VERSION "HNNBNNNYNNNNNNNNNNNNNNNNNNNNNNNNNNNNNNNNNN/4/%%%/4/'%**4NNN///"

NS_ :

BS_:

BU_: Allrad_Haldex AreaView_MQB BAP_Tester Bremse_ABS_MK100 Bremse_ESP_EPB_EBC460Vi Bremse_ESP_EPB_MK100 Bremse_ESP_MK100 Daempfer Gateway_MQB Lenkhilfe_EPS PDC PDC_PLA

BO_ 779 Kombi_01: 8 Gateway_MQB
 SG_ KBI_ABS_Lampe : 0|1@1+ (1.0,0.0) [0.0|1] ""  Bremse_ABS_MK100,Bremse_ESP_EPB_EBC460Vi,Bremse_ESP_EPB_MK100,Bremse_ESP_MK100
 SG_ KBI_ESP_Lampe : 1|1@1+ (1.0,0.0) [0.0|1] ""  Bremse_ABS_MK100,Bremse_ESP_EPB_EBC460Vi,Bremse_ESP_EPB_MK100,Bremse_ESP_MK100
 SG_ KBI_BKL_Lampe : 2|1@1+ (1.0,0.0) [0.0|1] ""  Bremse_ABS_MK100,Bremse_ESP_EPB_EBC460Vi,Bremse_ESP_EPB_MK100,Bremse_ESP_MK100
 SG_ KBI_Airbag_Lampe : 3|1@1+ (1.0,0.0) [0.0|1] ""  Vector__XXX
 SG_ KBI_SILA_gueltig : 4|1@1+ (1.0,0.0) [0.0|1] ""  Bremse_ABS_MK100,Bremse_ESP_EPB_EBC460Vi,Bremse_ESP_EPB_MK100,Bremse_ESP_MK100,Lenkhilfe_EPS
 SG_ KBI_Lenkung_Lampe : 5|1@1+ (1,0) [0|1] ""  Lenkhilfe_EPS
 SG_ KBI_Vorglueh_System_Lampe : 6|1@1+ (1.0,0.0) [0.0|1] ""  Vector__XXX
 SG_ KBI_NV_in_Anzeige : 7|1@1+ (1.0,0.0) [0.0|1] ""  Vector__XXX
 SG_ Kombi_01_BZ : 8|4@1+ (1,0) [0|15] ""  Vector__XXX
 SG_ KBI_Anzeigestatus_ACC : 12|1@1+ (1.0,0.0) [0.0|1] ""  Vector__XXX
 SG_ KBI_Anzeigestatus_GRA : 13|2@1+ (1.0,0.0) [0.0|3] ""  Vector__XXX
 SG_ KBI_Oeldruck_Schalter : 15|1@1+ (1.0,0.0) [0.0|1] ""  Vector__XXX
 SG_ KBI_Tankwarnung : 16|1@1+ (1.0,0.0) [0.0|1] ""  Vector__XXX
 SG_ KBI_MFA_v_Einheit_01 : 17|1@1+ (1.0,0.0) [0.0|1] ""  Vector__XXX
 SG_ KBI_im_Stellgliedtest : 18|1@1+ (1.0,0.0) [0.0|1] ""  Lenkhilfe_EPS
 SG_ KBI_Anzeigefehler_LDW : 19|2@1+ (1.0,0.0) [0.0|3] ""  Vector__XXX
 SG_ KBI_Oeldruckwarnung : 22|1@1+ (1.0,0.0) [0.0|1] ""  Vector__XXX
 SG_ KBI_Handbremse : 23|1@1+ (1.0,0.0) [0.0|1] ""  Allrad_Haldex,Bremse_ABS_MK100,Bremse_ESP_EPB_EBC460Vi,Bremse_ESP_EPB_MK100,Bremse_ESP_MK100,Lenkhilfe_EPS
 SG_ KBI_V_Digital : 24|9@1+ (1,0) [0|511] ""  Vector__XXX
 SG_ KBI_PLA_in_Anzeige : 33|1@1+ (1.0,0.0) [0.0|1] ""  PDC_PLA
 SG_ KBI_Anzeigefehler_NV : 34|1@1+ (1.0,0.0) [0.0|1] ""  Vector__XXX
 SG_ KBI_Anzeigestatus_LIM : 35|2@1+ (1.0,0.0) [0.0|3] ""  Vector__XXX
 SG_ KBI_ARA_in_Anzeige : 37|1@1+ (1.0,0.0) [0.0|1] ""  Vector__XXX
 SG_ KBI_angez_Geschw : 48|10@1+ (0.32,0) [0.00|325.12] "Unit_KiloMeterPerHour"  Lenkhilfe_EPS
 SG_ KBI_Einheit_Tacho : 58|1@1+ (1.0,0.0) [0.0|1] ""  Vector__XXX
 SG_ KBI_Konsistenz_ACC : 59|1@1+ (1.0,0.0) [0.0|1] ""  Vector__XXX
 SG_ KBI_Fehler_Anzeige_ACC : 60|1@1+ (1.0,0.0) [0.0|1] ""  Vector__XXX
 SG_ KBI_Anzeigefehler_SWA : 61|2@1+ (1.0,0.0) [0.0|3] ""  Vector__XXX

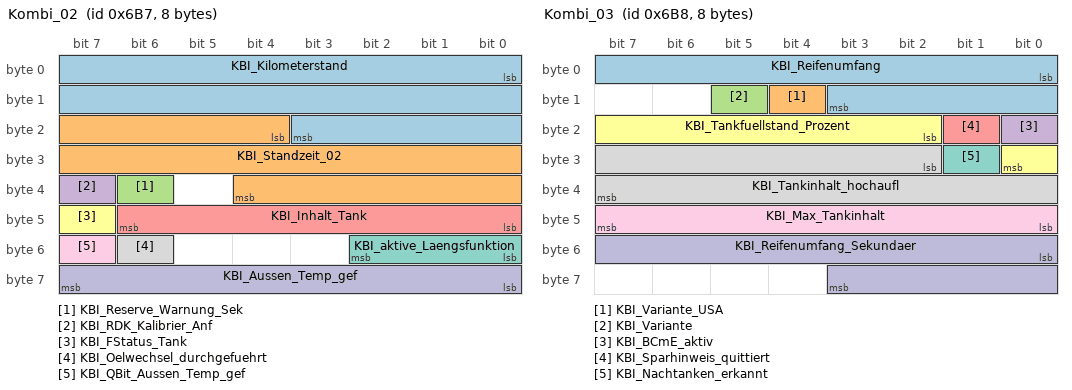
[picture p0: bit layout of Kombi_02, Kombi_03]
BO_ 1719 Kombi_02: 8 Gateway_MQB
 SG_ KBI_Kilometerstand : 0|20@1+ (1,0) [0|1048573] "Unit_KiloMeter"  Vector__XXX
 SG_ KBI_Standzeit_02 : 20|17@1+ (1,0) [0|131068] "Unit_Secon"  Allrad_Haldex,Bremse_ESP_EPB_EBC460Vi,Bremse_ESP_EPB_MK100,Bremse_ESP_MK100
 SG_ KBI_Reserve_Warnung_Sek : 38|1@1+ (1.0,0.0) [0.0|1] ""  Vector__XXX
 SG_ KBI_RDK_Kalibrier_Anf : 39|1@1+ (1.0,0.0) [0.0|1] ""  Vector__XXX
 SG_ KBI_Inhalt_Tank : 40|7@1+ (1,0) [0|125] "Unit_Liter"  Vector__XXX
 SG_ KBI_FStatus_Tank : 47|1@1+ (1.0,0.0) [0.0|1] ""  Vector__XXX
 SG_ KBI_aktive_Laengsfunktion : 48|3@1+ (1.0,0.0) [0.0|7] ""  Vector__XXX
 SG_ KBI_Oelwechsel_durchgefuehrt : 54|1@1+ (1.0,0.0) [0.0|1] ""  Vector__XXX
 SG_ KBI_QBit_Aussen_Temp_gef : 55|1@1+ (1.0,0.0) [0.0|1] ""  Bremse_ABS_MK100,Bremse_ESP_EPB_EBC460Vi,Bremse_ESP_EPB_MK100,Bremse_ESP_MK100,PDC,PDC_PLA
 SG_ KBI_Aussen_Temp_gef : 56|8@1+ (0.5,-50) [-50.0|75.0] "Unit_DegreCelsi"  Bremse_ABS_MK100,Bremse_ESP_EPB_EBC460Vi,Bremse_ESP_EPB_MK100,Bremse_ESP_MK100,PDC,PDC_PLA

BO_ 1720 Kombi_03: 8 Gateway_MQB
 SG_ KBI_Reifenumfang : 0|12@1+ (1,0) [0|4095] "Unit_MilliMeter"  Bremse_ABS_MK100,Bremse_ESP_EPB_EBC460Vi,Bremse_ESP_EPB_MK100,Bremse_ESP_MK100,PDC,PDC_PLA
 SG_ KBI_Variante_USA : 12|1@1+ (1.0,0.0) [0.0|1] ""  Vector__XXX
 SG_ KBI_Variante : 13|1@1+ (1.0,0.0) [0.0|1] ""  Vector__XXX
 SG_ KBI_BCmE_aktiv : 16|1@1+ (1.0,0.0) [0.0|1] ""  Vector__XXX
 SG_ KBI_Sparhinweis_quittiert : 17|1@1+ (1.0,0.0) [0.0|1] ""  Vector__XXX
 SG_ KBI_Tankfuellstand_Prozent : 18|7@1+ (1,0) [0|100] "Unit_PerCent"  Vector__XXX
 SG_ KBI_Nachtanken_erkannt : 25|1@1+ (1.0,0.0) [0.0|1] ""  Vector__XXX
 SG_ KBI_Tankinhalt_hochaufl : 26|14@1+ (0.01,0) [0.00|163.81] "Unit_Liter"  Vector__XXX
 SG_ KBI_Max_Tankinhalt : 40|8@1+ (0.5,0) [0.0|126.5] ""  Vector__XXX
 SG_ KBI_Reifenumfang_Sekundaer : 48|12@1+ (1,0) [0|4095] "Unit_MilliMeter"  Vector__XXX

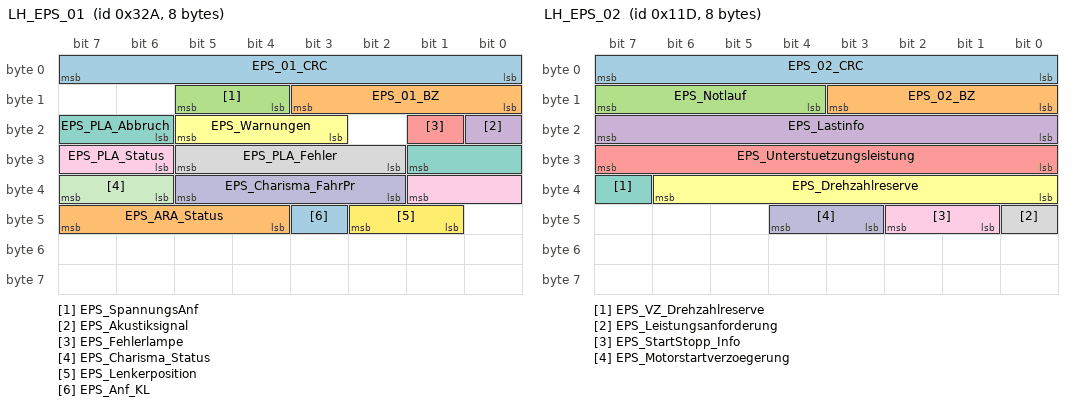
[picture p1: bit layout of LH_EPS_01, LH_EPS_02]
BO_ 810 LH_EPS_01: 8 Lenkhilfe_EPS
 SG_ EPS_01_CRC : 0|8@1+ (1,0) [0|255] ""  Bremse_ESP_EPB_EBC460Vi,Bremse_ESP_EPB_MK100,Bremse_ESP_MK100,Gateway_MQB,PDC,PDC_PLA
 SG_ EPS_01_BZ : 8|4@1+ (1,0) [0|15] ""  Bremse_ESP_EPB_EBC460Vi,Bremse_ESP_EPB_MK100,Bremse_ESP_MK100,Gateway_MQB,PDC,PDC_PLA
 SG_ EPS_SpannungsAnf : 12|2@1+ (1.0,0.0) [0.0|3] ""  Gateway_MQB
 SG_ EPS_Akustiksignal : 16|1@1+ (1.0,0.0) [0.0|1] ""  Gateway_MQB
 SG_ EPS_Fehlerlampe : 17|1@1+ (1.0,0.0) [0.0|1] ""  Gateway_MQB
 SG_ EPS_Warnungen : 19|3@1+ (1.0,0.0) [0.0|7] ""  Gateway_MQB
 SG_ EPS_PLA_Abbruch : 22|4@1+ (1,0) [0|15] ""  Gateway_MQB,PDC_PLA
 SG_ EPS_PLA_Fehler : 26|4@1+ (1,0) [0|15] ""  Gateway_MQB,PDC_PLA
 SG_ EPS_PLA_Status : 30|4@1+ (1.0,0.0) [0.0|15] ""  Bremse_ESP_EPB_EBC460Vi,Bremse_ESP_EPB_MK100,Bremse_ESP_MK100,Gateway_MQB,PDC_PLA
 SG_ EPS_Charisma_FahrPr : 34|4@1+ (1.0,0.0) [0.0|15] ""  Gateway_MQB
 SG_ EPS_Charisma_Status : 38|2@1+ (1.0,0.0) [0.0|3] ""  Gateway_MQB
 SG_ EPS_Lenkerposition : 41|2@1+ (1.0,0.0) [0.0|3] ""  Bremse_ESP_EPB_EBC460Vi,Bremse_ESP_EPB_MK100,Bremse_ESP_MK100,Gateway_MQB
 SG_ EPS_Anf_KL : 43|1@1+ (1.0,0.0) [0.0|1] ""  Gateway_MQB
 SG_ EPS_ARA_Status : 44|4@1+ (1.0,0.0) [0.0|15] ""  Gateway_MQB

BO_ 285 LH_EPS_02: 8 Lenkhilfe_EPS
 SG_ EPS_02_CRC : 0|8@1+ (1,0) [0|255] ""  Vector__XXX
 SG_ EPS_02_BZ : 8|4@1+ (1,0) [0|15] ""  Vector__XXX
 SG_ EPS_Notlauf : 12|4@1+ (1.0,0.0) [0.0|15] ""  Gateway_MQB
 SG_ EPS_Lastinfo : 16|8@1+ (1,0) [0|253] "Unit_Amper"  Gateway_MQB,PDC_PLA
 SG_ EPS_Unterstuetzungsleistung : 24|8@1+ (0.5,0) [0.0|100.0] "Unit_PerCent"  Gateway_MQB,PDC_PLA
 SG_ EPS_Drehzahlreserve : 32|7@1+ (10,0) [0|1000] "Unit_DegreOfArcPerSecon"  Vector__XXX
 SG_ EPS_VZ_Drehzahlreserve : 39|1@1+ (1.0,0.0) [0.0|1] ""  Vector__XXX
 SG_ EPS_Leistungsanforderung : 40|1@1+ (1.0,0.0) [0.0|1] ""  Vector__XXX
 SG_ EPS_StartStopp_Info : 41|2@1+ (1.0,0.0) [0.0|3] ""  Gateway_MQB
 SG_ EPS_Motorstartverzoegerung : 43|2@1+ (1.0,0.0) [0.0|3] ""  Vector__XXX

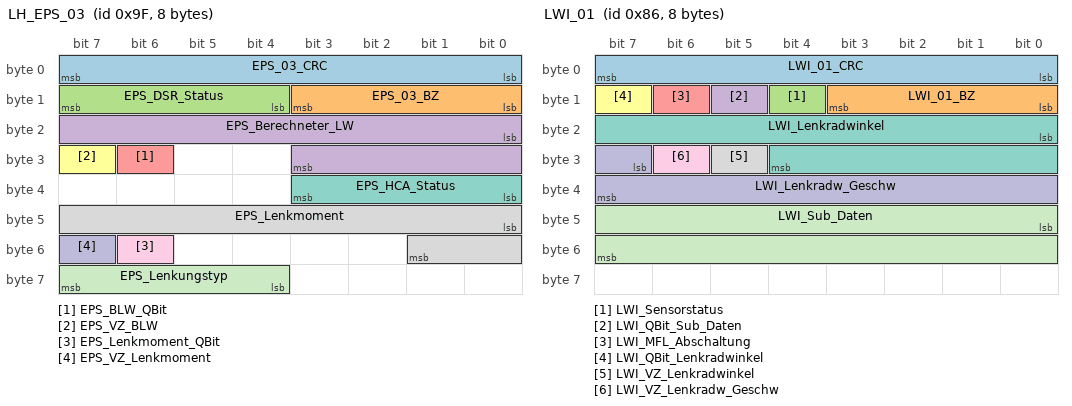
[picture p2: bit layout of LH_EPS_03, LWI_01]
BO_ 159 LH_EPS_03: 8 Lenkhilfe_EPS
 SG_ EPS_03_CRC : 0|8@1+ (1,0) [0|255] ""  Bremse_ABS_MK100,Bremse_ESP_EPB_EBC460Vi,Bremse_ESP_EPB_MK100,Bremse_ESP_MK100,Gateway_MQB,PDC_PLA
 SG_ EPS_03_BZ : 8|4@1+ (1,0) [0|15] ""  Bremse_ABS_MK100,Bremse_ESP_EPB_EBC460Vi,Bremse_ESP_EPB_MK100,Bremse_ESP_MK100,Gateway_MQB,PDC,PDC_PLA
 SG_ EPS_DSR_Status : 12|4@1+ (1.0,0.0) [0.0|15] ""  Bremse_ABS_MK100,Bremse_ESP_EPB_EBC460Vi,Bremse_ESP_EPB_MK100,Bremse_ESP_MK100,Gateway_MQB
 SG_ EPS_Berechneter_LW : 16|12@1+ (0.15,0) [0.00|613.95] "Unit_DegreOfArc"  Bremse_ESP_EPB_EBC460Vi,Bremse_ESP_EPB_MK100,Bremse_ESP_MK100,Gateway_MQB,PDC,PDC_PLA
 SG_ EPS_BLW_QBit : 30|1@1+ (1.0,0.0) [0.0|1] ""  Bremse_ESP_EPB_EBC460Vi,Bremse_ESP_EPB_MK100,Bremse_ESP_MK100,Gateway_MQB,PDC,PDC_PLA
 SG_ EPS_VZ_BLW : 31|1@1+ (1.0,0.0) [0.0|1] ""  Bremse_ESP_EPB_EBC460Vi,Bremse_ESP_EPB_MK100,Bremse_ESP_MK100,Gateway_MQB,PDC,PDC_PLA
 SG_ EPS_HCA_Status : 32|4@1+ (1.0,0.0) [0.0|15] ""  Gateway_MQB
 SG_ EPS_Lenkmoment : 40|10@1+ (0.01,0) [0.00|8.00] "Unit_NewtoMeter"  AreaView_MQB,Bremse_ABS_MK100,Bremse_ESP_EPB_EBC460Vi,Bremse_ESP_EPB_MK100,Bremse_ESP_MK100,Gateway_MQB,PDC,PDC_PLA
 SG_ EPS_Lenkmoment_QBit : 54|1@1+ (1.0,0.0) [0.0|1] ""  AreaView_MQB,Bremse_ABS_MK100,Bremse_ESP_EPB_EBC460Vi,Bremse_ESP_EPB_MK100,Bremse_ESP_MK100,Gateway_MQB,PDC,PDC_PLA
 SG_ EPS_VZ_Lenkmoment : 55|1@1+ (1.0,0.0) [0.0|1] ""  AreaView_MQB,Bremse_ABS_MK100,Bremse_ESP_EPB_EBC460Vi,Bremse_ESP_EPB_MK100,Bremse_ESP_MK100,Gateway_MQB,PDC,PDC_PLA
 SG_ EPS_Lenkungstyp : 60|4@1+ (1.0,0.0) [0.0|15] ""  Bremse_ABS_MK100,Bremse_ESP_EPB_EBC460Vi,Bremse_ESP_EPB_MK100,Bremse_ESP_MK100,Gateway_MQB,PDC,PDC_PLA

BO_ 134 LWI_01: 8 Lenkhilfe_EPS
 SG_ LWI_01_CRC : 0|8@1+ (1,0) [0|255] ""  Bremse_ABS_MK100,Bremse_ESP_EPB_EBC460Vi,Bremse_ESP_EPB_MK100,Bremse_ESP_MK100,Gateway_MQB,PDC,PDC_PLA
 SG_ LWI_01_BZ : 8|4@1+ (1,0) [0|15] ""  Allrad_Haldex,Bremse_ABS_MK100,Bremse_ESP_EPB_EBC460Vi,Bremse_ESP_EPB_MK100,Bremse_ESP_MK100,Gateway_MQB,PDC,PDC_PLA
 SG_ LWI_Sensorstatus : 12|1@1+ (1.0,0.0) [0.0|1] ""  Allrad_Haldex,Bremse_ABS_MK100,Bremse_ESP_EPB_EBC460Vi,Bremse_ESP_EPB_MK100,Bremse_ESP_MK100,Daempfer,Gateway_MQB
 SG_ LWI_QBit_Sub_Daten : 13|1@1+ (1.0,0.0) [0.0|1] ""  Gateway_MQB
 SG_ LWI_MFL_Abschaltung : 14|1@1+ (1.0,0.0) [0.0|1] ""  Gateway_MQB
 SG_ LWI_QBit_Lenkradwinkel : 15|1@1+ (1.0,0.0) [0.0|1] ""  Allrad_Haldex,AreaView_MQB,Bremse_ABS_MK100,Bremse_ESP_EPB_EBC460Vi,Bremse_ESP_EPB_MK100,Bremse_ESP_MK100,Daempfer,Gateway_MQB,PDC,PDC_PLA
 SG_ LWI_Lenkradwinkel : 16|13@1+ (0.1,0) [0.0|800.0] "Unit_DegreOfArc"  Allrad_Haldex,AreaView_MQB,Bremse_ABS_MK100,Bremse_ESP_EPB_EBC460Vi,Bremse_ESP_EPB_MK100,Bremse_ESP_MK100,Daempfer,Gateway_MQB,PDC,PDC_PLA
 SG_ LWI_VZ_Lenkradwinkel : 29|1@1+ (1.0,0.0) [0.0|1] ""  Allrad_Haldex,AreaView_MQB,Bremse_ABS_MK100,Bremse_ESP_EPB_EBC460Vi,Bremse_ESP_EPB_MK100,Bremse_ESP_MK100,Daempfer,Gateway_MQB,PDC,PDC_PLA
 SG_ LWI_VZ_Lenkradw_Geschw : 30|1@1+ (1.0,0.0) [0.0|1] ""  Bremse_ABS_MK100,Bremse_ESP_EPB_EBC460Vi,Bremse_ESP_EPB_MK100,Bremse_ESP_MK100,Gateway_MQB
 SG_ LWI_Lenkradw_Geschw : 31|9@1+ (5,0) [0|2500] "Unit_DegreOfArcPerSecon"  Bremse_ABS_MK100,Bremse_ESP_EPB_EBC460Vi,Bremse_ESP_EPB_MK100,Bremse_ESP_MK100,Gateway_MQB
 SG_ LWI_Sub_Daten : 40|16@1+ (1,0) [0|65535] ""  Gateway_MQB

BO_ 917 LWR_AFS_01: 8 Gateway_MQB
 SG_ AFS_Abbiegelicht_li_Anf : 0|1@1+ (1.0,0.0) [0.0|1] ""  Vector__XXX
 SG_ AFS_Abbiegelicht_re_Anf : 1|1@1+ (1.0,0.0) [0.0|1] ""  Vector__XXX
 SG_ AFS_Abbiegelicht_Dimm_Anf : 2|1@1+ (1.0,0.0) [0.0|1] ""  Vector__XXX
 SG_ AFS_Verfuegbarkeit_GLW : 3|1@1+ (1.0,0.0) [0.0|1] ""  Vector__XXX
 SG_ AFS_Status_adaptive_LV : 4|1@1+ (1.0,0.0) [0.0|1] ""  Vector__XXX
 SG_ AFS_Fernlicht_li_defekt : 5|1@1+ (1.0,0.0) [0.0|1] ""  Vector__XXX
 SG_ AFS_Fernlicht_re_defekt : 6|1@1+ (1.0,0.0) [0.0|1] ""  Vector__XXX
 SG_ AFS_Fernlicht_Status : 7|1@1+ (1.0,0.0) [0.0|1] ""  Vector__XXX
 SG_ LWR_AFS_01_BZ : 8|4@1+ (1,0) [0|15] ""  Vector__XXX
 SG_ AFS_Lampe : 12|1@1+ (1.0,0.0) [0.0|1] ""  Vector__XXX
 SG_ LWR_Lampe : 13|1@1+ (1.0,0.0) [0.0|1] ""  Vector__XXX
 SG_ AFS_Fehlertext : 14|1@1+ (1.0,0.0) [0.0|1] ""  Vector__XXX
 SG_ AFS_LED_Blinkmode : 15|1@1+ (1.0,0.0) [0.0|1] ""  Vector__XXX
 SG_ LWR_Touristenmodus_aktiv : 16|1@1+ (1.0,0.0) [0.0|1] ""  Vector__XXX
 SG_ AFS_Charisma_FahrPr : 17|4@1+ (1.0,0.0) [0.0|15] ""  Vector__XXX
 SG_ AFS_Charisma_Status : 21|2@1+ (1.0,0.0) [0.0|3] ""  Vector__XXX
 SG_ AFS_Allwetterlicht : 24|1@1+ (1.0,0.0) [0.0|1] ""  Vector__XXX
 SG_ LWR_Touristenmodus_verbaut : 25|1@1+ (1.0,0.0) [0.0|1] ""  Vector__XXX
 SG_ AFS_adaptive_LV_verbaut : 26|1@1+ (1.0,0.0) [0.0|1] ""  Vector__XXX
 SG_ LWR_Reisemodus_Texte : 27|2@1+ (1.0,0.0) [0.0|3] ""  Vector__XXX
 SG_ GLW_Sensor_blockiert : 29|1@1+ (1.0,0.0) [0.0|1] ""  Vector__XXX
 SG_ LWR_Pos_Schrittmotor : 32|8@1+ (0.4,0) [0.0|100.0] "Unit_PerCent"  Vector__XXX
 SG_ LWR_Hoehenwert_VL : 40|8@1+ (1,-127) [-127|126] ""  Bremse_ESP_EPB_EBC460Vi,Bremse_ESP_EPB_MK100,Bremse_ESP_MK100
 SG_ LWR_Hoehenwert_HL : 48|8@1+ (1,-127) [-127|126] ""  Bremse_ESP_EPB_EBC460Vi,Bremse_ESP_EPB_MK100,Bremse_ESP_MK100
 SG_ AFS_Ersatzlicht_Links : 56|1@1+ (1.0,0.0) [0.0|1] ""  Vector__XXX
 SG_ AFS_Ersatzlicht_Rechts : 57|1@1+ (1.0,0.0) [0.0|1] ""  Vector__XXX
 SG_ LWR_AFS_Grundeinstellung : 58|1@1+ (1.0,0.0) [0.0|1] ""  Vector__XXX
 SG_ LWR_AFS_Parametrisierung : 59|1@1+ (1.0,0.0) [0.0|1] ""  Vector__XXX
 SG_ LWR_Initialisierungslauf : 60|1@1+ (1.0,0.0) [0.0|1] ""  Vector__XXX
 SG_ LWR_Sicherheitsposition : 61|1@1+ (1.0,0.0) [0.0|1] ""  Vector__XXX
 SG_ LWR_Modus : 62|1@1+ (1.0,0.0) [0.0|1] ""  Vector__XXX

BO_ 1600 Motor_07: 8 Gateway_MQB
 SG_ MO_QBit_Ansaugluft_Temp : 0|1@1+ (1.0,0.0) [0.0|1] ""  Bremse_ESP_EPB_EBC460Vi,Bremse_ESP_EPB_MK100,Bremse_ESP_MK100
 SG_ MO_QBit_Oel_Temp : 1|1@1+ (1.0,0.0) [0.0|1] ""  Bremse_ESP_EPB_EBC460Vi,Bremse_ESP_EPB_MK100
 SG_ MO_QBit_Kuehlmittel_Temp : 2|1@1+ (1.0,0.0) [0.0|1] ""  Vector__XXX
 SG_ MO_KL15_Abschaltempfehlung : 3|1@1+ (1.0,0.0) [0.0|1] ""  Vector__XXX
 SG_ MO_HYB_Fehler_HV_Netz : 4|1@1+ (1.0,0.0) [0.0|1] ""  Vector__XXX
 SG_ MO_aktives_Getriebeheizen : 5|1@1+ (1.0,0.0) [0.0|1] ""  Vector__XXX
 SG_ MO_Absperrventil_oeffnen : 6|2@1+ (1.0,0.0) [0.0|3] ""  Vector__XXX
 SG_ MO_Ansaugluft_Temp : 8|8@1+ (0.75,-48) [-48.00|141.75] "Unit_DegreCelsi"  Bremse_ESP_EPB_EBC460Vi,Bremse_ESP_EPB_MK100,Bremse_ESP_MK100
 SG_ MO_Oel_Temp : 16|8@1+ (1,-60) [-60|192] "Unit_DegreCelsi"  Bremse_ESP_EPB_EBC460Vi,Bremse_ESP_EPB_MK100
 SG_ MO_Kuehlmittel_Temp : 24|8@1+ (0.75,-48) [-48.00|141.75] "Unit_DegreCelsi"  Vector__XXX
 SG_ MO_Hoeheninfo : 32|8@1+ (0.00781,0) [0.00000|1.98374] ""  Bremse_ABS_MK100,Bremse_ESP_EPB_EBC460Vi,Bremse_ESP_EPB_MK100,Bremse_ESP_MK100
 SG_ MO_Kennfeldk : 40|1@1+ (1.0,0.0) [0.0|1] ""  Vector__XXX
 SG_ MO_Versionsinfo_02 : 41|5@1+ (1.0,0.0) [0.0|31] ""  Vector__XXX
 SG_ MO_QBit_Hoeheninfo : 46|1@1+ (1.0,0.0) [0.0|1] ""  Vector__XXX
 SG_ MO_Getriebe_kuehlen : 47|1@1+ (1.0,0.0) [0.0|1] ""  Vector__XXX
 SG_ MO_Mom_Traegheit_02 : 48|5@1+ (0.01,0) [0.00|0.31] "Unit_KiloGramMeterSquar"  Bremse_ESP_EPB_EBC460Vi,Bremse_ESP_EPB_MK100,Bremse_ESP_MK100
 SG_ MO_Heizungspumpenansteuerung : 53|4@1+ (10,0) [0|100] "Unit_PerCent"  Vector__XXX
 SG_ MO_SpannungsAnf : 57|1@1+ (1.0,0.0) [0.0|1] ""  Vector__XXX
 SG_ MO_Nachlaufzeit_Heizungspumpe : 58|6@1+ (15,0) [0|945] "Unit_Secon"  Vector__XXX

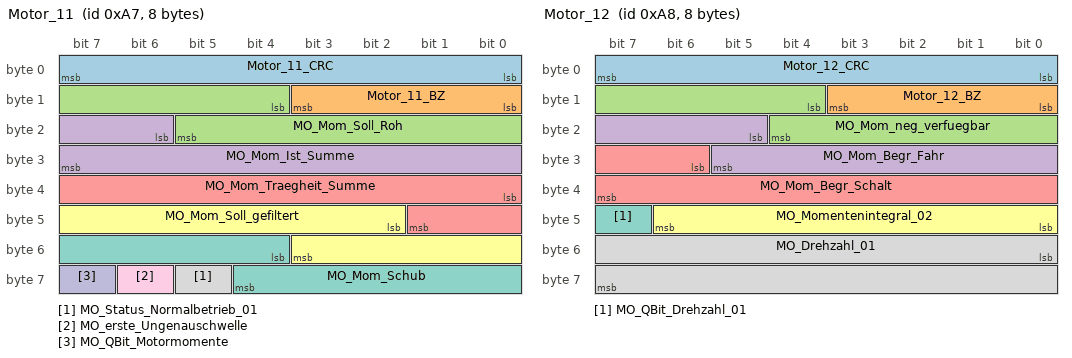
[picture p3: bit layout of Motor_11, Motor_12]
BO_ 167 Motor_11: 8 Gateway_MQB
 SG_ Motor_11_CRC : 0|8@1+ (1,0) [0|255] ""  Bremse_ABS_MK100,Bremse_ESP_EPB_EBC460Vi,Bremse_ESP_EPB_MK100,Bremse_ESP_MK100,Lenkhilfe_EPS
 SG_ Motor_11_BZ : 8|4@1+ (1,0) [0|15] ""  Bremse_ABS_MK100,Bremse_ESP_EPB_EBC460Vi,Bremse_ESP_EPB_MK100,Bremse_ESP_MK100,Lenkhilfe_EPS
 SG_ MO_Mom_Soll_Roh : 12|10@1+ (1,-509) [-509|509] ""  Allrad_Haldex,Bremse_ABS_MK100,Bremse_ESP_EPB_EBC460Vi,Bremse_ESP_EPB_MK100,Bremse_ESP_MK100,Lenkhilfe_EPS
 SG_ MO_Mom_Ist_Summe : 22|10@1+ (1,-509) [-509|509] ""  Allrad_Haldex,Bremse_ABS_MK100,Bremse_ESP_EPB_EBC460Vi,Bremse_ESP_EPB_MK100,Bremse_ESP_MK100,Lenkhilfe_EPS
 SG_ MO_Mom_Traegheit_Summe : 32|10@1+ (1,-509) [-509|509] ""  Bremse_ABS_MK100,Bremse_ESP_EPB_EBC460Vi,Bremse_ESP_EPB_MK100,Bremse_ESP_MK100,Lenkhilfe_EPS
 SG_ MO_Mom_Soll_gefiltert : 42|10@1+ (1,-509) [-509|509] ""  Vector__XXX
 SG_ MO_Mom_Schub : 52|9@1+ (1,-509) [-509|0] ""  Allrad_Haldex,Bremse_ABS_MK100,Bremse_ESP_EPB_EBC460Vi,Bremse_ESP_EPB_MK100,Bremse_ESP_MK100,Lenkhilfe_EPS
 SG_ MO_Status_Normalbetrieb_01 : 61|1@1+ (1.0,0.0) [0.0|1] ""  Allrad_Haldex
 SG_ MO_erste_Ungenauschwelle : 62|1@1+ (1.0,0.0) [0.0|1] ""  Vector__XXX
 SG_ MO_QBit_Motormomente : 63|1@1+ (1.0,0.0) [0.0|1] ""  Bremse_ABS_MK100,Bremse_ESP_EPB_EBC460Vi,Bremse_ESP_EPB_MK100,Bremse_ESP_MK100,Lenkhilfe_EPS

BO_ 168 Motor_12: 8 Gateway_MQB
 SG_ Motor_12_CRC : 0|8@1+ (1,0) [0|255] ""  Bremse_ABS_MK100,Bremse_ESP_EPB_EBC460Vi,Bremse_ESP_EPB_MK100,Bremse_ESP_MK100,Lenkhilfe_EPS
 SG_ Motor_12_BZ : 8|4@1+ (1,0) [0|15] ""  Bremse_ABS_MK100,Bremse_ESP_EPB_EBC460Vi,Bremse_ESP_EPB_MK100,Bremse_ESP_MK100,Lenkhilfe_EPS
 SG_ MO_Mom_neg_verfuegbar : 12|9@1+ (1,-509) [-509|0] ""  Vector__XXX
 SG_ MO_Mom_Begr_Fahr : 21|9@1+ (1,0) [0|509] ""  Bremse_ESP_EPB_MK100,Bremse_ESP_MK100
 SG_ MO_Mom_Begr_Schalt : 30|10@1+ (1,-509) [-509|509] ""  Vector__XXX
 SG_ MO_Momentenintegral_02 : 40|7@1+ (1,0) [0|100] "Unit_PerCent"  Vector__XXX
 SG_ MO_QBit_Drehzahl_01 : 47|1@1+ (1.0,0.0) [0.0|1] ""  Bremse_ABS_MK100,Bremse_ESP_EPB_EBC460Vi,Bremse_ESP_EPB_MK100,Bremse_ESP_MK100,Lenkhilfe_EPS,PDC,PDC_PLA
 SG_ MO_Drehzahl_01 : 48|16@1+ (0.25,0) [0.00|16383.00] "Unit_MinutInver"  Allrad_Haldex,Bremse_ABS_MK100,Bremse_ESP_EPB_EBC460Vi,Bremse_ESP_EPB_MK100,Bremse_ESP_MK100,Lenkhilfe_EPS,PDC_PLA

BO_ 958 Motor_14: 8 Gateway_MQB
 SG_ Motor_14_CRC : 0|8@1+ (1,0) [0|255] ""  Vector__XXX
 SG_ Motor_14_BZ : 8|4@1+ (1,0) [0|15] ""  Vector__XXX
 SG_ MO_StartStopp_Status : 12|2@1+ (1.0,0.0) [0.0|3] ""  Bremse_ESP_EPB_EBC460Vi,Bremse_ESP_EPB_MK100,Bremse_ESP_MK100,Lenkhilfe_EPS,PDC,PDC_PLA
 SG_ MO_StartStopp_Wiederstart : 14|1@1+ (1.0,0.0) [0.0|1] ""  Bremse_ESP_EPB_EBC460Vi,Bremse_ESP_EPB_MK100,Bremse_ESP_MK100,Lenkhilfe_EPS,PDC,PDC_PLA
 SG_ MO_StartStopp_Motorstopp : 15|1@1+ (1.0,0.0) [0.0|1] ""  Bremse_ESP_EPB_EBC460Vi,Bremse_ESP_EPB_MK100,Bremse_ESP_MK100,Lenkhilfe_EPS,PDC_PLA
 SG_ MO_Freig_Reku : 16|2@1+ (1.0,0.0) [0.0|3] ""  Vector__XXX
 SG_ MO_Kl_75 : 18|1@1+ (1.0,0.0) [0.0|1] ""  Bremse_ESP_EPB_EBC460Vi,Bremse_ESP_EPB_MK100,Lenkhilfe_EPS,PDC,PDC_PLA
 SG_ MO_Kl_50 : 19|1@1+ (1.0,0.0) [0.0|1] ""  Bremse_ESP_EPB_EBC460Vi,Bremse_ESP_EPB_MK100,Lenkhilfe_EPS
 SG_ MO_Gangposition : 20|4@1+ (1.0,0.0) [0.0|15] ""  Allrad_Haldex,Bremse_ESP_EPB_EBC460Vi,Bremse_ESP_EPB_MK100
 SG_ MO_StartStopp_Fahrerwunsch : 24|2@1+ (1.0,0.0) [0.0|3] ""  Bremse_ESP_EPB_EBC460Vi,Bremse_ESP_EPB_MK100,Bremse_ESP_MK100,Lenkhilfe_EPS,PDC_PLA
 SG_ MO_HYB_Fahrbereitschaft : 26|1@1+ (1.0,0.0) [0.0|1] ""  Bremse_ESP_EPB_MK100,Lenkhilfe_EPS,PDC_PLA
 SG_ MO_Ext_E_Fahrt_aktiv : 27|1@1+ (1.0,0.0) [0.0|1] ""  Vector__XXX
 SG_ MO_Fahrer_bremst : 28|1@1+ (1.0,0.0) [0.0|1] ""  Allrad_Haldex,Bremse_ESP_EPB_EBC460Vi,Bremse_ESP_EPB_MK100,Bremse_ESP_MK100,PDC_PLA
 SG_ MO_QBit_Fahrer_bremst : 29|1@1+ (1.0,0.0) [0.0|1] ""  Allrad_Haldex,Bremse_ESP_EPB_EBC460Vi,Bremse_ESP_EPB_MK100,Bremse_ESP_MK100,PDC_PLA
 SG_ MO_BLS : 30|1@1+ (1.0,0.0) [0.0|1] ""  Bremse_ABS_MK100,Bremse_ESP_EPB_EBC460Vi,Bremse_ESP_EPB_MK100,Bremse_ESP_MK100,Daempfer,Lenkhilfe_EPS,PDC_PLA
 SG_ MO_Konsistenz_Bremsped : 31|1@1+ (1.0,0.0) [0.0|1] ""  Vector__XXX
 SG_ MO_Timeout_ESP : 32|1@1+ (1.0,0.0) [0.0|1] ""  Bremse_ABS_MK100,Bremse_ESP_EPB_EBC460Vi,Bremse_ESP_EPB_MK100,Bremse_ESP_MK100
 SG_ MO_Klima_Eingr : 33|2@1+ (1.0,0.0) [0.0|3] ""  Vector__XXX
 SG_ MO_Aussp_Anlass : 35|1@1+ (1.0,0.0) [0.0|1] ""  Vector__XXX
 SG_ MO_Freig_Anlass : 36|1@1+ (1.0,0.0) [0.0|1] ""  Lenkhilfe_EPS
 SG_ MO_Kuppl_schalter : 37|1@1+ (1.0,0.0) [0.0|1] ""  Allrad_Haldex,Bremse_ABS_MK100,Bremse_ESP_EPB_EBC460Vi,Bremse_ESP_EPB_MK100,Bremse_ESP_MK100,PDC_PLA
 SG_ MO_Interlock : 38|1@1+ (1.0,0.0) [0.0|1] ""  Bremse_ESP_EPB_EBC460Vi,Bremse_ESP_EPB_MK100
 SG_ MO_Motor_laeuft : 39|1@1+ (1.0,0.0) [0.0|1] ""  Bremse_ABS_MK100,Bremse_ESP_EPB_EBC460Vi,Bremse_ESP_EPB_MK100,Bremse_ESP_MK100
 SG_ MO_Kickdown : 40|1@1+ (1.0,0.0) [0.0|1] ""  Lenkhilfe_EPS,PDC,PDC_PLA
 SG_ MO_QBit_KL_75 : 41|1@1+ (1.0,0.0) [0.0|1] ""  Lenkhilfe_EPS
 SG_ MO_EKlKomLeiRed : 42|2@1+ (1.0,0.0) [0.0|3] ""  Vector__XXX
 SG_ MO_Handshake_STH : 44|1@1+ (1.0,0.0) [0.0|1] ""  Vector__XXX
 SG_ MO_BKV_Unterdruckwarnung : 45|1@1+ (1.0,0.0) [0.0|1] ""  Vector__XXX
 SG_ MO_Freigabe_Segeln : 46|1@1+ (1.0,0.0) [0.0|1] ""  Vector__XXX
 SG_ MO_PTC_Status : 47|3@1+ (1.0,0.0) [0.0|7] ""  Vector__XXX
 SG_ MO_QBit_Gangposition : 50|1@1+ (1.0,0.0) [0.0|1] ""  Bremse_ESP_EPB_EBC460Vi,Bremse_ESP_EPB_MK100
 SG_ MO_Signalquelle_Gangposition : 51|1@1+ (1.0,0.0) [0.0|1] ""  Bremse_ESP_EPB_EBC460Vi,Bremse_ESP_EPB_MK100
 SG_ MO_Remotestart_Betrieb : 52|1@1+ (1.0,0.0) [0.0|1] ""  Vector__XXX
 SG_ MO_Remotestart_moeglich : 53|1@1+ (1.0,0.0) [0.0|1] ""  Vector__XXX
 SG_ MO_FMAus_aktiv : 55|1@1+ (1.0,0.0) [0.0|1] ""  Bremse_ESP_EPB_MK100
 SG_ MO_FMAus_Startvariante : 56|2@1+ (1.0,0.0) [0.0|3] ""  Vector__XXX
 SG_ MO_BMS_NV_Anf_stuetzen : 58|1@1+ (1.0,0.0) [0.0|1] ""  Vector__XXX
 SG_ MO_Zylinderabschaltung : 59|2@1+ (1.0,0.0) [0.0|3] ""  Bremse_ESP_EPB_EBC460Vi,Bremse_ESP_EPB_MK100,Bremse_ESP_MK100
 SG_ MO_HYB_VM_aktiv : 61|1@1+ (1.0,0.0) [0.0|1] ""  Vector__XXX
 SG_ MO_StartVorauss_erfuellt : 62|2@1+ (1.0,0.0) [0.0|3] ""  Vector__XXX

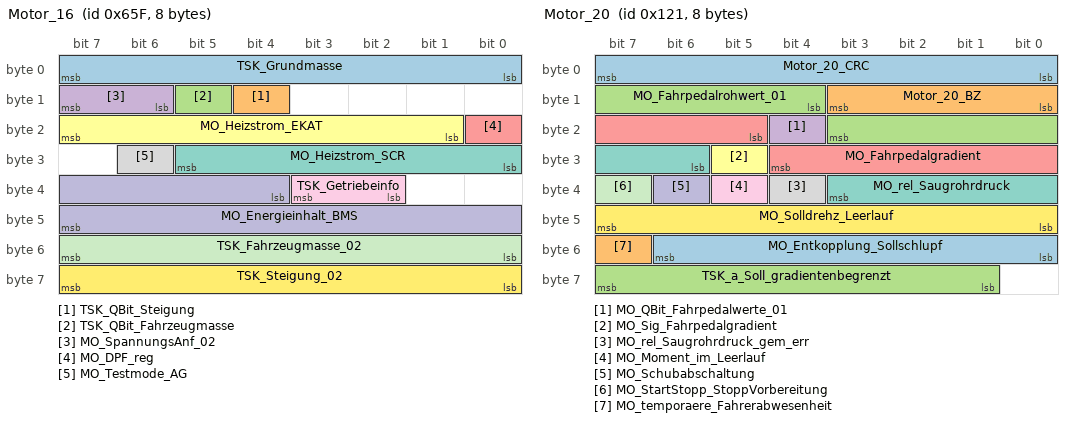
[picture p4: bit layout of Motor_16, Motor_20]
BO_ 1631 Motor_16: 8 Gateway_MQB
 SG_ TSK_Grundmasse : 0|8@1+ (32,0) [0|8128] "Unit_KiloGram"  Vector__XXX
 SG_ TSK_QBit_Steigung : 12|1@1+ (1.0,0.0) [0.0|1] ""  Vector__XXX
 SG_ TSK_QBit_Fahrzeugmasse : 13|1@1+ (1.0,0.0) [0.0|1] ""  Bremse_ESP_EPB_EBC460Vi,Bremse_ESP_EPB_MK100,Bremse_ESP_MK100
 SG_ MO_SpannungsAnf_02 : 14|2@1+ (1.0,0.0) [0.0|3] ""  Vector__XXX
 SG_ MO_DPF_reg : 16|1@1+ (1.0,0.0) [0.0|1] ""  Vector__XXX
 SG_ MO_Heizstrom_EKAT : 17|7@1+ (1,0) [0|126] "Unit_Amper"  Vector__XXX
 SG_ MO_Heizstrom_SCR : 24|6@1+ (1,0) [0|62] "Unit_Amper"  Vector__XXX
 SG_ MO_Testmode_AG : 30|1@1+ (1.0,0.0) [0.0|1] ""  Vector__XXX
 SG_ TSK_Getriebeinfo : 34|2@1+ (1.0,0.0) [0.0|3] ""  Vector__XXX
 SG_ MO_Energieinhalt_BMS : 36|12@1+ (25,0) [0|102325] "Unit_WattHour"  Vector__XXX
 SG_ TSK_Fahrzeugmasse_02 : 48|8@1+ (32,0) [0|8128] "Unit_KiloGram"  Bremse_ESP_EPB_EBC460Vi,Bremse_ESP_EPB_MK100,Bremse_ESP_MK100
 SG_ TSK_Steigung_02 : 56|8@1+ (0.8,-101.6) [-100.8|101.6] "Unit_PerCent"  PDC,PDC_PLA

BO_ 1648 Motor_18: 8 Gateway_MQB
 SG_ MO_max_Ladedruck : 0|6@1+ (0.1,0) [0.0|6.3] "Unit_Bar"  Vector__XXX
 SG_ MO_ANC_Kennfeld_Anf : 6|2@1+ (1.0,0.0) [0.0|3] ""  Vector__XXX
 SG_ MO_Bremslicht_Reku : 8|1@1+ (1.0,0.0) [0.0|1] ""  Vector__XXX
 SG_ MO_StartStopp_PopUp : 9|2@1+ (1.0,0.0) [0.0|3] ""  Vector__XXX
 SG_ MO1_Sperr_Info_WFS : 11|1@1+ (1.0,0.0) [0.0|1] ""  Vector__XXX
 SG_ MO1_Freigabe_Info_WFS : 12|1@1+ (1.0,0.0) [0.0|1] ""  Vector__XXX
 SG_ MO_EPCL : 13|3@1+ (1.0,0.0) [0.0|7] ""  Vector__XXX
 SG_ MO_Zylabsch_Texte_02 : 16|4@1+ (1.0,0.0) [0.0|15] ""  Vector__XXX
 SG_ MO_Fahrzeugtyp : 20|3@1+ (1.0,0.0) [0.0|7] ""  Bremse_ESP_EPB_MK100
 SG_ MO_NMAX_Schaltanzeige : 23|9@1+ (25,0) [0|12775] "Unit_MinutInver"  Vector__XXX
 SG_ MO_Abstellzeit : 32|8@1+ (8,0) [0|2024] "Unit_Minut"  Vector__XXX
 SG_ MO_Abstellzeit_Status : 40|2@1+ (1.0,0.0) [0.0|3] ""  Vector__XXX
 SG_ MO1_Freigabe_Verfallsinfo_WFS : 42|1@1+ (1.0,0.0) [0.0|1] ""  Vector__XXX
 SG_ MO_Hybrid_StartStopp_LED : 43|2@1+ (1.0,0.0) [0.0|3] ""  Vector__XXX
 SG_ MO_Fehler_Zylabsch : 45|2@1+ (1.0,0.0) [0.0|3] ""  Vector__XXX
 SG_ MO_Anzahl_Abgesch_Zyl : 47|3@1+ (1.0,0.0) [0.0|7] ""  Vector__XXX
 SG_ MO_Zylabsch_Texte : 50|2@1+ (1.0,0.0) [0.0|3] ""  Vector__XXX
 SG_ MO_Ethanol_BS_Texte : 52|3@1+ (1.0,0.0) [0.0|7] ""  Vector__XXX
 SG_ MO_Drehzahl_Warnung : 55|1@1+ (1.0,0.0) [0.0|1] ""  Vector__XXX
 SG_ MO_obere_Drehzahlgrenze : 56|8@1+ (50,0) [50|12750] "Unit_MinutInver"  Vector__XXX

BO_ 289 Motor_20: 8 Gateway_MQB
 SG_ Motor_20_CRC : 0|8@1+ (1,0) [0|255] ""  Bremse_ABS_MK100,Bremse_ESP_EPB_EBC460Vi,Bremse_ESP_EPB_MK100,Bremse_ESP_MK100
 SG_ Motor_20_BZ : 8|4@1+ (1,0) [0|15] ""  Bremse_ABS_MK100,Bremse_ESP_EPB_EBC460Vi,Bremse_ESP_EPB_MK100,Bremse_ESP_MK100
 SG_ MO_Fahrpedalrohwert_01 : 12|8@1+ (0.4,0) [0.0|101.6] "Unit_PerCent"  Allrad_Haldex,Bremse_ABS_MK100,Bremse_ESP_EPB_EBC460Vi,Bremse_ESP_EPB_MK100,Bremse_ESP_MK100,Daempfer,Lenkhilfe_EPS,PDC,PDC_PLA
 SG_ MO_QBit_Fahrpedalwerte_01 : 20|1@1+ (1.0,0.0) [0.0|1] ""  Allrad_Haldex,Bremse_ABS_MK100,Bremse_ESP_EPB_EBC460Vi,Bremse_ESP_EPB_MK100,Bremse_ESP_MK100,Daempfer,Lenkhilfe_EPS
 SG_ MO_Fahrpedalgradient : 21|8@1+ (25,0) [0|6350] "Unit_PerCentPerSecon"  Bremse_ESP_EPB_EBC460Vi,Bremse_ESP_EPB_MK100,Bremse_ESP_MK100,PDC,PDC_PLA
 SG_ MO_Sig_Fahrpedalgradient : 29|1@1+ (1.0,0.0) [0.0|1] ""  Bremse_ESP_EPB_EBC460Vi,Bremse_ESP_EPB_MK100,Bremse_ESP_MK100,PDC,PDC_PLA
 SG_ MO_rel_Saugrohrdruck : 30|6@1+ (18,0) [0|1116] "Unit_MilliBar"  Bremse_ESP_EPB_EBC460Vi,Bremse_ESP_EPB_MK100,Bremse_ESP_MK100
 SG_ MO_rel_Saugrohrdruck_gem_err : 36|1@1+ (1.0,0.0) [0.0|1] ""  Bremse_ESP_EPB_EBC460Vi,Bremse_ESP_EPB_MK100,Bremse_ESP_MK100
 SG_ MO_Moment_im_Leerlauf : 37|1@1+ (1.0,0.0) [0.0|1] ""  Bremse_ABS_MK100,Bremse_ESP_EPB_EBC460Vi,Bremse_ESP_EPB_MK100,Bremse_ESP_MK100
 SG_ MO_Schubabschaltung : 38|1@1+ (1.0,0.0) [0.0|1] ""  Bremse_ESP_EPB_EBC460Vi,Bremse_ESP_EPB_MK100,Bremse_ESP_MK100
 SG_ MO_StartStopp_StoppVorbereitung : 39|1@1+ (1.0,0.0) [0.0|1] ""  Vector__XXX
 SG_ MO_Solldrehz_Leerlauf : 40|8@1+ (10,0) [0|2540] "Unit_MinutInver"  Bremse_ESP_EPB_EBC460Vi,Bremse_ESP_EPB_MK100,Bremse_ESP_MK100
 SG_ MO_Entkopplung_Sollschlupf : 48|7@1+ (20,0) [0|2480] "Unit_MinutInver"  Vector__XXX
 SG_ MO_temporaere_Fahrerabwesenheit : 55|1@1+ (1.0,0.0) [0.0|1] ""  Vector__XXX
 SG_ TSK_a_Soll_gradientenbegrenzt : 57|7@1+ (0.1,-7.2) [-7.2|5.4] "Unit_MeterPerSeconSquar"  Vector__XXX

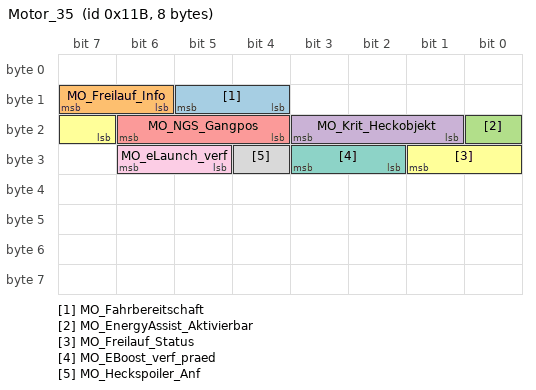
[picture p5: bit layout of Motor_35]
BO_ 283 Motor_35: 8 Gateway_MQB
 SG_ MO_Fahrbereitschaft : 12|2@1+ (1.0,0.0) [0.0|3] ""  Vector__XXX
 SG_ MO_Freilauf_Info : 14|2@1+ (1.0,0.0) [0.0|3] ""  Vector__XXX
 SG_ MO_EnergyAssist_Aktivierbar : 16|1@1+ (1.0,0.0) [0.0|1] ""  Vector__XXX
 SG_ MO_Krit_Heckobjekt : 17|3@1+ (1.0,0.0) [0.0|7] ""  Vector__XXX
 SG_ MO_NGS_Gangpos : 20|3@1+ (1.0,0.0) [0.0|7] ""  Bremse_ESP_EPB_EBC460Vi,Bremse_ESP_EPB_MK100
 SG_ MO_Freilauf_Status : 23|3@1+ (1.0,0.0) [0.0|7] ""  Vector__XXX
 SG_ MO_EBoost_verf_praed : 26|2@1+ (1.0,0.0) [0.0|3] ""  Vector__XXX
 SG_ MO_Heckspoiler_Anf : 28|1@1+ (1.0,0.0) [0.0|1] ""  Vector__XXX
 SG_ MO_eLaunch_verf : 29|2@1+ (1.0,0.0) [0.0|3] ""  Vector__XXX

CM_ BO_ 779 "MQB";
CM_ BO_ 810 "MQB: 50ms (für CAN-SG), geändertes Charisma, Entfall KD-Fehler";
CM_ BO_ 159 "C7 und B8

Zykluszeit 10ms zyklisch";
CM_ BO_ 134 "ab MQB mit CRC in Byte 1";
CM_ BO_ 917 "MLB";
CM_ BO_ 1600 "ab MQB mit QBit Höheneinfo und MO_Versionsinfo_02";
CM_ BO_ 168 "Teil 2 neue Momentenschnittstelle MLB";
CM_ BO_ 1648 "Kombischnittstelle";

CM_ SG_ 779 KBI_ABS_Lampe "ABS-Sicherheits-Lampe wurde eingeschaltet.";
CM_ SG_ 779 KBI_Airbag_Lampe "Airbag Sicherheits-Lampe wurde eingeschaltet ";
CM_ SG_ 779 KBI_angez_Geschw "Im Tacho angezeigte Geschwindigkeit inklusive der Voreilung

";
CM_ SG_ 779 KBI_Anzeigefehler_NV "Über dieses Signal teilt das Kombiinstrument dem Nightvision-Steuergerät mit, dass ein Fehler vom Kombiinstrument diagnostiziert wurde, der zur Abschaltung der Nightvision-Funktion führen muss.";
CM_ SG_ 779 KBI_Anzeigefehler_SWA "Signal bezieht sich nur auf die SWA-Lampe, Vorhalt für Kombis mit SWA-Lampe. ";
CM_ SG_ 779 KBI_Anzeigestatus_ACC "Status der ACC-Anzeige im nicht permanenten Displaybereich";
CM_ SG_ 779 KBI_Anzeigestatus_GRA "Anzeigestatus der GRA High Wunschgeschwindigkeitsanzeige im Kombiinstrument.
Bei VW bedeutet 'nicht vorhanden' GRA-low fähig (LED immer verbaut).
0 = nicht vorhanden
1 = Wunschgeschwindigkeits-Anzeigemöglichkeit vorhanden
2 = reserviert
3 = Fehler (B";
CM_ SG_ 779 KBI_Anzeigestatus_LIM "Anzeigestatus der Speedlimiter Wunschgeschwindigkeitsanzeige im Kombiinstrument (permanenter Anzeigebereich)
0 = nicht vorhanden
1 = Wunschgeschwindigkeits-Anzeigemöglichkeit vorhanden
2 = reserviert
3 = Fehler (Botschaftsüberwachung, Timeout, Akustik";
CM_ SG_ 779 KBI_ARA_in_Anzeige "Anzeige von ARA im Kombi aktiv";
CM_ SG_ 779 KBI_BKL_Lampe "Sicherheits-Lampe Bremskontrolle wurde eingeschaltet;
";
CM_ SG_ 779 KBI_Einheit_Tacho "Information, ob es sich um Meilen- oder Kmh-Kombi handelt, Einheit des Tachos entspricht dem Zifferblatt, Grösse ist nicht veränderlich";
CM_ SG_ 779 KBI_ESP_Lampe "ESP-Sicherheits-Lampe wurde eingeschaltet ";
CM_ SG_ 779 KBI_Fehler_Anzeige_ACC "Rückmeldung an ACC, dass mindestens eine der ACC-relevanten Anzeigen -rote Fahrerübernahme, Mitteldisplay, Gong - fehlerhaft sind.";
CM_ SG_ 779 KBI_Handbremse "Handbremsen-Information vom Kombi.
Das Signal bezieht sich ausschließlich auf den Zustand der konventionellen Handbremse.";
CM_ SG_ 779 KBI_im_Stellgliedtest "Kombi im Stellgliedtest, Signal muss eingelesen werden, um Fehlfunktion aufgrund der Bewegung der Stellglieder (Drehzahlmesser, Tacho) des Kombis zu verhindern";
CM_ SG_ 779 KBI_Konsistenz_ACC "Rückmeldung an ACC, dass die Botschaften zur Ansteuerung von Anzeigen nicht bzw. nicht konsistent empfangen wurden (Timeout-, BZ-, CHK- und DLC-Fehler)                                                                                                        ";
CM_ SG_ 779 KBI_Lenkung_Lampe "Sicherheits-Lampe der Lenkung (Lenkhilfe EPS, Audi-Dynamic-Steering ...) wurde eingeschaltet.

0x0 = Lenkungs-Lampe aus
0x1 = Lenkungs-Lampe ein";
CM_ SG_ 779 KBI_MFA_v_Einheit_01 "Einheit der Geschwindigkeit, die vom Fahrer im Car-Menü gewählt wurde. Veränderliche Grösse, im Gegensatz zur Einheit des Tachokranzes.";
CM_ SG_ 779 KBI_NV_in_Anzeige "Das Bit gibt dem NV die Information, ob NV-Bild im Kombi in der Anzeige ist. (Information ist notwendig um Kontrasverstellungen nur dann zuzulassen, wenn der Fahrer das Feedback über das  Kombidisplay bekommt.)";
CM_ SG_ 779 KBI_Oeldruck_Schalter "Das Signal bildet den Status des Öldrucks über den am Kombi angeschlossenen Öldruckschalter ab.";
CM_ SG_ 779 KBI_Oeldruckwarnung "Öldruckwarnung im Kombi aktiv";
CM_ SG_ 779 KBI_PLA_in_Anzeige "Das Signal wird als aktive Rückmeldung genutzt, ob die Info des PLA im Kombi angezeigt wird. Wenn nach Anforderung des Displays das Signal zweimal auf 0 ist, wird der Parkvorgang abgebrochen.
Ein Kombi, dass PLA Anzeige nicht unterstützt, schickt dauerha";
CM_ SG_ 779 KBI_SILA_gueltig "Rückmeldeinformation (Bit 1-6) ist gültig";
CM_ SG_ 779 KBI_Tankwarnung "Fahrer wird gewarnt, dass er den Reservebereich erreicht hat. Fzg.spezifische Warnschwelle";
CM_ SG_ 779 KBI_V_Digital "Ausgabe der im Kombi angezeigten digitalen Geschwindigkeit.

Einheit ist im KBI_MFA_v_Einheit_01 definiert";
CM_ SG_ 779 KBI_Vorglueh_System_Lampe "Rückmeldung der Vorglühlampe bzw. Motor Systemlampe (MO_Systemlampe) an den Motor (bei Diesel und Otto!). Hardwaremässig gleiche LED im Kombi (EPC- oder Glühwendel), Unterscheidung nur über Ziffernblatt.";

CM_ SG_ 1719 KBI_aktive_Laengsfunktion "Auswahl, der vom Fahrer gewünschten Laengsregelfunktion";
CM_ SG_ 1719 KBI_FStatus_Tank "Signal wird gesetzt:

a) Während der Fehlerentprellzeit (20 s Entprellung)

b) Bei erkanntem Fehler wird der Tankinhalt während der laufenden KL15-Phase über den 
    Verbrauch zurückgerechnet. In dieser Zeit ist das Bit ebenfalls gesetzt. Nach einem";
CM_ SG_ 1719 KBI_Inhalt_Tank "Restmenge 2 bzw. 2,5l nicht auflösbar

";
CM_ SG_ 1719 KBI_Kilometerstand "Fehler wird ausgegeben, falls Kilometerstand nicht restaurierbar
";
CM_ SG_ 1719 KBI_Oelwechsel_durchgefuehrt "Nach einen Ölwechsel (Service) ist die Ethanol Warmfahrwarnung zu unterdrücken.";
CM_ SG_ 1719 KBI_QBit_Aussen_Temp_gef "0x0 = gültiger Wert
0x1 = Ersatz-, Init- oder Fehlerwert";
CM_ SG_ 1719 KBI_RDK_Kalibrier_Anf "Bei gesetztem Bit soll die RDK die aktuellen Istdrücke zu Solldrücken übernehmen (nur bei Nichtverbau einer Headunit erforderlich).";
CM_ SG_ 1719 KBI_Reserve_Warnung_Sek "Signalisiert die Reservewarnung für die Energiespeicher CNG, LPG, HV-Batterie.
Fahrer wird gewarnt, dass er den Reservebereich erreicht hat. Fzg.spezifische Warnschwelle.";
CM_ SG_ 1719 KBI_Standzeit_02 "Zähler welcher die Standzeit des Motors wiedergibt.
Das Signal beschreibt den Anteil der Motor-Standzeit zwischen Zündung aus und nächstem Motorstart.";

CM_ SG_ 1720 KBI_BCmE_aktiv "Anzeige BCmE aktiv (BCmE-Screen oder Einsparhinweis in der Anzeige)";
CM_ SG_ 1720 KBI_Max_Tankinhalt "Mitteilung des maximalen Tankinhalts an das Reichweitenmodul";
CM_ SG_ 1720 KBI_Nachtanken_erkannt "Statusinformation Nachtankmodus";
CM_ SG_ 1720 KBI_Reifenumfang "Mittlerer Radumfang aus der K-Zahl gerechnet in Millimeter.  Byte 2 Bit 5,4 reserviert, Byte 2 Bit 3..0 und Byte 1 Bit 7..0; Wertebereich 0..4096 mm
";
CM_ SG_ 1720 KBI_Reifenumfang_Sekundaer "Fahrzeuge mit unterschiedlichen Reifenumfängen Vorderachse / Hinterachse:

Primärachse: KBI_Reifenumfang
Sekundärachse: KBI_Reifenumfang_Sekundaer
";
CM_ SG_ 1720 KBI_Sparhinweis_quittiert "angezeigter Sparhinweis ist quittiert. Signal wird nach zwei Sendebotschaften wieder auf '0' gesetzt.";
CM_ SG_ 1720 KBI_Tankfuellstand_Prozent "Tankfüllstand in %";
CM_ SG_ 1720 KBI_Tankinhalt_hochaufl "angezeigter Tankinhalt hochauflösend zur Restreichweitenberechnung";
CM_ SG_ 1720 KBI_Variante "Zeigt an ob es sich um ein konventionelles Zeiger-Kombiinstrument handelt oder um eine Volldisplay-Kombiinstrument";
CM_ SG_ 1720 KBI_Variante_USA "In diesem Signal wird die HW-Variante des Kombis ausgegeben, ACC plausibilisiert auf dieses Signal hin seine US-Codierung";

CM_ SG_ 810 EPS_01_CRC "Für MLB:
'Berechnung siehe Lastenheft 'Kommunikationsabsicherung für FlexRay und CAN''

Ab MQB und MLBevo:
'Berechnung siehe Lastenheft 'End-to-End Kommunikationsabsicherung''

Endwerte siehe Begleitdokument 'S-PDU Kennungsfolgen'
";
CM_ SG_ 810 EPS_Akustiksignal "Ansteuerung eines Akustiksignals im Kombi";
CM_ SG_ 810 EPS_Anf_KL "Nach Überschreiten einer oberen Grenztemperatur innerhalb des Steuergerätes der Lenkhilfe fordert die EPS die Zuschaltung einer externen Kühlung durch den Kühlerlüfter an.
Es besteht kein technischer Zusammenhang mit einer Batterie_ab - Erkennung in der ";
CM_ SG_ 810 EPS_ARA_Status "Anforderung vom Anhängerrangierassistent. 
16 Statuswerte";
CM_ SG_ 810 EPS_Charisma_FahrPr "MLBevo: Aktuelles Fahrprogramm des Charisma-Teilnehmers (siehe Systemlastenheft Drive Select)
MQB: Istwert der Kennlinie (siehe Systemlastenheft MQB FPA)";
CM_ SG_ 810 EPS_Charisma_Status "Rückmeldung an den Charisma-Master

Wert 0x3 ist nur für Fahrzeuge ab MQB relevant";
CM_ SG_ 810 EPS_Fehlerlampe "Steuert direkt die Fehlerlampe Lenkhilfe (gelb); kein Aufprüfen bei Neustart, keine Rückleseinformation in Kombi-Botschaft (nur für VW526 Hybrid)";
CM_ SG_ 810 EPS_Lenkerposition "Position des Lenkers im Fahrzeug";
CM_ SG_ 810 EPS_PLA_Abbruch "Art des Fehlers ohne Eintrag, 16 Werte möglich (siehe LH EPS/PLA)";
CM_ SG_ 810 EPS_PLA_Fehler "Art des Fehlers ohne Eintrag, 16 Werte möglich (siehe LH EPS/PLA)";
CM_ SG_ 810 EPS_PLA_Status "Zustand der Statusmaschine der EPS für die korrespondierenden Statusmaschine im PLA.";
CM_ SG_ 810 EPS_SpannungsAnf "Forderung des EPS-SG's zur Spannungsanhebung.";
CM_ SG_ 810 EPS_Warnungen "Diese Bits werden verwendet, um im Kombi Texte, Lampen oder Bilder für die Lenkhilfe darzustellen
Audi MLB/RSe:
Text_1: Lenkung defekt (Prio 1)
Text_2: Lenkung Systemstörung (Prio 2)
VW526:
Text_1 (ID_TXT_1026.1): Ausfall Lenkunterstützung
Text_2 (I";

CM_ SG_ 285 EPS_02_CRC "Für MLB:
'Berechnung siehe Lastenheft 'Kommunikationsabsicherung für FlexRay und CAN''

Ab MQB und MLBevo:
'Berechnung siehe Lastenheft 'End-to-End Kommunikationsabsicherung''

Endwerte siehe Begleitdokument 'S-PDU Kennungsfolgen'
";
CM_ SG_ 285 EPS_Drehzahlreserve "Signal beschreibt wieviel Drehzahlreserve in EPS besteht (abhängig von Bordnetzspannung)";
CM_ SG_ 285 EPS_Lastinfo "entspricht Stromaufnahme des Lenkhilfe-SG, Auflösung = 1A";
CM_ SG_ 285 EPS_Leistungsanforderung "Signal informiert BEM, daß EPS einen erhöhten Leistungs-/Spannungsbedarf hat";
CM_ SG_ 285 EPS_Motorstartverzoegerung "Das Signal gibt eine Empfehlung, ob der Motorstart verzögert werden sollte. Es beschreibt aber kein Motorstartverbot. Der Motor darf trotz gesetztem Bit einen Motorstart vollziehen.";
CM_ SG_ 285 EPS_Notlauf "Bit-Feld zeigt an, dass sich die Lenkhilfe in einem Notlaufprogramm 
befindet und durch welche Ursache dieses aktiviert wurde; 
das Betriebsverhalten der Lenkhilfe wird an das bestehende Defizit angepasst.

Erläuterung Notlauf-Ursachen:

- Unterspan";
CM_ SG_ 285 EPS_StartStopp_Info "Das Signal gibt eine Motorstoppempfehlung für StartStop. 
Bei einem zu großem Handlenkmoment von X Nm wird eine Empfehlung ausgesprochen keinen Motorstopp durchzuführen.";
CM_ SG_ 285 EPS_Unterstuetzungsleistung "Die Unterstützungsleistung gibt prozentual an, in welchem Verhältnis die tatsächlich abgegebene Leistung zur Nominalleistung steht, d.h.:

0% = keine Servounterstützung

100% = maximale Servounterstützung (Nominalleistung);

0% < Unterstützungsleist";
CM_ SG_ 285 EPS_VZ_Drehzahlreserve "Vorzeichen zur Drehzahlsreserve";

CM_ SG_ 159 EPS_03_CRC "Für MLB:
'Berechnung siehe Lastenheft 'Kommunikationsabsicherung für FlexRay und CAN''

Ab MQB und MLBevo:
'Berechnung siehe Lastenheft 'End-to-End Kommunikationsabsicherung''

Endwerte siehe Begleitdokument 'S-PDU Kennungsfolgen'";
CM_ SG_ 159 EPS_Berechneter_LW "Berechneter Lenkradwinkel (BLW)
MLB: Ausgabe des berechneten Lenkwinkels mit Geradeauslaufkorrektur aus der Position des Lenkmotors (Absolutwert)
MQB: Ausgabe des berechneten Lenkwinkels aus der Position des Lenkmotors (Absolutwert) und ggf. unter Berüc";
CM_ SG_ 159 EPS_BLW_QBit "beschreibt die Qualität/Vertrauenswürdigkeit des berechneten LW";
CM_ SG_ 159 EPS_DSR_Status "Interner DSR-Status des EPS-Steuergerätes";
CM_ SG_ 159 EPS_HCA_Status "Beschreibt den Status der HCA-Funktion im EPS-Steuergerät.";
CM_ SG_ 159 EPS_Lenkmoment "Gibt das durch den Momentensensor detektiertes Lenkhandmoment (Absolutmoment) aus

Wertebereich von 0x321 - 0x3FD reserviert (z.Zt. nicht bedient)";
CM_ SG_ 159 EPS_Lenkungstyp "Signal beschreibt den eingebauten Lenkungstyp. Enthält z. B. implizit auch die Information, welche Ritzelübersetzung verbaut ist. Wichtig für die Regelsysteme HCA und DSR.
Im MQB gilt das 'EPS LH CAN-Schnittstelle'.";
CM_ SG_ 159 EPS_VZ_BLW "Vorzeichen Berechneter Lenkwinkel

(für EPS_Berechneter_LW)";
CM_ SG_ 159 EPS_VZ_Lenkmoment "Vorzeichen Lenkhandmoment";

CM_ SG_ 134 LWI_01_CRC "Für MLB:
'Berechnung siehe Lastenheft 'Kommunikationsabsicherung für FlexRay und CAN''

Ab MQB und MLBevo:
'Berechnung siehe Lastenheft 'End-to-End Kommunikationsabsicherung'

Endwerte siehe Begleitdokument 'S-PDU Kennungsfolgen'";
CM_ SG_ 134 LWI_Lenkradw_Geschw "Wertebereich = +/- 2500 Grad/s
Auflösung = 5 Grad/s

Hinweis: Zusätzlich gestellte Winkel bei Dynamiklenkung beachten !";
CM_ SG_ 134 LWI_Lenkradwinkel "Wertebereich = +/- 800 Grad
Auflösung = 0,1 Grad
ACHTUNG: spezifizierte Interne Auflösung des Sensors beträgt aber nur Schrittweite 0,5 Grad!

Hinweis:
MLB: Zusätzlich gestellte Winkel bei Dynamiklenkung beachten !
MQB: Nicht konstante Lenkübersetzu";
CM_ SG_ 134 LWI_MFL_Abschaltung "Signal zur Anforderung der MFL Abschaltung bei Erkennung einer dynamischen Lenkbewegung.";
CM_ SG_ 134 LWI_QBit_Lenkradwinkel "Das QBit wird auch bei nicht abgeglichenem Lenkradwinkelsensor gesetzt";
CM_ SG_ 134 LWI_QBit_Sub_Daten "Es gilt die Signalspezifikation laut LAH";
CM_ SG_ 134 LWI_Sub_Daten "Verschlüsseltes Datenpaket vom Sub-Rechner des LWS, Verwendung nur durch SCU und ESP_ADS
Verwendung gemäß 'Sicherheitsanforderungen an Empfängersteuergeräte'

Im MLB gilt die Signalspezifikation: LAH 8K0953B
Im MLBevo gilt die Signalspezifikation LAH.";
CM_ SG_ 134 LWI_VZ_Lenkradw_Geschw "Vorzeichen Lenkradwinkelgeschwindigkeit gemäss DIN70000; 
Nullstellung = +0";
CM_ SG_ 134 LWI_VZ_Lenkradwinkel "Vorzeichen Lenkradwinkel gemäss DIN70000; 
Nullstellung = +0";

CM_ SG_ 917 AFS_Abbiegelicht_Dimm_Anf "Beschreibt ob das Abbiegelicht gedimmt oder hart einschalten werden soll. Dimmkurve ist Empfänger hinterlegt.";
CM_ SG_ 917 AFS_Abbiegelicht_li_Anf "Anforderung das Abbiegelicht links einzuschalten";
CM_ SG_ 917 AFS_Abbiegelicht_re_Anf "Anforderung das Abbiegelicht rechts einzuschalten";
CM_ SG_ 917 AFS_adaptive_LV_verbaut "Verfügbarkeit der adaptiven Lichtverteilung im AFS-SG.
(Das BCM steuert mit diesem Signal die Einblendung des entsprechenden Menüs)";
CM_ SG_ 917 AFS_Allwetterlicht "Status ¿Allwetterlicht¿ - Licht für schlechte Sichtverhältnisse
(bei Defekt -> nicht aktiv)";
CM_ SG_ 917 AFS_Charisma_FahrPr "MLBevo: Aktuelles Fahrprogramm des Charisma-Teilnehmers (siehe Systemlastenheft Drive Select)
MQB: Istwert der Kennlinie (siehe Systemlastenheft MQB FPA)";
CM_ SG_ 917 AFS_Charisma_Status "Charisma Systemstatus des Charisma-Teilnehmers

Wert 0x3 ist nur für Fahrzeuge ab MQB relevant";
CM_ SG_ 917 AFS_Ersatzlicht_Links "Bei aktivierter Ersatzlichtfunktion wird das Abblendlicht ausgeschaltet und eine Ersatzlichtquelle eingeschaltet (z.Zt. B7)";
CM_ SG_ 917 AFS_Ersatzlicht_Rechts "Bei aktivierter Ersatzlichtfunktion wird das Abblendlicht ausgeschaltet und eine Ersatzlichtquelle eingeschaltet (z.Zt. B7)";
CM_ SG_ 917 AFS_Fehlertext "Fehlertext wird im Kombi angezeigt (z.Zt nur bei VW)";
CM_ SG_ 917 AFS_Fernlicht_li_defekt "Beschreibt ob das Fernlicht des linken Scheinwerfers defekt ist";
CM_ SG_ 917 AFS_Fernlicht_re_defekt "Beschreibt ob das Fernlicht des rechten Scheinwerfers defekt ist";
CM_ SG_ 917 AFS_Fernlicht_Status "Beschreibt ob das Fernlicht aktiv oder inaktiv ist";
CM_ SG_ 917 AFS_Lampe "Status der Fehlerlampe: aktuell anliegender Fehlerzustand des dynamischen oder statischen Kurvenlichtes";
CM_ SG_ 917 AFS_LED_Blinkmode "Lampe soll im Warnfall mit 1Hz blinken, wenn das Bit gesetzt ist (z.Zt nur bei VW)";
CM_ SG_ 917 AFS_Status_adaptive_LV "Gibt den Status der adaptiven Lichtverteilung an";
CM_ SG_ 917 AFS_Verfuegbarkeit_GLW "Beschreibt die Verfügbarkeit der Gleitenden Leuchtweite / Fernlichtassistenz - Verfügbarkeit bedeutet, dass die Funktion Gleitende Leuchtweite möglich ist";
CM_ SG_ 917 GLW_Sensor_blockiert "Das Signal zeigt an, dass die Kamera zur Zeit keine Sicht hat. 
Verhalten wie Fernlichassisten. 
Weiterleitung des Signals vom BCM an das KOMBI";
CM_ SG_ 917 LWR_AFS_Grundeinstellung "Grundeinstellung des Abblendlichtes am Lichteinstellkasten im Service oder Bandende mit Tester erfolgt! (auch für das dynamische Kurvernlicht)";
CM_ SG_ 917 LWR_AFS_Parametrisierung "Parametrisierung wählt die Fahrzeugvariante und die AFS-Variante aus";
CM_ SG_ 917 LWR_Hoehenwert_HL "Aktueller Höhensensorwert Hinten Links
MSS LB überträgt den Aktueller Höhensensorwert Vorne Rechts.

0x7F = 0 mm";
CM_ SG_ 917 LWR_Hoehenwert_VL "Aktueller Höhensensorwert Vorne Links

0x7F = 0 mm";
CM_ SG_ 917 LWR_Initialisierungslauf "Initialisierungslauf der Schrittmotoren, erfolgt defaultmäßig beim Motorstart";
CM_ SG_ 917 LWR_Lampe "Status der Fehlerlampe: aktuell anliegender Fehlerzustand";
CM_ SG_ 917 LWR_Modus "Schnelle oder langsame Regelart der LWR";
CM_ SG_ 917 LWR_Pos_Schrittmotor "Position des Aktuators in Prozent des maximalen Stellweges; vor dem Initialisierungslauf (Motorstart) wird der Initwert ausgegeben: 
0% : tiefste Stellung (auf Block) des Schrittmotors;
100% : maximaler Verstellweg des Schrittmotors (nicht die Grenze de";
CM_ SG_ 917 LWR_Reisemodus_Texte "Anzeige der eingestellten Verkehrsart bei aktivem Touristenlicht";
CM_ SG_ 917 LWR_Sicherheitsposition "LWR Sicherheitsposition beider Scheinwerfers";
CM_ SG_ 917 LWR_Touristenmodus_aktiv "Über MMI sendet BCM1 eine Anforderung Touristenmodus an die LWR. Diese sendet als Rückmeldung an BCM1, dass der Touristenmodus aktiv geschaltet wurde";
CM_ SG_ 917 LWR_Touristenmodus_verbaut "Verfügbarkeit der Touristenfunktion im AFS/LWR-SG.
(Das BCM steuert mit diesem Signal die Einblendung des entsprechenden Menüs)";

CM_ SG_ 1600 MO_Absperrventil_oeffnen "Signal an Klima-SG das Absperrrventil anzusteuern. Ab D4 auch 0x3 Ventil_schließen.

Im MQB wird hier der Soll-Status des Absperrventils ausgegeben.
Achtung: bei z. B. klemmendem Ventil entspricht das Signal nicht dem tatsächlichen Status!";
CM_ SG_ 1600 MO_aktives_Getriebeheizen "Information für Getriebe, ob ein Ventil für Getriebheizen angesteuert werden muss";
CM_ SG_ 1600 MO_Ansaugluft_Temp "In Fahrzeugen ohne Außentemperatur vom Kombi kann aus der Ansauglufttemperatur auf die Außentemperatur geschlossen werden. Beim SDI ist das mit einer gewissen Genauigkeit gegeben. Genutzt wird es vom ASG.";
CM_ SG_ 1600 MO_Getriebe_kuehlen "Anforderung Getriebekühlventilansteuerung";
CM_ SG_ 1600 MO_Heizungspumpenansteuerung "Anforderung Heizungspumpenansteuerung
MQB und Hybrid: Status der Heizungsunterstützungspumpe am MSG
";
CM_ SG_ 1600 MO_Hoeheninfo "Korrekturfaktor Höhe (1 entspricht 1013 mbar)";
CM_ SG_ 1600 MO_HYB_Fehler_HV_Netz "Im HV-Bordnetz ist fehlerbedingt kein generatorischer Betrieb möglich. Das 12V-Bordnetz wird über den DC/DC-Wandler allein aus der Traktionsbatterie gespeist. Um diesen Zustand möglichst lange aufrechterhalten zu können, sollten Komfort-Verbraucher abgesc";
CM_ SG_ 1600 MO_Kennfeldk "Die Kennfeldkühlung ist in diesem Fahrzeug verbaut und hat keinen Systemfehler";
CM_ SG_ 1600 MO_KL15_Abschaltempfehlung "Kessy Abschaltempfehlung nach Verlassen des Fahrzeugs";
CM_ SG_ 1600 MO_Kuehlmittel_Temp "Kuehlmitteltemperatur";
CM_ SG_ 1600 MO_Mom_Traegheit_02 "Massenträgheit (J) der Motors bzw. der Antriebsmaschinen in kgm².

Zur Berücksichtigung des E-Motor in Hybrid-Projekten:
in MLB-Projekten wird nur der J-Wert des Verbrennungsmotors und nicht der J-Wert des E-Motors berücksichtigt.
In MQB/MLBevo-Projek";
CM_ SG_ 1600 MO_Nachlaufzeit_Heizungspumpe "Nachlaufzeit für Heizungspumpe für Turboladerschutz";
CM_ SG_ 1600 MO_Oel_Temp "Realer Meßbereich ca. -40..150 Grad";
CM_ SG_ 1600 MO_QBit_Ansaugluft_Temp "
";
CM_ SG_ 1600 MO_QBit_Hoeheninfo "Qualifizierungsbit der Höheninfo. Gesetzt bei Ersatzwert, Init oder Fehler.";
CM_ SG_ 1600 MO_QBit_Kuehlmittel_Temp "
";
CM_ SG_ 1600 MO_SpannungsAnf "Forderung des Motor-SGs zur Spannungsanhebung";
CM_ SG_ 1600 MO_Versionsinfo_02 "Versioninformation vom Motor zur Steuerung bei inkompatiblen KMatrix-Änderung bzw. Einführung von neuen Funktionen, die in den Empfängern verriegelt werden müssen. Zu jedem Ereignis wird ein fixer Zählerstand zugeordnet, um dem Empfänger die funktionale Ä";

CM_ SG_ 167 MO_erste_Ungenauschwelle "Zusätzliche Ungenauigkeit (zur Grundungenauigkeit). Motormomente ungenau >8% (kleinste Ungenauschwelle)
";
CM_ SG_ 167 MO_Mom_Ist_Summe "Einheitenloser Wert! Faktor in MO_Faktor_Momente_02 in Motor_Code_01 beachten!

Ist-Moment als Summe aus Verbrennungsmotor und E-Motor (bei Hybrid-Konzepten) incl. allen Eingriffen und Korrekturen; definiert als Kupplungsmoment an Kurbelwelle nach Abgri";
CM_ SG_ 167 MO_Mom_Schub "Einheitenloser Wert! Faktor in MO_Faktor_Momente_02 in Motor_Code_01 beachten!

Moment das sich einstellt, wenn der Fahrer 0% Fahrpedal gibt; bei konventionellen Projekten = alle Verluste (mechanische Reibung und sonstige Verluste) des Verbrennungsmotor";
CM_ SG_ 167 MO_Mom_Soll_gefiltert "Einheitenloser Wert! Faktor in MO_Faktor_Momente_02 in Motor_Code_01 beachten!

MO_Mom_Soll_Roh nach Fahrverhaltensfilter, begrenzt nach oben mit MO_Mom_Begr_dyn, Einrechnung der plausibilisierten Bremsen-Eingriffe; ohne Getriebe-Schalt-Eingriffe, ohne ";
CM_ SG_ 167 MO_Mom_Soll_Roh "Einheitenloser Wert! Faktor in MO_Faktor_Momente_02 in Motor_Code_01 beachten!

Momentenanforderung aus Fahrpedal bzw. von ACC/GRA bzw. aus dem Leerlaufregler (quasistatischer Anteil) bzw. aus Rekuperationsanforderung; keine Begrenzungen, keine Filterun";
CM_ SG_ 167 MO_Mom_Traegheit_Summe "Einheitenloser Wert! Faktor in MO_Faktor_Momente (CAN V6.x) bzw. MO_Faktor_Momente_02 (CAN V7.x) in Motor_Code_01 beachten!

Moment, das zur Beschleunigung der trägen Massen aufgewendet wird bzw. frei wird; Summen aus Anteilen für Verbrennungsmotor und ";
CM_ SG_ 167 MO_QBit_Motormomente "AUDI D4: Zykluszeit: 10ms (siehe Zykluszeit schnell/Cycletime Fast)

Ungenaue Momentenangaben, weil die Momente aus Ersatzwerten berechnet wurden (z.B. HFM ausgefallen). Qualifizierungsbit für die Motormomente.

Achtung:
Reduktion der Zykluszeit Moto";
CM_ SG_ 167 MO_Status_Normalbetrieb_01 "Das Motorsteuergerät sendet das Informationsbit, wenn die Initialisierungsphase des Steuergerätes abgeschlossen ist. Zusätzlich muss die Klemme 15 eingeschalten sein und eine applizierbare Mindestdrehzahlschwelle (Kennlinie in Abh. von der Kühlwassertempe";
CM_ SG_ 167 Motor_11_CRC "Für MLB:
'Berechnung siehe Lastenheft 'Kommunikationsabsicherung für FlexRay und CAN''

Ab MQB und MLBevo:
'Berechnung siehe Lastenheft 'End-to-End Kommunikationsabsicherung''

Endwerte siehe Begleitdokument 'S-PDU Kennungsfolgen'";

CM_ SG_ 168 MO_Drehzahl_01 "Im Fehlerfall wird die Motordrehzahl über die Nockenwellendrehzahl als Ersatzgrösse ausgegeben

Bei Parallelhybrid: Getriebeeingangsdrehzahl (=E-Maschinen Drehzahl)

Hinweis: 
Ehemaliger Fehlerwert 0xFFFF wird senderseitig nicht unterstützt. 
Diesen";
CM_ SG_ 168 MO_Mom_Begr_Fahr "Einheitenloser Wert! Faktor in MO_Faktor_Momente (CAN V6.x) bzw. MO_Faktor_Momente_02 (CAN V7.x) in Motor_Code_01 beachten!

Bei aktueller Drehzahl quasistationär (nach ca. 3¿5 s) max. mögliches Getriebeeingangsmoment (Summe aus Verbrennungsmotor und E-";
CM_ SG_ 168 MO_Mom_Begr_Schalt "Einheitenloser Wert! Faktor in MO_Faktor_Momente (CAN V6.x) bzw. MO_Faktor_Momente_02 (CAN V7.x/8.x) in Motor_Code_01 beachten!

Bei aktueller Drehzahl kurzfristig (ca. 100..200 ms) für momentenerhöhende Getriebeeingriffe max. zur Verfügung stehendes Ge";
CM_ SG_ 168 MO_Mom_neg_verfuegbar "Einheitenloser Wert! Faktor in MO_Faktor_Momente (CAN V6.x) bzw. MO_Faktor_Momente_02 (CAN V7.x) in Motor_Code_01 beachten!

Bei aktueller Drehzahl im nächsten Task (bei CAN-Übertragung z.B. 10ms) tatsächlich verfügbares negatives Moment (Summe aus Verl";
CM_ SG_ 168 MO_Momentenintegral_02 "100  %  entspricht volle Verfügbarkeit aktuell vorhanden. 0 % entspricht Integral bis Limit gefüllt, erhöhender Eingriff kann aktuell nicht berücksichtigt werden oder aufgrund eines Fehlers nicht verfügbar
";
CM_ SG_ 168 MO_QBit_Drehzahl_01 "AUDI D4: Zykluszeit: 10ms (siehe Zykluszeit schnell/Cycletime Fast)

Achtung:
Reduktion der Zykluszeit Motor_03 auf 10ms geplant.
Projektabhängig soll künftig mit 10ms gesendet werden.
Empfänger die in weiteren Konzern-Projekten eingesetzt werden müs";
CM_ SG_ 168 Motor_12_CRC "Für MLB:
'Berechnung siehe Lastenheft 'Kommunikationsabsicherung für FlexRay und CAN''

Ab MQB und MLBevo:
'Berechnung siehe Lastenheft 'End-to-End Kommunikationsabsicherung'

Endwerte siehe Begleitdokument 'S-PDU Kennungsfolgen'";

CM_ SG_ 958 MO_Aussp_Anlass "Das Signal zeigt an, ob die Wiederholstartsperre aktiv ist. D. h. eine Ansteuerung des Anlassers wird auch bei erfüllten Startvoraussetzungen (HS: Interlock betätigt bzw. AT: P/N eingelegt und Bremse betätigt) nicht erfolgen.";
CM_ SG_ 958 MO_BKV_Unterdruckwarnung "Über die Unterdruckwarnung signalisiert das MSG dem ESP, dass kein ausreichender Unterdruck für den BKV zur Verfügung gestellt werden kann.";
CM_ SG_ 958 MO_BLS "Ungefiltertes Rohsignal des Bremslichtschalters, nur wenn HW-Eingang bestückt und ausgewertet wird. Bei Motoren ohne genutzten HW-Eingang wird kein Ersatzwert (bspw. SW-Signal über CAN) ausgegeben!
Bei AUDI muss das Signal wg. Bremslichtfunktion immer be";
CM_ SG_ 958 MO_BMS_NV_Anf_stuetzen "Garantierte Unterstützung des Zusatzspeichers ist erforderlich. Zusatzspeicher muss an das Versorgungsnezt angebunden werden. ";
CM_ SG_ 958 MO_EKlKomLeiRed "Anforderung an die Klimasteuerung, die Leistungsaufnahme des E-Kompressors bei schlechtem SOC und in bestimmten Fahrsituationen zu begrenzen. (Das bereits bestehende Signal 'Klimakompressor aus' als stets umzusetzende Anforderung bleibt unverändert besteh";
CM_ SG_ 958 MO_Ext_E_Fahrt_aktiv "Funktionsrückmeldung zum erw. E-Fahr-Betrieb über Lampe/LED im E-Mode-Taster";
CM_ SG_ 958 MO_Fahrer_bremst "Redundante Bremsinformation vom Motor.

MLB:
AUDI D4: Zykluszeit: 10ms (siehe Zykluszeit schnell/Cycletime Fast)
Im AUDI B8 wird in diesem Bit der Wert der ESP-CAN-Information 'ESP_Fahrer_bremst' ausgegeben.

Achtung:
Reduktion der Zykluszeit Motor";
CM_ SG_ 958 MO_FMAus_aktiv "Das Signal gibt Rückmeldung ob Freilauf Motor aus aktiv ist. Beleibt auch 0km/h (unterhalb der StartStopp Schwelle) weiterhin aktiv.";
CM_ SG_ 958 MO_FMAus_Startvariante "Startvariante beim Motorstart aus der Freilauf-Motor-AUS Phase";
CM_ SG_ 958 MO_Freig_Anlass "Bit wird gesetzt, wenn der Motor beim Automatikstart gestartet werden darf (Motorstillstand, Emissionsmaßnahmen sind erfüllt).";
CM_ SG_ 958 MO_Freig_Reku "Empfehlung des Motor-SG's zur Spannungsabsenkung/-anhebung für den Rekuperationsbetrieb";
CM_ SG_ 958 MO_Freigabe_Segeln "Freigabebit des Segelbetriebs im Getriebe. Bedingt durch bestimmte Diagnosen und Adaptionen des MSGs, die nur im Schub möglich sind, darf nicht jede Schubphase für einen Segelbetrieb genutzt werden. Eine Freigabe bleibt auch außerhalb einer Schubphase bes";
CM_ SG_ 958 MO_Gangposition "MLB:
Stellung des Wählhebels in der Schaltgasse des Handschaltgetriebes.
MLBevo: 
Ausweitung der Bedienung auch auf Automatikgetriebe;
Routing des Signals GE_Fahrstufe: 
1. Position_R (dez. 6) auf MO_Gangposition: Gang_R (dez. 13) wegen Entfall Signa";
CM_ SG_ 958 MO_Handshake_STH "Es gilt: Signalspec MO_Handshake v1.0

Handshake zwischen MSG und STH. Wenn das MSG die EKP aufgrund einer STH-Anforderung ansteuert und kein Fehlereintrag bzgl. EKP/KPE/NDR vorliegt, wird das Bit gesetzt.";
CM_ SG_ 958 MO_HYB_Fahrbereitschaft "Signal steuert u.a. in der Lenkhilfe zusammen mit weiteren Informationen den Modewechsel in den 'Drivemode'
Grüne Anzeige im Kombiinstrument zur Signalisierung der Bereitschaft des Hybridsystems.";
CM_ SG_ 958 MO_HYB_VM_aktiv "0 = VMotor wird nicht aktiv gehalten (nVM < n_min und keine LL-Regelung aktiv)
1 = VMotor aktiv (ab der ersten Einspritzung; gilt auch für Schubbetrieb, wenn VMotor spätestens durch LLRegelung befeuert würde)
Verwendet zur Bestimmung des Ist-Zustandes";
CM_ SG_ 958 MO_Interlock "Das Motorsteuergerät gibt die Information aus, ab wann der Kupplungsschalter durch das Motorsteuergerät als getreten gesehen wird.
Bei Systemen für Start Stopp muss das Interlocksignal für einen Start durch das MSG generiert werden, sobald der Schalthebe";
CM_ SG_ 958 MO_Kickdown "Es gilt: Signalspec MO_Kickdown v1.0";
CM_ SG_ 958 MO_Kl_50 "Klemme 50: Startausführung

MLB: nicht von allen Motoren gesendet
MQB/MLBevo: gesendet von allen Motoren ";
CM_ SG_ 958 MO_Kl_75 "Klemme X
";
CM_ SG_ 958 MO_Klima_Eingr "Eingriffe des Motor bei der Klima";
CM_ SG_ 958 MO_Konsistenz_Bremsped "MLB:

AUDI D4: Zykluszeit: 10ms (siehe Zykluszeit schnell/Cycletime Fast)
Siehe 'Funktionsspezifikation Bremslichtinfo B8'

Achtung:
Reduktion der Zykluszeit Motor_03 auf 10ms geplant.
Projektabhängig soll künftig mit 10ms gesendet werden.
Empfäng";
CM_ SG_ 958 MO_Kuppl_schalter "MLB:
Das Motorsteuergerät gibt die Information aus, ab wann der Kupplungsschalter durch das Motorsteuergerät als getreten gesehen wird
0x0: Schalter sagt betätigt (Ausgekuppelt)
0x1: Schalter sagt nicht betätigt (Eingekuppelt)

MQB:
Nur Handschalter";
CM_ SG_ 958 MO_Motor_laeuft "Das Motorsteuergerät gibt die Information aus, ab wann der Motor verbrennungsbedingt autark läuft und durch zuschaltbare Nebenaggregate mechanisch belastbar ist (z.B. durch Generator, Klimakompressor, etc.).

Die 'Motor läuft' Information wird ausgegebe";
CM_ SG_ 958 MO_PTC_Status "Status-Rückmeldung vom MSG zum aktuellen PTC-Status (stufiges PTC, Relais am MSG). Bei Ansteuerung eines stufigen PTC durch ein anderes SG beschreibt das Signal die vom MSG freigegebene PTC-Stufe.";
CM_ SG_ 958 MO_QBit_Fahrer_bremst "MLB:
AUDI D4: Zykluszeit: 10ms (siehe Zykluszeit schnell/Cycletime Fast)

Achtung:
Reduktion der Zykluszeit Motor_03 auf 10ms geplant.
Projektabhängig soll künftig mit 10ms gesendet werden.
Empfänger die in weiteren Konzern-Projekten eingesetzt werd";
CM_ SG_ 958 MO_QBit_Gangposition "Qualitätsbit zum Signal MO_Gangposition";
CM_ SG_ 958 MO_QBit_KL_75 "Q - Bit für das KL 75 Signal zur Vermeidung der fehlerhaften Erkennung von Motorstarts. 
Wird auf 1 gesetzt, solange das Motorsteuergerät KL15 = AUS erkannt hat.";
CM_ SG_ 958 MO_Remotestart_Betrieb "Das MSG ist für den Remotestart-Betrieb bereit. Nach Empfang der Motorstartanforderung für RSt-Betrieb durch BCM wird der Fahrzeugmotor gestartet und solange der Motor läuft, bleibt dieses Bit aktiv. Dieses Signal ist nur zur Verwendung durch das BCM zur ";
CM_ SG_ 958 MO_Remotestart_moeglich "Wenn Bit gesetzt, würde das MSG bei entsprechender Anforderung durch das BCM den Remotestartbetrieb einleiten, d.h. das MSG ist remotestartfähig und es liegen aktuell keine relevanten Fehler oder andere Abbruchgründe vor.";
CM_ SG_ 958 MO_Signalquelle_Gangposition "Signalquelle des Signals MO_Gangposition
0: Signalquelle Gangpositionssensor
1: Signalquelle Modellwert (v/n)";
CM_ SG_ 958 MO_StartStopp_Fahrerwunsch "Fahreraktivität Start/Stop";
CM_ SG_ 958 MO_StartStopp_Motorstopp "Motor-Stopp durch Start/Stopp-Koordinator
HYBRID:
Wenn MO_Hybridfahrzeug = 1 gilt:
Verbrennungsmotor durch Hybrid-Koordinator im MSG ausgeschaltet. 
Die definierten Start/Stopp-Signale beziehen sich nur auf den Verbrennungsmotor!";
CM_ SG_ 958 MO_StartStopp_Status "Aktivitätsstatus Start/Stopp-Koordinator
HYBRID:
Wenn MO_Hybridfahrzeug = 1 gilt:
Signal bezieht sich nur auf den Verbrennungsmotor, nicht auf den Hybridantrieb
";
CM_ SG_ 958 MO_StartStopp_Wiederstart "Motorwiederstart durch Start/Stopp-Koordinator
HYBRID:
Wenn MO_Hybridfahrzeug =1 gilt:
Warnung vor Spannungseinbruch beim Zustart des Verbrennungsmotors. 
-nicht relevant, da derzeit kein Start über 12V-Starter geplant-
Dieses Signal wird nur vom Hyb";
CM_ SG_ 958 MO_StartVorauss_erfuellt "Dient der Fallunterscheidung bei ZAT-Betätigung im Zustand 'KL15 ein' (bei nicht gesetztem Signal folgt KL15 aus, bei gesetztem Signal folgt setzen KL50-Anf.)

0: Signal nicht bedient 
1: Voraussetzungen zur Antriebsstrangaktivierung / Startvoraussetzu";
CM_ SG_ 958 MO_Timeout_ESP "500 ms Timeout auf Bremsen-Botschaft ist >= 1 mal aufgelaufen, Löschen des Bits nach Neustart (KL15).

MLB:
AUDI D4: Zykluszeit: 10ms (siehe Zykluszeit schnell/Cycletime Fast)

Achtung:
Reduktion der Zykluszeit Motor_03 auf 10ms geplant.
Projektabh";
CM_ SG_ 958 MO_Zylinderabschaltung "Status Zylinderabschaltung Motor";
CM_ SG_ 958 Motor_14_CRC "Ab MQB und MLBevo:
'Berechnung siehe Lastenheft 'End-to-End Kommunikationsabsicherung'

Endwerte siehe Begleitdokument 'S-PDU Kennungsfolgen'";

CM_ SG_ 1631 MO_DPF_reg "Regeneration Diesel-Partikel-Filter";
CM_ SG_ 1631 MO_Energieinhalt_BMS "Restenergieinhalt der Traktionsbatterie, beeinflusst durch Fahrstrategie und weiteren Faktoren der Antriebssteuerung.";
CM_ SG_ 1631 MO_Heizstrom_EKAT "Aktuelle Gesamtstromaufnahme des E-Katalysators";
CM_ SG_ 1631 MO_Heizstrom_SCR "Aktuelle Gesamtstromaufnahme der Tank-, Fördermodul- und Leitungsheizung des SCR-Systems";
CM_ SG_ 1631 MO_SpannungsAnf_02 "Forderung des Motor-SG's zur Spannungsanhebung";
CM_ SG_ 1631 MO_Testmode_AG "Status Prüfstandbetrieb des MSGs";
CM_ SG_ 1631 TSK_Fahrzeugmasse_02 "Neue Definition ab D4
Fahrzeugmasse in kg. Das Signal dient der Anpassung der Sollbeschleunigung vom ACC


";
CM_ SG_ 1631 TSK_Grundmasse "Fahrzeuggrundmasse in kg. Das Signal dient der Anpassung der Sollbeschleunigung vom ACC

Hinweis: Ehemaliger Fehlerwert 0x7F wird senderseitig nicht unterstützt. Diesen Wert aus Kompatibilitätsgründen nicht neu belegen!";
CM_ SG_ 1631 TSK_Steigung_02 "Steigung in % Berg. Das Signal dient der Anpassung der Sollbeschleunigung vom ACC

Positive Werte > bergauf; 
Negative Werte < bergab

Fehler: Die Steigung aufgrund eines Fehlers (mit KD-Fehlereintrag) nicht mehr berechnet werden";

CM_ SG_ 1648 MO1_Freigabe_Info_WFS "WFS-Freigabeinformation";
CM_ SG_ 1648 MO1_Freigabe_Verfallsinfo_WFS "WFS-Freigabeverfallsinformation";
CM_ SG_ 1648 MO1_Sperr_Info_WFS "WFS-Sperrinformation";
CM_ SG_ 1648 MO_Abstellzeit "Abstelldauer nach letztem KL15 aus

Hinweis: 
Ehemaliger Fehlerwert 0xFF wird senderseitig nicht unterstützt. 
Diesen Wert aus Kompatibilitätsgründen nicht neu belegen!";
CM_ SG_ 1648 MO_Abstellzeit_Status "Statusinformation zur Abstellzeit
0: Die dem Status zugeordnete Variable konnte noch nicht berechnet werden. 
1: Die dem Status zugehörige Variable wurde korrekt berechnet. 
2: Der Wert der zugehörigen Variablen ist nur ein Minimalwert. 
3: Der Wert d";
CM_ SG_ 1648 MO_ANC_Kennfeld_Anf "Anforderung ANC Kennfeldumschaltung";
CM_ SG_ 1648 MO_Anzahl_Abgesch_Zyl "Gibt die Anzahl der abgeschalteten Zylinder an. In Übergangszuständen wird der Zielbetriebszustand angezeigt.";
CM_ SG_ 1648 MO_Bremslicht_Reku "Bremslicht (ggf. bei Rekuperation durch E-Motor) wird angesteuert";
CM_ SG_ 1648 MO_Drehzahl_Warnung "Warnhinweis zum Kombi im Fall einer fehlerbehafteten Drehzahlbegrenzung";
CM_ SG_ 1648 MO_EPCL "Die Anforderung der EPC-Lampe vom MSG ans Kombi soll durch das Bus-Signal MO_EPCL gemäß folgender Logik erfolgen:
MO_EPCL = 0 dez -> EPC Lampe aus, kein Text
MO_EPCL = 1 dez -> gelbe EPC-Symbolik, Text „Antrieb: Störung! Bitte Service aufsuchen“
MO_EPC";
CM_ SG_ 1648 MO_Ethanol_BS_Texte "Ethanol Brennstoff-Texte im Kombi

0 = kein Text
1 = E85 Warm_Up
2 = FlexFuel Warnung 3.Stufe (Too cold for ethanol)
3 = Warmfahrempfehlung MQB / FlexFuel Warnung 1.Stufe (Refuel with gasoline)
4 = FlexFuel Warnung 2. Stufe (Refuel with gasoline)
5";
CM_ SG_ 1648 MO_Fahrzeugtyp "Unterscheidet die Fahrzeugtypen bzgl. der Antriebsart";
CM_ SG_ 1648 MO_Fehler_Zylabsch "Fehlerstatus der Funktion Zylinderabschaltung ";
CM_ SG_ 1648 MO_Hybrid_StartStopp_LED "Ansteuerung der Funktions-LED der Hybrid Taste bzw. Start/Stop Deaktivierungstaste.
Der Start/Stopp-Master (derzeit im MSG) (oder ein künftiger Hybrid-Master) soll die Ansteuerung senden.";
CM_ SG_ 1648 MO_max_Ladedruck "maximal möglicher Ladedruck (zur Anpassung des Anzeigebereichs bei absoluter Ladedruckanzeige)";
CM_ SG_ 1648 MO_NMAX_Schaltanzeige "Maximaldrehzahl für Schaltanzeige";
CM_ SG_ 1648 MO_obere_Drehzahlgrenze "obere Drehzahlgrenze des Motors";
CM_ SG_ 1648 MO_StartStopp_PopUp "Das Signal zeigt an, ob der StSt-Status mittels Deaktivierungstaster geändert wurde. Ein Wechsel auf die Werte 01 oder 10 löst im Kombi ein entsprechendes PopUp aus. Bei einem Statuswechsel durch andere Signalquellen (z.B. Charisma, fehlerbedingte Abschal";
CM_ SG_ 1648 MO_Zylabsch_Texte "Zylinderabschaltung mode in Kombi, fuer Zylinderabschaltung";
CM_ SG_ 1648 MO_Zylabsch_Texte_02 "ZAS-Anzeige für den Fahrer im Kombi
0: kein ZAS (generell keinerlei ZAS-Anzeigen)  (Init für nicht ZAS-Motor)
1: ZAS im Vollmotorbetrieb  (Init für ZAS-Motor)
2: ZAS im Abschaltbetrieb: 1 Zyl aktiv
3: ZAS im Abschaltbetrieb: 2 Zyl aktiv
4: ZAS im Abs";

CM_ SG_ 289 MO_Entkopplung_Sollschlupf "MSG fordert von GSG an, das Anfahrelement (Fahr-/Wandlerkupplung) zu entkoppeln; das GSG soll die gesendete Drehzahl als Schlupf einstellen und ggf. die Regler-Parameter umschalten, damit Rucke aus dem Antrieb nicht im Fahrzeug spürbar werden; nutzbar z.B";
CM_ SG_ 289 MO_Fahrpedalgradient "Das Motorsteuergerät besitzt 2 analoge Fahrpedalsignale. Das Signal des ersten Kanals wird alle 4ms abgetastet. Um Bitschwankungen des A/D-Wandler herauszufiltern wird das Signal entjittert. Anschließend wird der Gradient berechnet. Entsprechend der Zyklu";
CM_ SG_ 289 MO_Fahrpedalrohwert_01 "AUDI D4: Zykluszeit: 10ms (siehe Zykluszeit schnell/Cycletime Fast)

Stellung des Fahrpedales (Rohwert, ohne Überlagerung durch GRA-Eingriffe etc.)

Die Funktionen zur Berechung des Fahrpedalrohwerts laufen im 10ms Raster. Der Fahrpedalwert berechnet ";
CM_ SG_ 289 MO_Moment_im_Leerlauf "Fahrerwunschmoment ist minimal: keine Momentenanforderung durch Fahrpedal, ACC oder GRA+; (Das Signal ist unabhängig von Momentenerhöhungen durch Leerlaufregler oder MSR).

AUDI D4: Zykluszeit: 10ms (siehe Zykluszeit schnell/Cycletime Fast)

Achtung:";
CM_ SG_ 289 MO_QBit_Fahrpedalwerte_01 "AUDI D4: Zykluszeit: 10ms (siehe Zykluszeit schnell/Cycletime Fast)

QBit für beide Fahrpedalwerte des Motors (Fahrpedalrohsignal für ESP, EPB, ACC; Fahrpedalwert für Getriebe)

Achtung:
Reduktion der Zykluszeit Motor_03 auf 10ms geplant.
Projektabh";
CM_ SG_ 289 MO_rel_Saugrohrdruck "Der Wert gibt an, um wieviel mbar der Saugrohrdruck unterhalb des Umgebungsdrucks liegt. Überdruck im Saugrohr wird nicht ausgegeben.
0: Saugrohrdruck=Umgebungsdruck";
CM_ SG_ 289 MO_rel_Saugrohrdruck_gem_err "0: mind. eine Modellrechnung wird zur Berechnung des relativen Saugdrucks herangezogen
1: Relativer Saugrohrdruck wird ausschließlich über Messgrößen bestimmt";
CM_ SG_ 289 MO_Schubabschaltung "ESP plausibilisiert Unterdrucksensor nur bei aktiver Schubabschaltung";
CM_ SG_ 289 MO_Sig_Fahrpedalgradient "Kennzeichnet das Vorzeichen des Signal 'Fahrpedalgradient'. Die Ausgabe erfolgt nur parallel statisch mit gesendetem Signal: 'Steuerungsbit Fahrpedalgradient' ";
CM_ SG_ 289 MO_Solldrehz_Leerlauf "Leerlaufsolldrehzahl, die im Motor eingestellt ist (Bei Parallelhybrid im E-Fahr-Betrieb Leerlaufsolldrehzahl der E-Maschine). Der Motor paßt aufgrund der Anforderung von anderen Steuergeräten seine Leerlaufsolldrehzahl an, bspw. Kat-Heizen, Anforderung v";
CM_ SG_ 289 MO_StartStopp_StoppVorbereitung "Zeigt allen aktiven Start-/Stoppteilnehmern einen möglichen Motorstopp im Anhaltevorgang an (Empfänger notwendige Vorbereitungen treffen)
Es liegen keine Vetos vor.";
CM_ SG_ 289 MO_temporaere_Fahrerabwesenheit "Das Signal dient zur Signalisierung einer temporären Abwesenheit des Fahrers. In dieser Zeit ist es ihm möglich, sich durch gewisse ¿ im Verlassenskonzept definierte ¿ Fahreraktionen im aktuellen Fahrzyklus zurückzumelden.
Das Signal wird gesetzt, sobald";
CM_ SG_ 289 Motor_20_CRC "Für MLB:
'Berechnung siehe Lastenheft 'Kommunikationsabsicherung für FlexRay und CAN''

Ab MQB und MLBevo:
'Berechnung siehe Lastenheft 'End-to-End Kommunikationsabsicherung'

Endwerte siehe Begleitdokument 'S-PDU Kennungsfolgen'";
CM_ SG_ 289 TSK_a_Soll_gradientenbegrenzt "TSK Sollbeschleunigung für Fahrerassistenzsysteme mit aktiver Längsführung (GRA, ACC, IPA...). Der Wert stellt den ruckbegrenzten Sollwert der TSK-Regelung dar und ist Basis der TSK-Antriebs- und Bremsmomentenvorsteuerung.";

CM_ SG_ 283 MO_EBoost_verf_praed "Zeigt an, ob für eine im Projekt definierte Zeit (max. 10s) E-Boost in Höhe von EM1_maxPred_Moment verfügbar sein wird.

0 - Init_oder_nicht_verfügbar
1 - EBoost_kurzzeit_verfügbar (~3Sek.)
2 - EBoost_langzeit_verfügbar (~10Sek)";
CM_ SG_ 283 MO_eLaunch_verf "Zeigt an, ob aus Antriebssicht E-Launch verfügbar ist.";
CM_ SG_ 283 MO_EnergyAssist_Aktivierbar "Das Signal MO_AEA_Aktivierbarkeit zeigt an, ob die Routenführung in der Navigation aktiv ist, die Longrange-PSD übertragen werden und der Audi energy assist aktivierbar ist.";
CM_ SG_ 283 MO_Fahrbereitschaft "Das Signal MO_Fahrbereitschaft zeigt in mehreren Stufen an, ob der Motor in einem anfahrbereiten Zustand ist.";
CM_ SG_ 283 MO_Freilauf_Info "Freilauf Informationssignal vom Motorsteuergerät zum Getriebesteuergerät. Das Motorsteuergerät kann über dieses Signal den Freilauf freigeben, verhindern bzw. explizit anfordern.";
CM_ SG_ 283 MO_Freilauf_Status "Freilauf-Status-Signal vom Frailauf-Master an aktive Freilauf-Teilnehmer. In diesem Signal zeigt der Freilauf-Master an, welchen aktuellen Status die Freilauf-Betriebsstrategie hat.";
CM_ SG_ 283 MO_Heckspoiler_Anf "Anforderung den Heckspoiler zur Ladeluft- bzw. Motorraumkühlung auszufahren.";
CM_ SG_ 283 MO_Krit_Heckobjekt "Beschreibt die Kritikalität des hinter einem in der Spur fahrenden Fahrzeuges";
CM_ SG_ 283 MO_NGS_Gangpos "Gang- bzw. Neutralinformation des erweiterten Neutralgangsensors. Bedingt durch den eingeschränkten Erfassungssbereich des Sensors sind die Ganginformationen als eingelegt bzw. fast eingelegt/vorausgewählt zu interpretieren (nur Handschalter)";
BA_DEF_REL_ BU_SG_REL_  "GenSigTimeoutTime" INT 0 65535;
BA_DEF_ BO_  "DiagRequest" ENUM "No", "Yes";
BA_DEF_ BO_  "DiagResponse" ENUM "No", "Yes";
BA_DEF_ BO_  "DiagState" ENUM "No", "Yes";
BA_DEF_ BO_  "GenMsgChkConstant" HEX 0 4095;
BA_DEF_ BO_  "GenMsgCycleTime" INT 0 65535;
BA_DEF_ BO_  "GenMsgCycleTimeFast" INT 0 65535;
BA_DEF_ BO_  "GenMsgDelayTime" INT 0 100000;
BA_DEF_ BO_  "GenMsgILSupport" ENUM "No", "Yes";
BA_DEF_ BO_  "GenMsgNrOfRepetition" INT 0 100;
BA_DEF_ BO_  "GenMsgPDUConstants" STRING;
BA_DEF_ BO_  "GenMsgSendType" ENUM "Cyclic", "not_used", "not_used", "not_used", "not_used", "not_used", "not_used", "IfActive", "NoMsgSendType";
BA_DEF_ BO_  "GenMsgStartDelayTime" INT 0 100000;
BA_DEF_ BO_  "NmMessage" ENUM "No", "Yes";
BA_DEF_ BO_  "NmhMessage" ENUM "No", "Yes";
BA_DEF_ BO_  "MsgType" ENUM "Application", "NM ", "NMH", "TP2.0", "ISO-TP ", "BAP", "EID", "KS";
BA_DEF_ BO_  "VAGTP20_API" HEX 0 255;
BA_DEF_ BO_  "VAGTP20_DynConnection" ENUM "No", "Yes";
BA_DEF_ BO_  "VAGTP20_DynSetup" ENUM "No", "Yes";
BA_DEF_ BO_  "VAGTP20_StatConnection" ENUM "No", "Yes";
BA_DEF_ SG_  "GenSigActiveRepetitions" INT -2147483648 2147483647;
BA_DEF_ SG_  "GenSigInactiveValue" INT -2147483648 2147483647;
BA_DEF_ SG_  "GenSigSendType" ENUM "Cyclic", "OnWrite", "OnWriteWithRepetition", "OnChange", "OnChangeWithRepetition", "IfActive", "IfActiveWithRepetition", "NoSigSendType", "OnChangeAndIfActive", "OnChangeAndIfActiveWithRepetition";
BA_DEF_ SG_  "GenSigStartValue" INT -2147483648 2147483647;
BA_DEF_ SG_  "NWM-WakeupAllowed" ENUM "No", "Yes";
BA_DEF_ SG_  "GenSigFuncType" ENUM "NoFunction", "MsgCounter", "CRC-8", "XOR", "XOR-2", "DatedBit", "SW-Kl15", "CHK", "Constant", "Protocol", "CRC-8-SAE_J1850";
BA_DEF_ SG_  "GenSigSwitchedByIgnition" ENUM "No", "Yes";
BA_DEF_ SG_  "Fehlerwert" HEX 0 2147483647;
BA_DEF_ SG_  "GenSigMissingSourceValue" HEX 0 2147483647;
BA_DEF_DEF_REL_  "GenSigTimeoutTime" 0;
BA_DEF_DEF_  "DiagRequest" "No";
BA_DEF_DEF_  "DiagResponse" "No";
BA_DEF_DEF_  "DiagState" "No";
BA_DEF_DEF_  "GenMsgChkConstant" 0;
BA_DEF_DEF_  "GenMsgCycleTime" 0;
BA_DEF_DEF_  "GenMsgCycleTimeFast" 0;
BA_DEF_DEF_  "GenMsgDelayTime" 0;
BA_DEF_DEF_  "GenMsgILSupport" "No";
BA_DEF_DEF_  "GenMsgNrOfRepetition" 0;
BA_DEF_DEF_  "GenMsgPDUConstants" "";
BA_DEF_DEF_  "GenMsgSendType" "NoMsgSendType";
BA_DEF_DEF_  "GenMsgStartDelayTime" 0;
BA_DEF_DEF_  "NmMessage" "No";
BA_DEF_DEF_  "NmhMessage" "No";
BA_DEF_DEF_  "MsgType" "Application";
BA_DEF_DEF_  "VAGTP20_API" 0;
BA_DEF_DEF_  "VAGTP20_DynConnection" "No";
BA_DEF_DEF_  "VAGTP20_DynSetup" "No";
BA_DEF_DEF_  "VAGTP20_StatConnection" "No";
BA_DEF_DEF_  "GenSigActiveRepetitions" 0;
BA_DEF_DEF_  "GenSigInactiveValue" 0;
BA_DEF_DEF_  "GenSigSendType" "NoSigSendType";
BA_DEF_DEF_  "GenSigStartValue" 0;
BA_DEF_DEF_  "NWM-WakeupAllowed" "No";
BA_DEF_DEF_  "GenSigFuncType" "NoFunction";
BA_DEF_DEF_  "GenSigSwitchedByIgnition" "Yes";
BA_DEF_DEF_  "Fehlerwert" 0;
BA_DEF_DEF_  "GenSigMissingSourceValue" 0;
BA_ "GenMsgCycleTime" BO_ 779 50;
BA_ "GenMsgILSupport" BO_ 779 1;
BA_ "GenMsgSendType" BO_ 779 0;
BA_ "GenMsgCycleTime" BO_ 1719 1000;
BA_ "GenMsgDelayTime" BO_ 1719 100;
BA_ "GenMsgILSupport" BO_ 1719 1;
BA_ "GenMsgSendType" BO_ 1719 0;
BA_ "GenMsgCycleTime" BO_ 1720 1000;
BA_ "GenMsgILSupport" BO_ 1720 1;
BA_ "GenMsgSendType" BO_ 1720 0;
BA_ "GenMsgChkConstant" BO_ 810 41;
BA_ "GenMsgCycleTime" BO_ 810 50;
BA_ "GenMsgILSupport" BO_ 810 1;
BA_ "GenMsgPDUConstants" BO_ 810 "0x29,0x29,0x29,0x29,0x29,0x29,0x29,0x29,0x29,0x29,0x29,0x29,0x29,0x29,0x29,0x29";
BA_ "GenMsgSendType" BO_ 810 0;
BA_ "GenMsgChkConstant" BO_ 285 28;
BA_ "GenMsgCycleTime" BO_ 285 20;
BA_ "GenMsgILSupport" BO_ 285 1;
BA_ "GenMsgPDUConstants" BO_ 285 "0x1c,0x1c,0x1c,0x1c,0x1c,0x1c,0x1c,0x1c,0x1c,0x1c,0x1c,0x1c,0x1c,0x1c,0x1c,0x1c";
BA_ "GenMsgSendType" BO_ 285 0;
BA_ "GenMsgChkConstant" BO_ 159 245;
BA_ "GenMsgCycleTime" BO_ 159 10;
BA_ "GenMsgILSupport" BO_ 159 1;
BA_ "GenMsgPDUConstants" BO_ 159 "0xf5,0xf5,0xf5,0xf5,0xf5,0xf5,0xf5,0xf5,0xf5,0xf5,0xf5,0xf5,0xf5,0xf5,0xf5,0xf5";
BA_ "GenMsgSendType" BO_ 159 0;
BA_ "GenMsgChkConstant" BO_ 134 134;
BA_ "GenMsgCycleTime" BO_ 134 10;
BA_ "GenMsgILSupport" BO_ 134 1;
BA_ "GenMsgPDUConstants" BO_ 134 "0x86,0x86,0x86,0x86,0x86,0x86,0x86,0x86,0x86,0x86,0x86,0x86,0x86,0x86,0x86,0x86";
BA_ "GenMsgSendType" BO_ 134 0;
BA_ "GenMsgCycleTime" BO_ 917 100;
BA_ "GenMsgDelayTime" BO_ 917 10;
BA_ "GenMsgILSupport" BO_ 917 1;
BA_ "GenMsgSendType" BO_ 917 0;
BA_ "GenMsgCycleTime" BO_ 1600 500;
BA_ "GenMsgILSupport" BO_ 1600 1;
BA_ "GenMsgSendType" BO_ 1600 0;
BA_ "GenMsgCycleTime" BO_ 167 10;
BA_ "GenMsgILSupport" BO_ 167 1;
BA_ "GenMsgPDUConstants" BO_ 167 "0xd2,0x3d,0xcd,0x28,0x4c,0x14,0x22,0x4b,0x24,0xac,0xfa,0x55,0x66,0x80,0x0d,0x6c";
BA_ "GenMsgSendType" BO_ 167 0;
BA_ "GenMsgCycleTime" BO_ 168 10;
BA_ "GenMsgILSupport" BO_ 168 1;
BA_ "GenMsgPDUConstants" BO_ 168 "0x52,0x8c,0x50,0xee,0x4f,0xa6,0xcc,0xcf,0x7d,0x2f,0x98,0x6b,0x27,0x41,0x9f,0x93";
BA_ "GenMsgSendType" BO_ 168 0;
BA_ "GenMsgCycleTime" BO_ 958 100;
BA_ "GenMsgDelayTime" BO_ 958 10;
BA_ "GenMsgILSupport" BO_ 958 1;
BA_ "GenMsgPDUConstants" BO_ 958 "0x1f,0x28,0xc6,0x85,0xe6,0xf8,0xb0,0x19,0x5b,0x64,0x35,0x21,0xe4,0xf7,0x9c,0x24";
BA_ "GenMsgSendType" BO_ 958 0;
BA_ "GenMsgCycleTime" BO_ 1631 500;
BA_ "GenMsgILSupport" BO_ 1631 1;
BA_ "GenMsgSendType" BO_ 1631 0;
BA_ "GenMsgCycleTime" BO_ 1648 500;
BA_ "GenMsgDelayTime" BO_ 1648 20;
BA_ "GenMsgILSupport" BO_ 1648 1;
BA_ "GenMsgSendType" BO_ 1648 0;
BA_ "GenMsgCycleTime" BO_ 289 20;
BA_ "GenMsgILSupport" BO_ 289 1;
BA_ "GenMsgPDUConstants" BO_ 289 "0xe9,0x65,0xae,0x6b,0x7b,0x35,0xe5,0x5f,0x4e,0xc7,0x86,0xa2,0xbb,0xdd,0xeb,0xb4";
BA_ "GenMsgSendType" BO_ 289 0;
BA_ "GenMsgCycleTime" BO_ 283 100;
BA_ "GenMsgDelayTime" BO_ 283 10;
BA_ "GenMsgILSupport" BO_ 283 1;
BA_ "GenMsgSendType" BO_ 283 0;
BA_ "GenSigSendType" SG_ 779 KBI_ABS_Lampe 0;
BA_ "GenSigSwitchedByIgnition" SG_ 779 KBI_ABS_Lampe 0;
BA_ "GenSigSendType" SG_ 779 KBI_Airbag_Lampe 0;
BA_ "GenSigSwitchedByIgnition" SG_ 779 KBI_Airbag_Lampe 0;
BA_ "GenSigSendType" SG_ 779 KBI_angez_Geschw 0;
BA_ "GenSigSwitchedByIgnition" SG_ 779 KBI_angez_Geschw 0;
BA_ "GenSigSendType" SG_ 779 KBI_Anzeigefehler_LDW 0;
BA_ "GenSigSwitchedByIgnition" SG_ 779 KBI_Anzeigefehler_LDW 0;
BA_ "GenSigSendType" SG_ 779 KBI_Anzeigefehler_NV 0;
BA_ "GenSigSwitchedByIgnition" SG_ 779 KBI_Anzeigefehler_NV 0;
BA_ "GenSigSendType" SG_ 779 KBI_Anzeigefehler_SWA 0;
BA_ "GenSigSwitchedByIgnition" SG_ 779 KBI_Anzeigefehler_SWA 0;
BA_ "GenSigSendType" SG_ 779 KBI_Anzeigestatus_ACC 0;
BA_ "GenSigSwitchedByIgnition" SG_ 779 KBI_Anzeigestatus_ACC 0;
BA_ "GenSigSendType" SG_ 779 KBI_Anzeigestatus_GRA 0;
BA_ "GenSigSwitchedByIgnition" SG_ 779 KBI_Anzeigestatus_GRA 0;
BA_ "Fehlerwert" SG_ 779 KBI_Anzeigestatus_GRA 3;
BA_ "GenSigSendType" SG_ 779 KBI_Anzeigestatus_LIM 0;
BA_ "GenSigSwitchedByIgnition" SG_ 779 KBI_Anzeigestatus_LIM 0;
BA_ "Fehlerwert" SG_ 779 KBI_Anzeigestatus_LIM 3;
BA_ "GenSigSendType" SG_ 779 KBI_ARA_in_Anzeige 0;
BA_ "GenSigSwitchedByIgnition" SG_ 779 KBI_ARA_in_Anzeige 0;
BA_ "GenSigSendType" SG_ 779 KBI_BKL_Lampe 0;
BA_ "GenSigSwitchedByIgnition" SG_ 779 KBI_BKL_Lampe 0;
BA_ "GenSigSendType" SG_ 779 KBI_Einheit_Tacho 0;
BA_ "GenSigSwitchedByIgnition" SG_ 779 KBI_Einheit_Tacho 0;
BA_ "GenSigSendType" SG_ 779 KBI_ESP_Lampe 0;
BA_ "GenSigSwitchedByIgnition" SG_ 779 KBI_ESP_Lampe 0;
BA_ "GenSigSendType" SG_ 779 KBI_Fehler_Anzeige_ACC 0;
BA_ "GenSigSwitchedByIgnition" SG_ 779 KBI_Fehler_Anzeige_ACC 0;
BA_ "GenSigSendType" SG_ 779 KBI_Handbremse 0;
BA_ "GenSigSwitchedByIgnition" SG_ 779 KBI_Handbremse 0;
BA_ "GenSigSendType" SG_ 779 KBI_im_Stellgliedtest 0;
BA_ "GenSigSwitchedByIgnition" SG_ 779 KBI_im_Stellgliedtest 0;
BA_ "GenSigSendType" SG_ 779 KBI_Konsistenz_ACC 0;
BA_ "GenSigSwitchedByIgnition" SG_ 779 KBI_Konsistenz_ACC 0;
BA_ "GenSigSendType" SG_ 779 KBI_Lenkung_Lampe 0;
BA_ "GenSigSwitchedByIgnition" SG_ 779 KBI_Lenkung_Lampe 0;
BA_ "GenSigSendType" SG_ 779 KBI_MFA_v_Einheit_01 0;
BA_ "GenSigSwitchedByIgnition" SG_ 779 KBI_MFA_v_Einheit_01 0;
BA_ "GenSigSendType" SG_ 779 KBI_NV_in_Anzeige 0;
BA_ "GenSigSwitchedByIgnition" SG_ 779 KBI_NV_in_Anzeige 0;
BA_ "GenSigSendType" SG_ 779 KBI_Oeldruck_Schalter 0;
BA_ "GenSigSwitchedByIgnition" SG_ 779 KBI_Oeldruck_Schalter 0;
BA_ "GenSigSendType" SG_ 779 KBI_Oeldruckwarnung 0;
BA_ "GenSigSwitchedByIgnition" SG_ 779 KBI_Oeldruckwarnung 0;
BA_ "GenSigSendType" SG_ 779 KBI_PLA_in_Anzeige 0;
BA_ "GenSigSwitchedByIgnition" SG_ 779 KBI_PLA_in_Anzeige 0;
BA_ "GenSigSendType" SG_ 779 KBI_SILA_gueltig 0;
BA_ "GenSigSwitchedByIgnition" SG_ 779 KBI_SILA_gueltig 0;
BA_ "GenSigSendType" SG_ 779 KBI_Tankwarnung 0;
BA_ "GenSigSwitchedByIgnition" SG_ 779 KBI_Tankwarnung 0;
BA_ "GenSigSendType" SG_ 779 KBI_V_Digital 0;
BA_ "GenSigSwitchedByIgnition" SG_ 779 KBI_V_Digital 0;
BA_ "GenSigSendType" SG_ 779 KBI_Vorglueh_System_Lampe 0;
BA_ "GenSigSwitchedByIgnition" SG_ 779 KBI_Vorglueh_System_Lampe 0;
BA_ "GenSigSendType" SG_ 779 Kombi_01_BZ 0;
BA_ "GenSigFuncType" SG_ 779 Kombi_01_BZ 1;
BA_ "GenSigSwitchedByIgnition" SG_ 779 Kombi_01_BZ 0;
BA_ "GenSigSendType" SG_ 1719 KBI_aktive_Laengsfunktion 3;
BA_ "GenSigSendType" SG_ 1719 KBI_Aussen_Temp_gef 0;
BA_ "GenSigStartValue" SG_ 1719 KBI_Aussen_Temp_gef 254;
BA_ "GenSigSwitchedByIgnition" SG_ 1719 KBI_Aussen_Temp_gef 0;
BA_ "Fehlerwert" SG_ 1719 KBI_Aussen_Temp_gef 255;
BA_ "GenSigSendType" SG_ 1719 KBI_FStatus_Tank 0;
BA_ "GenSigSwitchedByIgnition" SG_ 1719 KBI_FStatus_Tank 0;
BA_ "GenSigSendType" SG_ 1719 KBI_Inhalt_Tank 0;
BA_ "GenSigStartValue" SG_ 1719 KBI_Inhalt_Tank 126;
BA_ "GenSigSwitchedByIgnition" SG_ 1719 KBI_Inhalt_Tank 0;
BA_ "Fehlerwert" SG_ 1719 KBI_Inhalt_Tank 127;
BA_ "GenSigSendType" SG_ 1719 KBI_Kilometerstand 0;
BA_ "GenSigStartValue" SG_ 1719 KBI_Kilometerstand 1048574;
BA_ "GenSigSwitchedByIgnition" SG_ 1719 KBI_Kilometerstand 0;
BA_ "Fehlerwert" SG_ 1719 KBI_Kilometerstand 1048575;
BA_ "GenSigSendType" SG_ 1719 KBI_Oelwechsel_durchgefuehrt 0;
BA_ "GenSigSwitchedByIgnition" SG_ 1719 KBI_Oelwechsel_durchgefuehrt 0;
BA_ "GenSigSendType" SG_ 1719 KBI_QBit_Aussen_Temp_gef 0;
BA_ "GenSigStartValue" SG_ 1719 KBI_QBit_Aussen_Temp_gef 1;
BA_ "GenSigSwitchedByIgnition" SG_ 1719 KBI_QBit_Aussen_Temp_gef 0;
BA_ "GenSigSendType" SG_ 1719 KBI_RDK_Kalibrier_Anf 3;
BA_ "GenSigSwitchedByIgnition" SG_ 1719 KBI_RDK_Kalibrier_Anf 0;
BA_ "GenSigSendType" SG_ 1719 KBI_Reserve_Warnung_Sek 3;
BA_ "GenSigSwitchedByIgnition" SG_ 1719 KBI_Reserve_Warnung_Sek 0;
BA_ "GenSigSendType" SG_ 1719 KBI_Standzeit_02 0;
BA_ "GenSigStartValue" SG_ 1719 KBI_Standzeit_02 131070;
BA_ "GenSigSwitchedByIgnition" SG_ 1719 KBI_Standzeit_02 0;
BA_ "Fehlerwert" SG_ 1719 KBI_Standzeit_02 131071;
BA_ "GenSigSendType" SG_ 1720 KBI_BCmE_aktiv 0;
BA_ "GenSigSwitchedByIgnition" SG_ 1720 KBI_BCmE_aktiv 0;
BA_ "GenSigSendType" SG_ 1720 KBI_Max_Tankinhalt 0;
BA_ "GenSigStartValue" SG_ 1720 KBI_Max_Tankinhalt 254;
BA_ "GenSigSwitchedByIgnition" SG_ 1720 KBI_Max_Tankinhalt 0;
BA_ "Fehlerwert" SG_ 1720 KBI_Max_Tankinhalt 255;
BA_ "GenSigSendType" SG_ 1720 KBI_Nachtanken_erkannt 0;
BA_ "GenSigSwitchedByIgnition" SG_ 1720 KBI_Nachtanken_erkannt 0;
BA_ "GenSigSendType" SG_ 1720 KBI_Reifenumfang 0;
BA_ "GenSigFuncType" SG_ 1720 KBI_Reifenumfang 8;
BA_ "GenSigSwitchedByIgnition" SG_ 1720 KBI_Reifenumfang 0;
BA_ "GenSigSendType" SG_ 1720 KBI_Reifenumfang_Sekundaer 0;
BA_ "GenSigSwitchedByIgnition" SG_ 1720 KBI_Reifenumfang_Sekundaer 0;
BA_ "GenSigSendType" SG_ 1720 KBI_Sparhinweis_quittiert 0;
BA_ "GenSigSwitchedByIgnition" SG_ 1720 KBI_Sparhinweis_quittiert 0;
BA_ "GenSigSendType" SG_ 1720 KBI_Tankfuellstand_Prozent 0;
BA_ "GenSigStartValue" SG_ 1720 KBI_Tankfuellstand_Prozent 126;
BA_ "GenSigSwitchedByIgnition" SG_ 1720 KBI_Tankfuellstand_Prozent 0;
BA_ "Fehlerwert" SG_ 1720 KBI_Tankfuellstand_Prozent 127;
BA_ "GenSigSendType" SG_ 1720 KBI_Tankinhalt_hochaufl 0;
BA_ "GenSigStartValue" SG_ 1720 KBI_Tankinhalt_hochaufl 16382;
BA_ "GenSigSwitchedByIgnition" SG_ 1720 KBI_Tankinhalt_hochaufl 0;
BA_ "Fehlerwert" SG_ 1720 KBI_Tankinhalt_hochaufl 16383;
BA_ "GenSigSendType" SG_ 1720 KBI_Variante 0;
BA_ "GenSigSwitchedByIgnition" SG_ 1720 KBI_Variante 0;
BA_ "GenSigSendType" SG_ 1720 KBI_Variante_USA 0;
BA_ "GenSigSwitchedByIgnition" SG_ 1720 KBI_Variante_USA 0;
BA_ "GenSigSendType" SG_ 810 EPS_01_BZ 0;
BA_ "GenSigFuncType" SG_ 810 EPS_01_BZ 1;
BA_ "GenSigSwitchedByIgnition" SG_ 810 EPS_01_BZ 0;
BA_ "GenSigSendType" SG_ 810 EPS_01_CRC 0;
BA_ "GenSigFuncType" SG_ 810 EPS_01_CRC 2;
BA_ "GenSigSwitchedByIgnition" SG_ 810 EPS_01_CRC 0;
BA_ "GenSigSendType" SG_ 810 EPS_Akustiksignal 0;
BA_ "GenSigSwitchedByIgnition" SG_ 810 EPS_Akustiksignal 0;
BA_ "GenSigSendType" SG_ 810 EPS_Anf_KL 0;
BA_ "GenSigSwitchedByIgnition" SG_ 810 EPS_Anf_KL 0;
BA_ "GenSigSendType" SG_ 810 EPS_ARA_Status 0;
BA_ "GenSigSwitchedByIgnition" SG_ 810 EPS_ARA_Status 0;
BA_ "GenSigSendType" SG_ 810 EPS_Charisma_FahrPr 0;
BA_ "GenSigSwitchedByIgnition" SG_ 810 EPS_Charisma_FahrPr 0;
BA_ "GenSigSendType" SG_ 810 EPS_Charisma_Status 0;
BA_ "GenSigSwitchedByIgnition" SG_ 810 EPS_Charisma_Status 0;
BA_ "GenSigSendType" SG_ 810 EPS_Fehlerlampe 0;
BA_ "GenSigSwitchedByIgnition" SG_ 810 EPS_Fehlerlampe 0;
BA_ "GenSigSendType" SG_ 810 EPS_Lenkerposition 0;
BA_ "GenSigFuncType" SG_ 810 EPS_Lenkerposition 8;
BA_ "GenSigSwitchedByIgnition" SG_ 810 EPS_Lenkerposition 0;
BA_ "GenSigSendType" SG_ 810 EPS_PLA_Abbruch 0;
BA_ "GenSigSwitchedByIgnition" SG_ 810 EPS_PLA_Abbruch 0;
BA_ "GenSigSendType" SG_ 810 EPS_PLA_Fehler 0;
BA_ "GenSigSwitchedByIgnition" SG_ 810 EPS_PLA_Fehler 0;
BA_ "GenSigSendType" SG_ 810 EPS_PLA_Status 0;
BA_ "GenSigSwitchedByIgnition" SG_ 810 EPS_PLA_Status 0;
BA_ "GenSigSendType" SG_ 810 EPS_SpannungsAnf 0;
BA_ "GenSigSwitchedByIgnition" SG_ 810 EPS_SpannungsAnf 0;
BA_ "GenSigSendType" SG_ 810 EPS_Warnungen 0;
BA_ "GenSigSwitchedByIgnition" SG_ 810 EPS_Warnungen 0;
BA_ "GenSigSendType" SG_ 285 EPS_02_BZ 0;
BA_ "GenSigFuncType" SG_ 285 EPS_02_BZ 1;
BA_ "GenSigSwitchedByIgnition" SG_ 285 EPS_02_BZ 0;
BA_ "GenSigSendType" SG_ 285 EPS_02_CRC 0;
BA_ "GenSigFuncType" SG_ 285 EPS_02_CRC 2;
BA_ "GenSigSwitchedByIgnition" SG_ 285 EPS_02_CRC 0;
BA_ "GenSigSendType" SG_ 285 EPS_Drehzahlreserve 0;
BA_ "GenSigStartValue" SG_ 285 EPS_Drehzahlreserve 126;
BA_ "GenSigSwitchedByIgnition" SG_ 285 EPS_Drehzahlreserve 0;
BA_ "Fehlerwert" SG_ 285 EPS_Drehzahlreserve 127;
BA_ "GenSigSendType" SG_ 285 EPS_Lastinfo 0;
BA_ "GenSigStartValue" SG_ 285 EPS_Lastinfo 254;
BA_ "GenSigSwitchedByIgnition" SG_ 285 EPS_Lastinfo 0;
BA_ "Fehlerwert" SG_ 285 EPS_Lastinfo 255;
BA_ "GenSigSendType" SG_ 285 EPS_Leistungsanforderung 0;
BA_ "GenSigSwitchedByIgnition" SG_ 285 EPS_Leistungsanforderung 0;
BA_ "GenSigSendType" SG_ 285 EPS_Motorstartverzoegerung 0;
BA_ "GenSigSwitchedByIgnition" SG_ 285 EPS_Motorstartverzoegerung 0;
BA_ "GenSigSendType" SG_ 285 EPS_Notlauf 0;
BA_ "GenSigSwitchedByIgnition" SG_ 285 EPS_Notlauf 0;
BA_ "GenSigSendType" SG_ 285 EPS_StartStopp_Info 0;
BA_ "GenSigSwitchedByIgnition" SG_ 285 EPS_StartStopp_Info 0;
BA_ "GenSigSendType" SG_ 285 EPS_Unterstuetzungsleistung 0;
BA_ "GenSigStartValue" SG_ 285 EPS_Unterstuetzungsleistung 254;
BA_ "GenSigSwitchedByIgnition" SG_ 285 EPS_Unterstuetzungsleistung 0;
BA_ "Fehlerwert" SG_ 285 EPS_Unterstuetzungsleistung 255;
BA_ "GenSigSendType" SG_ 285 EPS_VZ_Drehzahlreserve 0;
BA_ "GenSigSwitchedByIgnition" SG_ 285 EPS_VZ_Drehzahlreserve 0;
BA_ "GenSigSendType" SG_ 159 EPS_03_BZ 0;
BA_ "GenSigFuncType" SG_ 159 EPS_03_BZ 1;
BA_ "GenSigSwitchedByIgnition" SG_ 159 EPS_03_BZ 0;
BA_ "GenSigSendType" SG_ 159 EPS_03_CRC 0;
BA_ "GenSigFuncType" SG_ 159 EPS_03_CRC 2;
BA_ "GenSigSwitchedByIgnition" SG_ 159 EPS_03_CRC 0;
BA_ "GenSigSendType" SG_ 159 EPS_Berechneter_LW 0;
BA_ "GenSigStartValue" SG_ 159 EPS_Berechneter_LW 4094;
BA_ "GenSigSwitchedByIgnition" SG_ 159 EPS_Berechneter_LW 0;
BA_ "Fehlerwert" SG_ 159 EPS_Berechneter_LW 4095;
BA_ "GenSigSendType" SG_ 159 EPS_BLW_QBit 0;
BA_ "GenSigSwitchedByIgnition" SG_ 159 EPS_BLW_QBit 0;
BA_ "GenSigSendType" SG_ 159 EPS_DSR_Status 0;
BA_ "GenSigSwitchedByIgnition" SG_ 159 EPS_DSR_Status 0;
BA_ "GenSigSendType" SG_ 159 EPS_HCA_Status 0;
BA_ "GenSigStartValue" SG_ 159 EPS_HCA_Status 3;
BA_ "GenSigSwitchedByIgnition" SG_ 159 EPS_HCA_Status 0;
BA_ "GenSigSendType" SG_ 159 EPS_Lenkmoment 0;
BA_ "GenSigStartValue" SG_ 159 EPS_Lenkmoment 1022;
BA_ "GenSigSwitchedByIgnition" SG_ 159 EPS_Lenkmoment 0;
BA_ "Fehlerwert" SG_ 159 EPS_Lenkmoment 1023;
BA_ "GenSigSendType" SG_ 159 EPS_Lenkmoment_QBit 0;
BA_ "GenSigSwitchedByIgnition" SG_ 159 EPS_Lenkmoment_QBit 0;
BA_ "GenSigSendType" SG_ 159 EPS_Lenkungstyp 0;
BA_ "GenSigStartValue" SG_ 159 EPS_Lenkungstyp 15;
BA_ "GenSigSwitchedByIgnition" SG_ 159 EPS_Lenkungstyp 0;
BA_ "GenSigSendType" SG_ 159 EPS_VZ_BLW 0;
BA_ "GenSigSwitchedByIgnition" SG_ 159 EPS_VZ_BLW 0;
BA_ "GenSigSendType" SG_ 159 EPS_VZ_Lenkmoment 0;
BA_ "GenSigSwitchedByIgnition" SG_ 159 EPS_VZ_Lenkmoment 0;
BA_ "GenSigSendType" SG_ 134 LWI_01_BZ 0;
BA_ "GenSigFuncType" SG_ 134 LWI_01_BZ 1;
BA_ "GenSigSendType" SG_ 134 LWI_01_CRC 0;
BA_ "GenSigFuncType" SG_ 134 LWI_01_CRC 2;
BA_ "GenSigSwitchedByIgnition" SG_ 134 LWI_01_CRC 0;
BA_ "GenSigSendType" SG_ 134 LWI_Lenkradw_Geschw 0;
BA_ "GenSigStartValue" SG_ 134 LWI_Lenkradw_Geschw 510;
BA_ "Fehlerwert" SG_ 134 LWI_Lenkradw_Geschw 511;
BA_ "GenSigSendType" SG_ 134 LWI_Lenkradwinkel 0;
BA_ "GenSigStartValue" SG_ 134 LWI_Lenkradwinkel 8190;
BA_ "Fehlerwert" SG_ 134 LWI_Lenkradwinkel 8191;
BA_ "GenSigSendType" SG_ 134 LWI_MFL_Abschaltung 0;
BA_ "GenSigSwitchedByIgnition" SG_ 134 LWI_MFL_Abschaltung 0;
BA_ "GenSigSendType" SG_ 134 LWI_QBit_Lenkradwinkel 0;
BA_ "GenSigStartValue" SG_ 134 LWI_QBit_Lenkradwinkel 1;
BA_ "GenSigSendType" SG_ 134 LWI_QBit_Sub_Daten 0;
BA_ "GenSigSendType" SG_ 134 LWI_Sensorstatus 0;
BA_ "GenSigSendType" SG_ 134 LWI_Sub_Daten 0;
BA_ "GenSigSendType" SG_ 134 LWI_VZ_Lenkradw_Geschw 0;
BA_ "GenSigSendType" SG_ 134 LWI_VZ_Lenkradwinkel 0;
BA_ "GenSigSendType" SG_ 917 AFS_Abbiegelicht_Dimm_Anf 0;
BA_ "GenSigSendType" SG_ 917 AFS_Abbiegelicht_li_Anf 0;
BA_ "GenSigSendType" SG_ 917 AFS_Abbiegelicht_re_Anf 0;
BA_ "GenSigSendType" SG_ 917 AFS_adaptive_LV_verbaut 0;
BA_ "GenSigSendType" SG_ 917 AFS_Allwetterlicht 0;
BA_ "GenSigSendType" SG_ 917 AFS_Charisma_FahrPr 0;
BA_ "GenSigSendType" SG_ 917 AFS_Charisma_Status 0;
BA_ "GenSigSendType" SG_ 917 AFS_Ersatzlicht_Links 0;
BA_ "GenSigSendType" SG_ 917 AFS_Ersatzlicht_Rechts 0;
BA_ "GenSigSendType" SG_ 917 AFS_Fehlertext 0;
BA_ "GenSigSendType" SG_ 917 AFS_Fernlicht_li_defekt 0;
BA_ "GenSigSendType" SG_ 917 AFS_Fernlicht_re_defekt 0;
BA_ "GenSigSendType" SG_ 917 AFS_Fernlicht_Status 3;
BA_ "GenSigSendType" SG_ 917 AFS_Lampe 0;
BA_ "GenSigSendType" SG_ 917 AFS_LED_Blinkmode 0;
BA_ "GenSigSendType" SG_ 917 AFS_Status_adaptive_LV 0;
BA_ "GenSigStartValue" SG_ 917 AFS_Status_adaptive_LV 1;
BA_ "GenSigSendType" SG_ 917 AFS_Verfuegbarkeit_GLW 0;
BA_ "GenSigStartValue" SG_ 917 AFS_Verfuegbarkeit_GLW 1;
BA_ "GenSigSendType" SG_ 917 GLW_Sensor_blockiert 0;
BA_ "GenSigSendType" SG_ 917 LWR_AFS_01_BZ 0;
BA_ "GenSigFuncType" SG_ 917 LWR_AFS_01_BZ 1;
BA_ "GenSigSendType" SG_ 917 LWR_AFS_Grundeinstellung 0;
BA_ "GenSigSendType" SG_ 917 LWR_AFS_Parametrisierung 0;
BA_ "GenSigSendType" SG_ 917 LWR_Hoehenwert_HL 0;
BA_ "GenSigStartValue" SG_ 917 LWR_Hoehenwert_HL 254;
BA_ "Fehlerwert" SG_ 917 LWR_Hoehenwert_HL 255;
BA_ "GenSigSendType" SG_ 917 LWR_Hoehenwert_VL 0;
BA_ "GenSigStartValue" SG_ 917 LWR_Hoehenwert_VL 254;
BA_ "Fehlerwert" SG_ 917 LWR_Hoehenwert_VL 255;
BA_ "GenSigSendType" SG_ 917 LWR_Initialisierungslauf 0;
BA_ "GenSigSendType" SG_ 917 LWR_Lampe 0;
BA_ "GenSigSendType" SG_ 917 LWR_Modus 0;
BA_ "GenSigSendType" SG_ 917 LWR_Pos_Schrittmotor 0;
BA_ "GenSigStartValue" SG_ 917 LWR_Pos_Schrittmotor 254;
BA_ "Fehlerwert" SG_ 917 LWR_Pos_Schrittmotor 255;
BA_ "GenSigSendType" SG_ 917 LWR_Reisemodus_Texte 0;
BA_ "GenSigSendType" SG_ 917 LWR_Sicherheitsposition 0;
BA_ "GenSigSendType" SG_ 917 LWR_Touristenmodus_aktiv 0;
BA_ "GenSigSendType" SG_ 917 LWR_Touristenmodus_verbaut 0;
BA_ "GenSigSendType" SG_ 1600 MO_Absperrventil_oeffnen 0;
BA_ "GenSigSwitchedByIgnition" SG_ 1600 MO_Absperrventil_oeffnen 0;
BA_ "GenSigSendType" SG_ 1600 MO_aktives_Getriebeheizen 0;
BA_ "GenSigSwitchedByIgnition" SG_ 1600 MO_aktives_Getriebeheizen 0;
BA_ "GenSigSendType" SG_ 1600 MO_Ansaugluft_Temp 0;
BA_ "GenSigStartValue" SG_ 1600 MO_Ansaugluft_Temp 254;
BA_ "GenSigSwitchedByIgnition" SG_ 1600 MO_Ansaugluft_Temp 0;
BA_ "Fehlerwert" SG_ 1600 MO_Ansaugluft_Temp 255;
BA_ "GenSigSendType" SG_ 1600 MO_Getriebe_kuehlen 0;
BA_ "GenSigSwitchedByIgnition" SG_ 1600 MO_Getriebe_kuehlen 0;
BA_ "GenSigSendType" SG_ 1600 MO_Heizungspumpenansteuerung 0;
BA_ "GenSigStartValue" SG_ 1600 MO_Heizungspumpenansteuerung 14;
BA_ "GenSigSwitchedByIgnition" SG_ 1600 MO_Heizungspumpenansteuerung 0;
BA_ "Fehlerwert" SG_ 1600 MO_Heizungspumpenansteuerung 13;
BA_ "GenSigSendType" SG_ 1600 MO_Hoeheninfo 0;
BA_ "GenSigSwitchedByIgnition" SG_ 1600 MO_Hoeheninfo 0;
BA_ "Fehlerwert" SG_ 1600 MO_Hoeheninfo 255;
BA_ "GenSigSendType" SG_ 1600 MO_HYB_Fehler_HV_Netz 0;
BA_ "GenSigSwitchedByIgnition" SG_ 1600 MO_HYB_Fehler_HV_Netz 0;
BA_ "GenSigSendType" SG_ 1600 MO_Kennfeldk 0;
BA_ "GenSigSwitchedByIgnition" SG_ 1600 MO_Kennfeldk 0;
BA_ "GenSigSendType" SG_ 1600 MO_KL15_Abschaltempfehlung 0;
BA_ "GenSigSwitchedByIgnition" SG_ 1600 MO_KL15_Abschaltempfehlung 0;
BA_ "GenSigSendType" SG_ 1600 MO_Kuehlmittel_Temp 0;
BA_ "GenSigStartValue" SG_ 1600 MO_Kuehlmittel_Temp 254;
BA_ "GenSigSwitchedByIgnition" SG_ 1600 MO_Kuehlmittel_Temp 0;
BA_ "Fehlerwert" SG_ 1600 MO_Kuehlmittel_Temp 255;
BA_ "GenSigSendType" SG_ 1600 MO_Mom_Traegheit_02 0;
BA_ "GenSigSwitchedByIgnition" SG_ 1600 MO_Mom_Traegheit_02 0;
BA_ "GenSigSendType" SG_ 1600 MO_Nachlaufzeit_Heizungspumpe 0;
BA_ "GenSigSwitchedByIgnition" SG_ 1600 MO_Nachlaufzeit_Heizungspumpe 0;
BA_ "GenSigSendType" SG_ 1600 MO_Oel_Temp 0;
BA_ "GenSigStartValue" SG_ 1600 MO_Oel_Temp 254;
BA_ "GenSigSwitchedByIgnition" SG_ 1600 MO_Oel_Temp 0;
BA_ "Fehlerwert" SG_ 1600 MO_Oel_Temp 255;
BA_ "GenSigSendType" SG_ 1600 MO_QBit_Ansaugluft_Temp 0;
BA_ "GenSigStartValue" SG_ 1600 MO_QBit_Ansaugluft_Temp 1;
BA_ "GenSigSwitchedByIgnition" SG_ 1600 MO_QBit_Ansaugluft_Temp 0;
BA_ "GenSigSendType" SG_ 1600 MO_QBit_Hoeheninfo 0;
BA_ "GenSigStartValue" SG_ 1600 MO_QBit_Hoeheninfo 1;
BA_ "GenSigSwitchedByIgnition" SG_ 1600 MO_QBit_Hoeheninfo 0;
BA_ "GenSigSendType" SG_ 1600 MO_QBit_Kuehlmittel_Temp 0;
BA_ "GenSigStartValue" SG_ 1600 MO_QBit_Kuehlmittel_Temp 1;
BA_ "GenSigSwitchedByIgnition" SG_ 1600 MO_QBit_Kuehlmittel_Temp 0;
BA_ "GenSigSendType" SG_ 1600 MO_QBit_Oel_Temp 0;
BA_ "GenSigStartValue" SG_ 1600 MO_QBit_Oel_Temp 1;
BA_ "GenSigSwitchedByIgnition" SG_ 1600 MO_QBit_Oel_Temp 0;
BA_ "GenSigSendType" SG_ 1600 MO_SpannungsAnf 0;
BA_ "GenSigSwitchedByIgnition" SG_ 1600 MO_SpannungsAnf 0;
BA_ "GenSigSendType" SG_ 1600 MO_Versionsinfo_02 0;
BA_ "GenSigSwitchedByIgnition" SG_ 1600 MO_Versionsinfo_02 0;
BA_ "GenSigSendType" SG_ 167 MO_erste_Ungenauschwelle 0;
BA_ "GenSigSwitchedByIgnition" SG_ 167 MO_erste_Ungenauschwelle 0;
BA_ "GenSigSendType" SG_ 167 MO_Mom_Ist_Summe 0;
BA_ "GenSigStartValue" SG_ 167 MO_Mom_Ist_Summe 1022;
BA_ "GenSigSwitchedByIgnition" SG_ 167 MO_Mom_Ist_Summe 0;
BA_ "GenSigSendType" SG_ 167 MO_Mom_Schub 0;
BA_ "GenSigStartValue" SG_ 167 MO_Mom_Schub 510;
BA_ "GenSigSwitchedByIgnition" SG_ 167 MO_Mom_Schub 0;
BA_ "GenSigSendType" SG_ 167 MO_Mom_Soll_gefiltert 0;
BA_ "GenSigStartValue" SG_ 167 MO_Mom_Soll_gefiltert 1022;
BA_ "GenSigSwitchedByIgnition" SG_ 167 MO_Mom_Soll_gefiltert 0;
BA_ "GenSigSendType" SG_ 167 MO_Mom_Soll_Roh 0;
BA_ "GenSigStartValue" SG_ 167 MO_Mom_Soll_Roh 1022;
BA_ "GenSigSwitchedByIgnition" SG_ 167 MO_Mom_Soll_Roh 0;
BA_ "GenSigSendType" SG_ 167 MO_Mom_Traegheit_Summe 0;
BA_ "GenSigStartValue" SG_ 167 MO_Mom_Traegheit_Summe 1022;
BA_ "GenSigSwitchedByIgnition" SG_ 167 MO_Mom_Traegheit_Summe 0;
BA_ "GenSigSendType" SG_ 167 MO_QBit_Motormomente 0;
BA_ "GenSigStartValue" SG_ 167 MO_QBit_Motormomente 1;
BA_ "GenSigSwitchedByIgnition" SG_ 167 MO_QBit_Motormomente 0;
BA_ "GenSigSendType" SG_ 167 MO_Status_Normalbetrieb_01 0;
BA_ "GenSigSwitchedByIgnition" SG_ 167 MO_Status_Normalbetrieb_01 0;
BA_ "GenSigSendType" SG_ 167 Motor_11_BZ 0;
BA_ "GenSigFuncType" SG_ 167 Motor_11_BZ 1;
BA_ "GenSigSwitchedByIgnition" SG_ 167 Motor_11_BZ 0;
BA_ "GenSigSendType" SG_ 167 Motor_11_CRC 0;
BA_ "GenSigFuncType" SG_ 167 Motor_11_CRC 2;
BA_ "GenSigSwitchedByIgnition" SG_ 167 Motor_11_CRC 0;
BA_ "GenSigSendType" SG_ 168 MO_Drehzahl_01 0;
BA_ "GenSigSwitchedByIgnition" SG_ 168 MO_Drehzahl_01 0;
BA_ "GenSigSendType" SG_ 168 MO_Mom_Begr_Fahr 0;
BA_ "GenSigStartValue" SG_ 168 MO_Mom_Begr_Fahr 510;
BA_ "GenSigSwitchedByIgnition" SG_ 168 MO_Mom_Begr_Fahr 0;
BA_ "Fehlerwert" SG_ 168 MO_Mom_Begr_Fahr 511;
BA_ "GenSigSendType" SG_ 168 MO_Mom_Begr_Schalt 0;
BA_ "GenSigStartValue" SG_ 168 MO_Mom_Begr_Schalt 1022;
BA_ "GenSigSwitchedByIgnition" SG_ 168 MO_Mom_Begr_Schalt 0;
BA_ "GenSigSendType" SG_ 168 MO_Mom_neg_verfuegbar 0;
BA_ "GenSigStartValue" SG_ 168 MO_Mom_neg_verfuegbar 510;
BA_ "GenSigSwitchedByIgnition" SG_ 168 MO_Mom_neg_verfuegbar 0;
BA_ "Fehlerwert" SG_ 168 MO_Mom_neg_verfuegbar 511;
BA_ "GenSigSendType" SG_ 168 MO_Momentenintegral_02 0;
BA_ "GenSigSwitchedByIgnition" SG_ 168 MO_Momentenintegral_02 0;
BA_ "GenSigSendType" SG_ 168 MO_QBit_Drehzahl_01 0;
BA_ "GenSigStartValue" SG_ 168 MO_QBit_Drehzahl_01 1;
BA_ "GenSigSwitchedByIgnition" SG_ 168 MO_QBit_Drehzahl_01 0;
BA_ "GenSigSendType" SG_ 168 Motor_12_BZ 0;
BA_ "GenSigFuncType" SG_ 168 Motor_12_BZ 1;
BA_ "GenSigSwitchedByIgnition" SG_ 168 Motor_12_BZ 0;
BA_ "GenSigSendType" SG_ 168 Motor_12_CRC 0;
BA_ "GenSigFuncType" SG_ 168 Motor_12_CRC 2;
BA_ "GenSigSwitchedByIgnition" SG_ 168 Motor_12_CRC 0;
BA_ "GenSigSendType" SG_ 958 MO_Aussp_Anlass 3;
BA_ "GenSigSwitchedByIgnition" SG_ 958 MO_Aussp_Anlass 0;
BA_ "GenSigSendType" SG_ 958 MO_BKV_Unterdruckwarnung 0;
BA_ "GenSigSwitchedByIgnition" SG_ 958 MO_BKV_Unterdruckwarnung 0;
BA_ "GenSigSendType" SG_ 958 MO_BLS 3;
BA_ "GenSigSwitchedByIgnition" SG_ 958 MO_BLS 0;
BA_ "GenSigSendType" SG_ 958 MO_BMS_NV_Anf_stuetzen 3;
BA_ "GenSigSwitchedByIgnition" SG_ 958 MO_BMS_NV_Anf_stuetzen 0;
BA_ "GenSigSendType" SG_ 958 MO_EKlKomLeiRed 0;
BA_ "GenSigSwitchedByIgnition" SG_ 958 MO_EKlKomLeiRed 0;
BA_ "GenSigSendType" SG_ 958 MO_Ext_E_Fahrt_aktiv 3;
BA_ "NWM-WakeupAllowed" SG_ 958 MO_Ext_E_Fahrt_aktiv 1;
BA_ "GenSigSwitchedByIgnition" SG_ 958 MO_Ext_E_Fahrt_aktiv 0;
BA_ "GenSigSendType" SG_ 958 MO_Fahrer_bremst 3;
BA_ "GenSigSwitchedByIgnition" SG_ 958 MO_Fahrer_bremst 0;
BA_ "GenSigSendType" SG_ 958 MO_FMAus_aktiv 3;
BA_ "GenSigSwitchedByIgnition" SG_ 958 MO_FMAus_aktiv 0;
BA_ "GenSigSendType" SG_ 958 MO_FMAus_Startvariante 3;
BA_ "GenSigSwitchedByIgnition" SG_ 958 MO_FMAus_Startvariante 0;
BA_ "GenSigSendType" SG_ 958 MO_Freig_Anlass 3;
BA_ "GenSigSwitchedByIgnition" SG_ 958 MO_Freig_Anlass 0;
BA_ "GenSigSendType" SG_ 958 MO_Freig_Reku 0;
BA_ "GenSigSwitchedByIgnition" SG_ 958 MO_Freig_Reku 0;
BA_ "GenSigSendType" SG_ 958 MO_Freigabe_Segeln 0;
BA_ "GenSigSwitchedByIgnition" SG_ 958 MO_Freigabe_Segeln 0;
BA_ "GenSigSendType" SG_ 958 MO_Gangposition 3;
BA_ "GenSigStartValue" SG_ 958 MO_Gangposition 14;
BA_ "GenSigSwitchedByIgnition" SG_ 958 MO_Gangposition 0;
BA_ "Fehlerwert" SG_ 958 MO_Gangposition 15;
BA_ "GenSigSendType" SG_ 958 MO_Handshake_STH 0;
BA_ "GenSigSwitchedByIgnition" SG_ 958 MO_Handshake_STH 0;
BA_ "GenSigSendType" SG_ 958 MO_HYB_Fahrbereitschaft 0;
BA_ "GenSigSwitchedByIgnition" SG_ 958 MO_HYB_Fahrbereitschaft 0;
BA_ "GenSigSendType" SG_ 958 MO_HYB_VM_aktiv 3;
BA_ "GenSigSwitchedByIgnition" SG_ 958 MO_HYB_VM_aktiv 0;
BA_ "GenSigSendType" SG_ 958 MO_Interlock 3;
BA_ "GenSigSwitchedByIgnition" SG_ 958 MO_Interlock 0;
BA_ "GenSigSendType" SG_ 958 MO_Kickdown 3;
BA_ "GenSigSwitchedByIgnition" SG_ 958 MO_Kickdown 0;
BA_ "GenSigSendType" SG_ 958 MO_Kl_50 3;
BA_ "GenSigSwitchedByIgnition" SG_ 958 MO_Kl_50 0;
BA_ "GenSigSendType" SG_ 958 MO_Kl_75 3;
BA_ "GenSigSwitchedByIgnition" SG_ 958 MO_Kl_75 0;
BA_ "GenSigSendType" SG_ 958 MO_Klima_Eingr 0;
BA_ "GenSigSwitchedByIgnition" SG_ 958 MO_Klima_Eingr 0;
BA_ "GenSigSendType" SG_ 958 MO_Konsistenz_Bremsped 3;
BA_ "GenSigSwitchedByIgnition" SG_ 958 MO_Konsistenz_Bremsped 0;
BA_ "GenSigSendType" SG_ 958 MO_Kuppl_schalter 3;
BA_ "GenSigSwitchedByIgnition" SG_ 958 MO_Kuppl_schalter 0;
BA_ "GenSigSendType" SG_ 958 MO_Motor_laeuft 3;
BA_ "GenSigSwitchedByIgnition" SG_ 958 MO_Motor_laeuft 0;
BA_ "GenSigSendType" SG_ 958 MO_PTC_Status 0;
BA_ "GenSigSwitchedByIgnition" SG_ 958 MO_PTC_Status 0;
BA_ "GenSigSendType" SG_ 958 MO_QBit_Fahrer_bremst 3;
BA_ "GenSigStartValue" SG_ 958 MO_QBit_Fahrer_bremst 1;
BA_ "GenSigSwitchedByIgnition" SG_ 958 MO_QBit_Fahrer_bremst 0;
BA_ "GenSigSendType" SG_ 958 MO_QBit_Gangposition 3;
BA_ "GenSigStartValue" SG_ 958 MO_QBit_Gangposition 1;
BA_ "GenSigSwitchedByIgnition" SG_ 958 MO_QBit_Gangposition 0;
BA_ "GenSigSendType" SG_ 958 MO_QBit_KL_75 3;
BA_ "GenSigStartValue" SG_ 958 MO_QBit_KL_75 1;
BA_ "GenSigSwitchedByIgnition" SG_ 958 MO_QBit_KL_75 0;
BA_ "GenSigSendType" SG_ 958 MO_Remotestart_Betrieb 3;
BA_ "GenSigSwitchedByIgnition" SG_ 958 MO_Remotestart_Betrieb 0;
BA_ "GenSigSendType" SG_ 958 MO_Remotestart_moeglich 0;
BA_ "GenSigSwitchedByIgnition" SG_ 958 MO_Remotestart_moeglich 0;
BA_ "GenSigSendType" SG_ 958 MO_Signalquelle_Gangposition 0;
BA_ "GenSigSwitchedByIgnition" SG_ 958 MO_Signalquelle_Gangposition 0;
BA_ "GenSigSendType" SG_ 958 MO_StartStopp_Fahrerwunsch 0;
BA_ "GenSigSwitchedByIgnition" SG_ 958 MO_StartStopp_Fahrerwunsch 0;
BA_ "GenSigSendType" SG_ 958 MO_StartStopp_Motorstopp 3;
BA_ "GenSigSwitchedByIgnition" SG_ 958 MO_StartStopp_Motorstopp 0;
BA_ "GenSigSendType" SG_ 958 MO_StartStopp_Status 0;
BA_ "GenSigSwitchedByIgnition" SG_ 958 MO_StartStopp_Status 0;
BA_ "GenSigSendType" SG_ 958 MO_StartStopp_Wiederstart 3;
BA_ "GenSigSwitchedByIgnition" SG_ 958 MO_StartStopp_Wiederstart 0;
BA_ "GenSigSendType" SG_ 958 MO_StartVorauss_erfuellt 3;
BA_ "GenSigStartValue" SG_ 958 MO_StartVorauss_erfuellt 1;
BA_ "GenSigSwitchedByIgnition" SG_ 958 MO_StartVorauss_erfuellt 0;
BA_ "GenSigSendType" SG_ 958 MO_Timeout_ESP 3;
BA_ "GenSigSwitchedByIgnition" SG_ 958 MO_Timeout_ESP 0;
BA_ "GenSigSendType" SG_ 958 MO_Zylinderabschaltung 3;
BA_ "GenSigSwitchedByIgnition" SG_ 958 MO_Zylinderabschaltung 0;
BA_ "GenSigSendType" SG_ 958 Motor_14_BZ 0;
BA_ "GenSigFuncType" SG_ 958 Motor_14_BZ 1;
BA_ "GenSigSwitchedByIgnition" SG_ 958 Motor_14_BZ 0;
BA_ "GenSigSendType" SG_ 958 Motor_14_CRC 0;
BA_ "GenSigFuncType" SG_ 958 Motor_14_CRC 2;
BA_ "GenSigSwitchedByIgnition" SG_ 958 Motor_14_CRC 0;
BA_ "GenSigSendType" SG_ 1631 MO_DPF_reg 0;
BA_ "GenSigSwitchedByIgnition" SG_ 1631 MO_DPF_reg 0;
BA_ "GenSigSendType" SG_ 1631 MO_Energieinhalt_BMS 0;
BA_ "GenSigStartValue" SG_ 1631 MO_Energieinhalt_BMS 4094;
BA_ "GenSigSwitchedByIgnition" SG_ 1631 MO_Energieinhalt_BMS 0;
BA_ "Fehlerwert" SG_ 1631 MO_Energieinhalt_BMS 4095;
BA_ "GenSigSendType" SG_ 1631 MO_Heizstrom_EKAT 0;
BA_ "GenSigSwitchedByIgnition" SG_ 1631 MO_Heizstrom_EKAT 0;
BA_ "Fehlerwert" SG_ 1631 MO_Heizstrom_EKAT 127;
BA_ "GenSigSendType" SG_ 1631 MO_Heizstrom_SCR 0;
BA_ "GenSigSwitchedByIgnition" SG_ 1631 MO_Heizstrom_SCR 0;
BA_ "Fehlerwert" SG_ 1631 MO_Heizstrom_SCR 63;
BA_ "GenSigSendType" SG_ 1631 MO_SpannungsAnf_02 0;
BA_ "GenSigSwitchedByIgnition" SG_ 1631 MO_SpannungsAnf_02 0;
BA_ "GenSigSendType" SG_ 1631 MO_Testmode_AG 0;
BA_ "GenSigSwitchedByIgnition" SG_ 1631 MO_Testmode_AG 0;
BA_ "GenSigSendType" SG_ 1631 TSK_Fahrzeugmasse_02 0;
BA_ "GenSigSwitchedByIgnition" SG_ 1631 TSK_Fahrzeugmasse_02 0;
BA_ "Fehlerwert" SG_ 1631 TSK_Fahrzeugmasse_02 255;
BA_ "GenSigSendType" SG_ 1631 TSK_Getriebeinfo 0;
BA_ "GenSigSwitchedByIgnition" SG_ 1631 TSK_Getriebeinfo 0;
BA_ "GenSigSendType" SG_ 1631 TSK_Grundmasse 0;
BA_ "GenSigSwitchedByIgnition" SG_ 1631 TSK_Grundmasse 0;
BA_ "GenSigSendType" SG_ 1631 TSK_QBit_Fahrzeugmasse 0;
BA_ "GenSigStartValue" SG_ 1631 TSK_QBit_Fahrzeugmasse 1;
BA_ "GenSigSwitchedByIgnition" SG_ 1631 TSK_QBit_Fahrzeugmasse 0;
BA_ "GenSigSendType" SG_ 1631 TSK_QBit_Steigung 0;
BA_ "GenSigStartValue" SG_ 1631 TSK_QBit_Steigung 1;
BA_ "GenSigSwitchedByIgnition" SG_ 1631 TSK_QBit_Steigung 0;
BA_ "GenSigSendType" SG_ 1631 TSK_Steigung_02 0;
BA_ "GenSigSwitchedByIgnition" SG_ 1631 TSK_Steigung_02 0;
BA_ "Fehlerwert" SG_ 1631 TSK_Steigung_02 255;
BA_ "GenSigSendType" SG_ 1648 MO1_Freigabe_Info_WFS 3;
BA_ "GenSigSwitchedByIgnition" SG_ 1648 MO1_Freigabe_Info_WFS 0;
BA_ "GenSigSendType" SG_ 1648 MO1_Freigabe_Verfallsinfo_WFS 3;
BA_ "GenSigSwitchedByIgnition" SG_ 1648 MO1_Freigabe_Verfallsinfo_WFS 0;
BA_ "GenSigSendType" SG_ 1648 MO1_Sperr_Info_WFS 3;
BA_ "GenSigSwitchedByIgnition" SG_ 1648 MO1_Sperr_Info_WFS 0;
BA_ "GenSigSendType" SG_ 1648 MO_Abstellzeit 0;
BA_ "GenSigSwitchedByIgnition" SG_ 1648 MO_Abstellzeit 0;
BA_ "GenSigSendType" SG_ 1648 MO_Abstellzeit_Status 0;
BA_ "GenSigSwitchedByIgnition" SG_ 1648 MO_Abstellzeit_Status 0;
BA_ "GenSigSendType" SG_ 1648 MO_ANC_Kennfeld_Anf 3;
BA_ "GenSigSwitchedByIgnition" SG_ 1648 MO_ANC_Kennfeld_Anf 0;
BA_ "GenSigSendType" SG_ 1648 MO_Anzahl_Abgesch_Zyl 3;
BA_ "GenSigSwitchedByIgnition" SG_ 1648 MO_Anzahl_Abgesch_Zyl 0;
BA_ "GenSigSendType" SG_ 1648 MO_Bremslicht_Reku 3;
BA_ "GenSigSwitchedByIgnition" SG_ 1648 MO_Bremslicht_Reku 0;
BA_ "GenSigSendType" SG_ 1648 MO_Drehzahl_Warnung 0;
BA_ "GenSigSwitchedByIgnition" SG_ 1648 MO_Drehzahl_Warnung 0;
BA_ "GenSigSendType" SG_ 1648 MO_EPCL 3;
BA_ "GenSigSwitchedByIgnition" SG_ 1648 MO_EPCL 0;
BA_ "GenSigSendType" SG_ 1648 MO_Ethanol_BS_Texte 0;
BA_ "GenSigSwitchedByIgnition" SG_ 1648 MO_Ethanol_BS_Texte 0;
BA_ "GenSigSendType" SG_ 1648 MO_Fahrzeugtyp 0;
BA_ "GenSigFuncType" SG_ 1648 MO_Fahrzeugtyp 8;
BA_ "GenSigSwitchedByIgnition" SG_ 1648 MO_Fahrzeugtyp 0;
BA_ "GenSigSendType" SG_ 1648 MO_Fehler_Zylabsch 0;
BA_ "GenSigSwitchedByIgnition" SG_ 1648 MO_Fehler_Zylabsch 0;
BA_ "GenSigSendType" SG_ 1648 MO_Hybrid_StartStopp_LED 3;
BA_ "GenSigSwitchedByIgnition" SG_ 1648 MO_Hybrid_StartStopp_LED 0;
BA_ "GenSigSendType" SG_ 1648 MO_max_Ladedruck 0;
BA_ "GenSigFuncType" SG_ 1648 MO_max_Ladedruck 8;
BA_ "GenSigSwitchedByIgnition" SG_ 1648 MO_max_Ladedruck 0;
BA_ "GenSigSendType" SG_ 1648 MO_NMAX_Schaltanzeige 3;
BA_ "GenSigSwitchedByIgnition" SG_ 1648 MO_NMAX_Schaltanzeige 0;
BA_ "GenSigSendType" SG_ 1648 MO_obere_Drehzahlgrenze 0;
BA_ "GenSigSwitchedByIgnition" SG_ 1648 MO_obere_Drehzahlgrenze 0;
BA_ "GenSigSendType" SG_ 1648 MO_StartStopp_PopUp 3;
BA_ "GenSigSwitchedByIgnition" SG_ 1648 MO_StartStopp_PopUp 0;
BA_ "GenSigSendType" SG_ 1648 MO_Zylabsch_Texte 0;
BA_ "GenSigSwitchedByIgnition" SG_ 1648 MO_Zylabsch_Texte 0;
BA_ "GenSigSendType" SG_ 1648 MO_Zylabsch_Texte_02 3;
BA_ "GenSigSwitchedByIgnition" SG_ 1648 MO_Zylabsch_Texte_02 0;
BA_ "GenSigSendType" SG_ 289 MO_Entkopplung_Sollschlupf 0;
BA_ "GenSigStartValue" SG_ 289 MO_Entkopplung_Sollschlupf 126;
BA_ "GenSigSwitchedByIgnition" SG_ 289 MO_Entkopplung_Sollschlupf 0;
BA_ "GenSigSendType" SG_ 289 MO_Fahrpedalgradient 0;
BA_ "GenSigSwitchedByIgnition" SG_ 289 MO_Fahrpedalgradient 0;
BA_ "Fehlerwert" SG_ 289 MO_Fahrpedalgradient 255;
BA_ "GenSigSendType" SG_ 289 MO_Fahrpedalrohwert_01 0;
BA_ "GenSigSwitchedByIgnition" SG_ 289 MO_Fahrpedalrohwert_01 0;
BA_ "Fehlerwert" SG_ 289 MO_Fahrpedalrohwert_01 255;
BA_ "GenSigSendType" SG_ 289 MO_Moment_im_Leerlauf 0;
BA_ "GenSigSwitchedByIgnition" SG_ 289 MO_Moment_im_Leerlauf 0;
BA_ "GenSigSendType" SG_ 289 MO_QBit_Fahrpedalwerte_01 0;
BA_ "GenSigStartValue" SG_ 289 MO_QBit_Fahrpedalwerte_01 1;
BA_ "GenSigSwitchedByIgnition" SG_ 289 MO_QBit_Fahrpedalwerte_01 0;
BA_ "GenSigSendType" SG_ 289 MO_rel_Saugrohrdruck 0;
BA_ "GenSigSwitchedByIgnition" SG_ 289 MO_rel_Saugrohrdruck 0;
BA_ "Fehlerwert" SG_ 289 MO_rel_Saugrohrdruck 63;
BA_ "GenSigSendType" SG_ 289 MO_rel_Saugrohrdruck_gem_err 0;
BA_ "GenSigSwitchedByIgnition" SG_ 289 MO_rel_Saugrohrdruck_gem_err 0;
BA_ "GenSigSendType" SG_ 289 MO_Schubabschaltung 0;
BA_ "GenSigSwitchedByIgnition" SG_ 289 MO_Schubabschaltung 0;
BA_ "GenSigSendType" SG_ 289 MO_Sig_Fahrpedalgradient 0;
BA_ "GenSigSwitchedByIgnition" SG_ 289 MO_Sig_Fahrpedalgradient 0;
BA_ "GenSigSendType" SG_ 289 MO_Solldrehz_Leerlauf 0;
BA_ "GenSigSwitchedByIgnition" SG_ 289 MO_Solldrehz_Leerlauf 0;
BA_ "GenSigSendType" SG_ 289 MO_StartStopp_StoppVorbereitung 0;
BA_ "GenSigSwitchedByIgnition" SG_ 289 MO_StartStopp_StoppVorbereitung 0;
BA_ "GenSigSendType" SG_ 289 MO_temporaere_Fahrerabwesenheit 0;
BA_ "GenSigSwitchedByIgnition" SG_ 289 MO_temporaere_Fahrerabwesenheit 0;
BA_ "GenSigSendType" SG_ 289 Motor_20_BZ 0;
BA_ "GenSigFuncType" SG_ 289 Motor_20_BZ 1;
BA_ "GenSigSwitchedByIgnition" SG_ 289 Motor_20_BZ 0;
BA_ "GenSigSendType" SG_ 289 Motor_20_CRC 0;
BA_ "GenSigFuncType" SG_ 289 Motor_20_CRC 2;
BA_ "GenSigSwitchedByIgnition" SG_ 289 Motor_20_CRC 0;
BA_ "GenSigSendType" SG_ 289 TSK_a_Soll_gradientenbegrenzt 0;
BA_ "GenSigStartValue" SG_ 289 TSK_a_Soll_gradientenbegrenzt 127;
BA_ "GenSigSwitchedByIgnition" SG_ 289 TSK_a_Soll_gradientenbegrenzt 0;
BA_ "GenSigSendType" SG_ 283 MO_EBoost_verf_praed 0;
BA_ "GenSigSwitchedByIgnition" SG_ 283 MO_EBoost_verf_praed 0;
BA_ "GenSigSendType" SG_ 283 MO_eLaunch_verf 0;
BA_ "GenSigSwitchedByIgnition" SG_ 283 MO_eLaunch_verf 0;
BA_ "GenSigSendType" SG_ 283 MO_EnergyAssist_Aktivierbar 3;
BA_ "GenSigSwitchedByIgnition" SG_ 283 MO_EnergyAssist_Aktivierbar 0;
BA_ "GenSigSendType" SG_ 283 MO_Fahrbereitschaft 3;
BA_ "GenSigSwitchedByIgnition" SG_ 283 MO_Fahrbereitschaft 0;
BA_ "GenSigSendType" SG_ 283 MO_Freilauf_Info 3;
BA_ "GenSigSwitchedByIgnition" SG_ 283 MO_Freilauf_Info 0;
BA_ "GenSigSendType" SG_ 283 MO_Freilauf_Status 3;
BA_ "GenSigSwitchedByIgnition" SG_ 283 MO_Freilauf_Status 0;
BA_ "Fehlerwert" SG_ 283 MO_Freilauf_Status 7;
BA_ "GenSigSendType" SG_ 283 MO_Heckspoiler_Anf 0;
BA_ "GenSigSwitchedByIgnition" SG_ 283 MO_Heckspoiler_Anf 0;
BA_ "GenSigSendType" SG_ 283 MO_Krit_Heckobjekt 0;
BA_ "GenSigSwitchedByIgnition" SG_ 283 MO_Krit_Heckobjekt 0;
BA_ "Fehlerwert" SG_ 283 MO_Krit_Heckobjekt 7;
BA_ "GenSigSendType" SG_ 283 MO_NGS_Gangpos 3;
BA_ "GenSigSwitchedByIgnition" SG_ 283 MO_NGS_Gangpos 0;
BA_ "Fehlerwert" SG_ 283 MO_NGS_Gangpos 7;
BA_REL_ "GenSigTimeoutTime" BU_SG_REL_ Allrad_Haldex SG_ 779 KBI_Handbremse 500;
BA_REL_ "GenSigTimeoutTime" BU_SG_REL_ Allrad_Haldex SG_ 1719 KBI_Standzeit_02 5000;
BA_REL_ "GenSigTimeoutTime" BU_SG_REL_ Allrad_Haldex SG_ 134 LWI_01_BZ 500;
BA_REL_ "GenSigTimeoutTime" BU_SG_REL_ Allrad_Haldex SG_ 134 LWI_Sensorstatus 500;
BA_REL_ "GenSigTimeoutTime" BU_SG_REL_ Allrad_Haldex SG_ 134 LWI_QBit_Lenkradwinkel 500;
BA_REL_ "GenSigTimeoutTime" BU_SG_REL_ Allrad_Haldex SG_ 134 LWI_Lenkradwinkel 500;
BA_REL_ "GenSigTimeoutTime" BU_SG_REL_ Allrad_Haldex SG_ 134 LWI_VZ_Lenkradwinkel 500;
BA_REL_ "GenSigTimeoutTime" BU_SG_REL_ Allrad_Haldex SG_ 167 MO_Mom_Soll_Roh 500;
BA_REL_ "GenSigTimeoutTime" BU_SG_REL_ Allrad_Haldex SG_ 167 MO_Mom_Ist_Summe 500;
BA_REL_ "GenSigTimeoutTime" BU_SG_REL_ Allrad_Haldex SG_ 167 MO_Mom_Schub 500;
BA_REL_ "GenSigTimeoutTime" BU_SG_REL_ Allrad_Haldex SG_ 167 MO_Status_Normalbetrieb_01 500;
BA_REL_ "GenSigTimeoutTime" BU_SG_REL_ Allrad_Haldex SG_ 168 MO_Drehzahl_01 500;
BA_REL_ "GenSigTimeoutTime" BU_SG_REL_ Allrad_Haldex SG_ 958 MO_Gangposition 1000;
BA_REL_ "GenSigTimeoutTime" BU_SG_REL_ Allrad_Haldex SG_ 958 MO_Fahrer_bremst 1000;
BA_REL_ "GenSigTimeoutTime" BU_SG_REL_ Allrad_Haldex SG_ 958 MO_QBit_Fahrer_bremst 1000;
BA_REL_ "GenSigTimeoutTime" BU_SG_REL_ Allrad_Haldex SG_ 958 MO_Kuppl_schalter 1000;
BA_REL_ "GenSigTimeoutTime" BU_SG_REL_ Allrad_Haldex SG_ 289 MO_Fahrpedalrohwert_01 500;
BA_REL_ "GenSigTimeoutTime" BU_SG_REL_ Allrad_Haldex SG_ 289 MO_QBit_Fahrpedalwerte_01 500;
BA_REL_ "GenSigTimeoutTime" BU_SG_REL_ AreaView_MQB SG_ 159 EPS_Lenkmoment 500;
BA_REL_ "GenSigTimeoutTime" BU_SG_REL_ AreaView_MQB SG_ 159 EPS_Lenkmoment_QBit 500;
BA_REL_ "GenSigTimeoutTime" BU_SG_REL_ AreaView_MQB SG_ 159 EPS_VZ_Lenkmoment 500;
BA_REL_ "GenSigTimeoutTime" BU_SG_REL_ AreaView_MQB SG_ 134 LWI_QBit_Lenkradwinkel 500;
BA_REL_ "GenSigTimeoutTime" BU_SG_REL_ AreaView_MQB SG_ 134 LWI_Lenkradwinkel 500;
BA_REL_ "GenSigTimeoutTime" BU_SG_REL_ AreaView_MQB SG_ 134 LWI_VZ_Lenkradwinkel 500;
BA_REL_ "GenSigTimeoutTime" BU_SG_REL_ Bremse_ABS_MK100 SG_ 779 KBI_ABS_Lampe 500;
BA_REL_ "GenSigTimeoutTime" BU_SG_REL_ Bremse_ABS_MK100 SG_ 779 KBI_ESP_Lampe 500;
BA_REL_ "GenSigTimeoutTime" BU_SG_REL_ Bremse_ABS_MK100 SG_ 779 KBI_BKL_Lampe 500;
BA_REL_ "GenSigTimeoutTime" BU_SG_REL_ Bremse_ABS_MK100 SG_ 779 KBI_SILA_gueltig 500;
BA_REL_ "GenSigTimeoutTime" BU_SG_REL_ Bremse_ABS_MK100 SG_ 779 KBI_Handbremse 500;
BA_REL_ "GenSigTimeoutTime" BU_SG_REL_ Bremse_ABS_MK100 SG_ 1719 KBI_QBit_Aussen_Temp_gef 5000;
BA_REL_ "GenSigTimeoutTime" BU_SG_REL_ Bremse_ABS_MK100 SG_ 1719 KBI_Aussen_Temp_gef 5000;
BA_REL_ "GenSigTimeoutTime" BU_SG_REL_ Bremse_ABS_MK100 SG_ 1720 KBI_Reifenumfang 5000;
BA_REL_ "GenSigTimeoutTime" BU_SG_REL_ Bremse_ABS_MK100 SG_ 159 EPS_03_CRC 500;
BA_REL_ "GenSigTimeoutTime" BU_SG_REL_ Bremse_ABS_MK100 SG_ 159 EPS_03_BZ 500;
BA_REL_ "GenSigTimeoutTime" BU_SG_REL_ Bremse_ABS_MK100 SG_ 159 EPS_DSR_Status 500;
BA_REL_ "GenSigTimeoutTime" BU_SG_REL_ Bremse_ABS_MK100 SG_ 159 EPS_Lenkmoment 500;
BA_REL_ "GenSigTimeoutTime" BU_SG_REL_ Bremse_ABS_MK100 SG_ 159 EPS_Lenkmoment_QBit 500;
BA_REL_ "GenSigTimeoutTime" BU_SG_REL_ Bremse_ABS_MK100 SG_ 159 EPS_VZ_Lenkmoment 500;
BA_REL_ "GenSigTimeoutTime" BU_SG_REL_ Bremse_ABS_MK100 SG_ 159 EPS_Lenkungstyp 500;
BA_REL_ "GenSigTimeoutTime" BU_SG_REL_ Bremse_ABS_MK100 SG_ 134 LWI_01_CRC 500;
BA_REL_ "GenSigTimeoutTime" BU_SG_REL_ Bremse_ABS_MK100 SG_ 134 LWI_01_BZ 500;
BA_REL_ "GenSigTimeoutTime" BU_SG_REL_ Bremse_ABS_MK100 SG_ 134 LWI_Sensorstatus 500;
BA_REL_ "GenSigTimeoutTime" BU_SG_REL_ Bremse_ABS_MK100 SG_ 134 LWI_QBit_Lenkradwinkel 500;
BA_REL_ "GenSigTimeoutTime" BU_SG_REL_ Bremse_ABS_MK100 SG_ 134 LWI_Lenkradwinkel 500;
BA_REL_ "GenSigTimeoutTime" BU_SG_REL_ Bremse_ABS_MK100 SG_ 134 LWI_VZ_Lenkradwinkel 500;
BA_REL_ "GenSigTimeoutTime" BU_SG_REL_ Bremse_ABS_MK100 SG_ 134 LWI_VZ_Lenkradw_Geschw 500;
BA_REL_ "GenSigTimeoutTime" BU_SG_REL_ Bremse_ABS_MK100 SG_ 134 LWI_Lenkradw_Geschw 500;
BA_REL_ "GenSigTimeoutTime" BU_SG_REL_ Bremse_ABS_MK100 SG_ 1600 MO_Hoeheninfo 5000;
BA_REL_ "GenSigTimeoutTime" BU_SG_REL_ Bremse_ABS_MK100 SG_ 167 Motor_11_CRC 500;
BA_REL_ "GenSigTimeoutTime" BU_SG_REL_ Bremse_ABS_MK100 SG_ 167 Motor_11_BZ 500;
BA_REL_ "GenSigTimeoutTime" BU_SG_REL_ Bremse_ABS_MK100 SG_ 167 MO_Mom_Soll_Roh 500;
BA_REL_ "GenSigTimeoutTime" BU_SG_REL_ Bremse_ABS_MK100 SG_ 167 MO_Mom_Ist_Summe 500;
BA_REL_ "GenSigTimeoutTime" BU_SG_REL_ Bremse_ABS_MK100 SG_ 167 MO_Mom_Traegheit_Summe 500;
BA_REL_ "GenSigTimeoutTime" BU_SG_REL_ Bremse_ABS_MK100 SG_ 167 MO_Mom_Schub 500;
BA_REL_ "GenSigTimeoutTime" BU_SG_REL_ Bremse_ABS_MK100 SG_ 167 MO_QBit_Motormomente 500;
BA_REL_ "GenSigTimeoutTime" BU_SG_REL_ Bremse_ABS_MK100 SG_ 168 Motor_12_CRC 500;
BA_REL_ "GenSigTimeoutTime" BU_SG_REL_ Bremse_ABS_MK100 SG_ 168 Motor_12_BZ 500;
BA_REL_ "GenSigTimeoutTime" BU_SG_REL_ Bremse_ABS_MK100 SG_ 168 MO_QBit_Drehzahl_01 500;
BA_REL_ "GenSigTimeoutTime" BU_SG_REL_ Bremse_ABS_MK100 SG_ 168 MO_Drehzahl_01 500;
BA_REL_ "GenSigTimeoutTime" BU_SG_REL_ Bremse_ABS_MK100 SG_ 958 MO_BLS 1000;
BA_REL_ "GenSigTimeoutTime" BU_SG_REL_ Bremse_ABS_MK100 SG_ 958 MO_Timeout_ESP 1000;
BA_REL_ "GenSigTimeoutTime" BU_SG_REL_ Bremse_ABS_MK100 SG_ 958 MO_Kuppl_schalter 1000;
BA_REL_ "GenSigTimeoutTime" BU_SG_REL_ Bremse_ABS_MK100 SG_ 958 MO_Motor_laeuft 1000;
BA_REL_ "GenSigTimeoutTime" BU_SG_REL_ Bremse_ABS_MK100 SG_ 289 Motor_20_CRC 500;
BA_REL_ "GenSigTimeoutTime" BU_SG_REL_ Bremse_ABS_MK100 SG_ 289 Motor_20_BZ 500;
BA_REL_ "GenSigTimeoutTime" BU_SG_REL_ Bremse_ABS_MK100 SG_ 289 MO_Fahrpedalrohwert_01 500;
BA_REL_ "GenSigTimeoutTime" BU_SG_REL_ Bremse_ABS_MK100 SG_ 289 MO_QBit_Fahrpedalwerte_01 500;
BA_REL_ "GenSigTimeoutTime" BU_SG_REL_ Bremse_ABS_MK100 SG_ 289 MO_Moment_im_Leerlauf 500;
BA_REL_ "GenSigTimeoutTime" BU_SG_REL_ Bremse_ESP_EPB_EBC460Vi SG_ 779 KBI_ABS_Lampe 500;
BA_REL_ "GenSigTimeoutTime" BU_SG_REL_ Bremse_ESP_EPB_EBC460Vi SG_ 779 KBI_ESP_Lampe 500;
BA_REL_ "GenSigTimeoutTime" BU_SG_REL_ Bremse_ESP_EPB_EBC460Vi SG_ 779 KBI_BKL_Lampe 500;
BA_REL_ "GenSigTimeoutTime" BU_SG_REL_ Bremse_ESP_EPB_EBC460Vi SG_ 779 KBI_SILA_gueltig 500;
BA_REL_ "GenSigTimeoutTime" BU_SG_REL_ Bremse_ESP_EPB_EBC460Vi SG_ 779 KBI_Handbremse 500;
BA_REL_ "GenSigTimeoutTime" BU_SG_REL_ Bremse_ESP_EPB_EBC460Vi SG_ 1719 KBI_Standzeit_02 5000;
BA_REL_ "GenSigTimeoutTime" BU_SG_REL_ Bremse_ESP_EPB_EBC460Vi SG_ 1719 KBI_QBit_Aussen_Temp_gef 5000;
BA_REL_ "GenSigTimeoutTime" BU_SG_REL_ Bremse_ESP_EPB_EBC460Vi SG_ 1719 KBI_Aussen_Temp_gef 5000;
BA_REL_ "GenSigTimeoutTime" BU_SG_REL_ Bremse_ESP_EPB_EBC460Vi SG_ 1720 KBI_Reifenumfang 5000;
BA_REL_ "GenSigTimeoutTime" BU_SG_REL_ Bremse_ESP_EPB_EBC460Vi SG_ 810 EPS_01_CRC 500;
BA_REL_ "GenSigTimeoutTime" BU_SG_REL_ Bremse_ESP_EPB_EBC460Vi SG_ 810 EPS_01_BZ 500;
BA_REL_ "GenSigTimeoutTime" BU_SG_REL_ Bremse_ESP_EPB_EBC460Vi SG_ 810 EPS_PLA_Status 500;
BA_REL_ "GenSigTimeoutTime" BU_SG_REL_ Bremse_ESP_EPB_EBC460Vi SG_ 810 EPS_Lenkerposition 500;
BA_REL_ "GenSigTimeoutTime" BU_SG_REL_ Bremse_ESP_EPB_EBC460Vi SG_ 159 EPS_03_CRC 500;
BA_REL_ "GenSigTimeoutTime" BU_SG_REL_ Bremse_ESP_EPB_EBC460Vi SG_ 159 EPS_03_BZ 500;
BA_REL_ "GenSigTimeoutTime" BU_SG_REL_ Bremse_ESP_EPB_EBC460Vi SG_ 159 EPS_DSR_Status 500;
BA_REL_ "GenSigTimeoutTime" BU_SG_REL_ Bremse_ESP_EPB_EBC460Vi SG_ 159 EPS_Berechneter_LW 500;
BA_REL_ "GenSigTimeoutTime" BU_SG_REL_ Bremse_ESP_EPB_EBC460Vi SG_ 159 EPS_BLW_QBit 500;
BA_REL_ "GenSigTimeoutTime" BU_SG_REL_ Bremse_ESP_EPB_EBC460Vi SG_ 159 EPS_VZ_BLW 500;
BA_REL_ "GenSigTimeoutTime" BU_SG_REL_ Bremse_ESP_EPB_EBC460Vi SG_ 159 EPS_Lenkmoment 500;
BA_REL_ "GenSigTimeoutTime" BU_SG_REL_ Bremse_ESP_EPB_EBC460Vi SG_ 159 EPS_Lenkmoment_QBit 500;
BA_REL_ "GenSigTimeoutTime" BU_SG_REL_ Bremse_ESP_EPB_EBC460Vi SG_ 159 EPS_VZ_Lenkmoment 500;
BA_REL_ "GenSigTimeoutTime" BU_SG_REL_ Bremse_ESP_EPB_EBC460Vi SG_ 159 EPS_Lenkungstyp 500;
BA_REL_ "GenSigTimeoutTime" BU_SG_REL_ Bremse_ESP_EPB_EBC460Vi SG_ 134 LWI_01_CRC 500;
BA_REL_ "GenSigTimeoutTime" BU_SG_REL_ Bremse_ESP_EPB_EBC460Vi SG_ 134 LWI_01_BZ 500;
BA_REL_ "GenSigTimeoutTime" BU_SG_REL_ Bremse_ESP_EPB_EBC460Vi SG_ 134 LWI_Sensorstatus 500;
BA_REL_ "GenSigTimeoutTime" BU_SG_REL_ Bremse_ESP_EPB_EBC460Vi SG_ 134 LWI_QBit_Lenkradwinkel 500;
BA_REL_ "GenSigTimeoutTime" BU_SG_REL_ Bremse_ESP_EPB_EBC460Vi SG_ 134 LWI_Lenkradwinkel 500;
BA_REL_ "GenSigTimeoutTime" BU_SG_REL_ Bremse_ESP_EPB_EBC460Vi SG_ 134 LWI_VZ_Lenkradwinkel 500;
BA_REL_ "GenSigTimeoutTime" BU_SG_REL_ Bremse_ESP_EPB_EBC460Vi SG_ 134 LWI_VZ_Lenkradw_Geschw 500;
BA_REL_ "GenSigTimeoutTime" BU_SG_REL_ Bremse_ESP_EPB_EBC460Vi SG_ 134 LWI_Lenkradw_Geschw 500;
BA_REL_ "GenSigTimeoutTime" BU_SG_REL_ Bremse_ESP_EPB_EBC460Vi SG_ 917 LWR_Hoehenwert_VL 1000;
BA_REL_ "GenSigTimeoutTime" BU_SG_REL_ Bremse_ESP_EPB_EBC460Vi SG_ 917 LWR_Hoehenwert_HL 1000;
BA_REL_ "GenSigTimeoutTime" BU_SG_REL_ Bremse_ESP_EPB_EBC460Vi SG_ 1600 MO_QBit_Ansaugluft_Temp 5000;
BA_REL_ "GenSigTimeoutTime" BU_SG_REL_ Bremse_ESP_EPB_EBC460Vi SG_ 1600 MO_QBit_Oel_Temp 5000;
BA_REL_ "GenSigTimeoutTime" BU_SG_REL_ Bremse_ESP_EPB_EBC460Vi SG_ 1600 MO_Ansaugluft_Temp 5000;
BA_REL_ "GenSigTimeoutTime" BU_SG_REL_ Bremse_ESP_EPB_EBC460Vi SG_ 1600 MO_Oel_Temp 5000;
BA_REL_ "GenSigTimeoutTime" BU_SG_REL_ Bremse_ESP_EPB_EBC460Vi SG_ 1600 MO_Hoeheninfo 5000;
BA_REL_ "GenSigTimeoutTime" BU_SG_REL_ Bremse_ESP_EPB_EBC460Vi SG_ 1600 MO_Mom_Traegheit_02 5000;
BA_REL_ "GenSigTimeoutTime" BU_SG_REL_ Bremse_ESP_EPB_EBC460Vi SG_ 167 Motor_11_CRC 500;
BA_REL_ "GenSigTimeoutTime" BU_SG_REL_ Bremse_ESP_EPB_EBC460Vi SG_ 167 Motor_11_BZ 500;
BA_REL_ "GenSigTimeoutTime" BU_SG_REL_ Bremse_ESP_EPB_EBC460Vi SG_ 167 MO_Mom_Soll_Roh 500;
BA_REL_ "GenSigTimeoutTime" BU_SG_REL_ Bremse_ESP_EPB_EBC460Vi SG_ 167 MO_Mom_Ist_Summe 500;
BA_REL_ "GenSigTimeoutTime" BU_SG_REL_ Bremse_ESP_EPB_EBC460Vi SG_ 167 MO_Mom_Traegheit_Summe 500;
BA_REL_ "GenSigTimeoutTime" BU_SG_REL_ Bremse_ESP_EPB_EBC460Vi SG_ 167 MO_Mom_Schub 500;
BA_REL_ "GenSigTimeoutTime" BU_SG_REL_ Bremse_ESP_EPB_EBC460Vi SG_ 167 MO_QBit_Motormomente 500;
BA_REL_ "GenSigTimeoutTime" BU_SG_REL_ Bremse_ESP_EPB_EBC460Vi SG_ 168 Motor_12_CRC 500;
BA_REL_ "GenSigTimeoutTime" BU_SG_REL_ Bremse_ESP_EPB_EBC460Vi SG_ 168 Motor_12_BZ 500;
BA_REL_ "GenSigTimeoutTime" BU_SG_REL_ Bremse_ESP_EPB_EBC460Vi SG_ 168 MO_QBit_Drehzahl_01 500;
BA_REL_ "GenSigTimeoutTime" BU_SG_REL_ Bremse_ESP_EPB_EBC460Vi SG_ 168 MO_Drehzahl_01 500;
BA_REL_ "GenSigTimeoutTime" BU_SG_REL_ Bremse_ESP_EPB_EBC460Vi SG_ 958 MO_StartStopp_Status 1000;
BA_REL_ "GenSigTimeoutTime" BU_SG_REL_ Bremse_ESP_EPB_EBC460Vi SG_ 958 MO_StartStopp_Wiederstart 1000;
BA_REL_ "GenSigTimeoutTime" BU_SG_REL_ Bremse_ESP_EPB_EBC460Vi SG_ 958 MO_StartStopp_Motorstopp 1000;
BA_REL_ "GenSigTimeoutTime" BU_SG_REL_ Bremse_ESP_EPB_EBC460Vi SG_ 958 MO_Kl_75 1000;
BA_REL_ "GenSigTimeoutTime" BU_SG_REL_ Bremse_ESP_EPB_EBC460Vi SG_ 958 MO_Kl_50 1000;
BA_REL_ "GenSigTimeoutTime" BU_SG_REL_ Bremse_ESP_EPB_EBC460Vi SG_ 958 MO_Gangposition 1000;
BA_REL_ "GenSigTimeoutTime" BU_SG_REL_ Bremse_ESP_EPB_EBC460Vi SG_ 958 MO_StartStopp_Fahrerwunsch 1000;
BA_REL_ "GenSigTimeoutTime" BU_SG_REL_ Bremse_ESP_EPB_EBC460Vi SG_ 958 MO_Fahrer_bremst 1000;
BA_REL_ "GenSigTimeoutTime" BU_SG_REL_ Bremse_ESP_EPB_EBC460Vi SG_ 958 MO_QBit_Fahrer_bremst 1000;
BA_REL_ "GenSigTimeoutTime" BU_SG_REL_ Bremse_ESP_EPB_EBC460Vi SG_ 958 MO_BLS 1000;
BA_REL_ "GenSigTimeoutTime" BU_SG_REL_ Bremse_ESP_EPB_EBC460Vi SG_ 958 MO_Timeout_ESP 1000;
BA_REL_ "GenSigTimeoutTime" BU_SG_REL_ Bremse_ESP_EPB_EBC460Vi SG_ 958 MO_Kuppl_schalter 1000;
BA_REL_ "GenSigTimeoutTime" BU_SG_REL_ Bremse_ESP_EPB_EBC460Vi SG_ 958 MO_Interlock 1000;
BA_REL_ "GenSigTimeoutTime" BU_SG_REL_ Bremse_ESP_EPB_EBC460Vi SG_ 958 MO_Motor_laeuft 1000;
BA_REL_ "GenSigTimeoutTime" BU_SG_REL_ Bremse_ESP_EPB_EBC460Vi SG_ 958 MO_QBit_Gangposition 1000;
BA_REL_ "GenSigTimeoutTime" BU_SG_REL_ Bremse_ESP_EPB_EBC460Vi SG_ 958 MO_Signalquelle_Gangposition 1000;
BA_REL_ "GenSigTimeoutTime" BU_SG_REL_ Bremse_ESP_EPB_EBC460Vi SG_ 958 MO_Zylinderabschaltung 1000;
BA_REL_ "GenSigTimeoutTime" BU_SG_REL_ Bremse_ESP_EPB_EBC460Vi SG_ 1631 TSK_QBit_Fahrzeugmasse 5000;
BA_REL_ "GenSigTimeoutTime" BU_SG_REL_ Bremse_ESP_EPB_EBC460Vi SG_ 1631 TSK_Fahrzeugmasse_02 5000;
BA_REL_ "GenSigTimeoutTime" BU_SG_REL_ Bremse_ESP_EPB_EBC460Vi SG_ 289 Motor_20_CRC 500;
BA_REL_ "GenSigTimeoutTime" BU_SG_REL_ Bremse_ESP_EPB_EBC460Vi SG_ 289 Motor_20_BZ 500;
BA_REL_ "GenSigTimeoutTime" BU_SG_REL_ Bremse_ESP_EPB_EBC460Vi SG_ 289 MO_Fahrpedalrohwert_01 500;
BA_REL_ "GenSigTimeoutTime" BU_SG_REL_ Bremse_ESP_EPB_EBC460Vi SG_ 289 MO_QBit_Fahrpedalwerte_01 500;
BA_REL_ "GenSigTimeoutTime" BU_SG_REL_ Bremse_ESP_EPB_EBC460Vi SG_ 289 MO_Fahrpedalgradient 500;
BA_REL_ "GenSigTimeoutTime" BU_SG_REL_ Bremse_ESP_EPB_EBC460Vi SG_ 289 MO_Sig_Fahrpedalgradient 500;
BA_REL_ "GenSigTimeoutTime" BU_SG_REL_ Bremse_ESP_EPB_EBC460Vi SG_ 289 MO_rel_Saugrohrdruck 500;
BA_REL_ "GenSigTimeoutTime" BU_SG_REL_ Bremse_ESP_EPB_EBC460Vi SG_ 289 MO_rel_Saugrohrdruck_gem_err 500;
BA_REL_ "GenSigTimeoutTime" BU_SG_REL_ Bremse_ESP_EPB_EBC460Vi SG_ 289 MO_Moment_im_Leerlauf 500;
BA_REL_ "GenSigTimeoutTime" BU_SG_REL_ Bremse_ESP_EPB_EBC460Vi SG_ 289 MO_Schubabschaltung 500;
BA_REL_ "GenSigTimeoutTime" BU_SG_REL_ Bremse_ESP_EPB_EBC460Vi SG_ 289 MO_Solldrehz_Leerlauf 500;
BA_REL_ "GenSigTimeoutTime" BU_SG_REL_ Bremse_ESP_EPB_EBC460Vi SG_ 283 MO_NGS_Gangpos 1000;
BA_REL_ "GenSigTimeoutTime" BU_SG_REL_ Bremse_ESP_EPB_MK100 SG_ 779 KBI_ABS_Lampe 500;
BA_REL_ "GenSigTimeoutTime" BU_SG_REL_ Bremse_ESP_EPB_MK100 SG_ 779 KBI_ESP_Lampe 500;
BA_REL_ "GenSigTimeoutTime" BU_SG_REL_ Bremse_ESP_EPB_MK100 SG_ 779 KBI_BKL_Lampe 500;
BA_REL_ "GenSigTimeoutTime" BU_SG_REL_ Bremse_ESP_EPB_MK100 SG_ 779 KBI_SILA_gueltig 500;
BA_REL_ "GenSigTimeoutTime" BU_SG_REL_ Bremse_ESP_EPB_MK100 SG_ 779 KBI_Handbremse 500;
BA_REL_ "GenSigTimeoutTime" BU_SG_REL_ Bremse_ESP_EPB_MK100 SG_ 1719 KBI_Standzeit_02 5000;
BA_REL_ "GenSigTimeoutTime" BU_SG_REL_ Bremse_ESP_EPB_MK100 SG_ 1719 KBI_QBit_Aussen_Temp_gef 5000;
BA_REL_ "GenSigTimeoutTime" BU_SG_REL_ Bremse_ESP_EPB_MK100 SG_ 1719 KBI_Aussen_Temp_gef 5000;
BA_REL_ "GenSigTimeoutTime" BU_SG_REL_ Bremse_ESP_EPB_MK100 SG_ 1720 KBI_Reifenumfang 5000;
BA_REL_ "GenSigTimeoutTime" BU_SG_REL_ Bremse_ESP_EPB_MK100 SG_ 810 EPS_01_CRC 500;
BA_REL_ "GenSigTimeoutTime" BU_SG_REL_ Bremse_ESP_EPB_MK100 SG_ 810 EPS_01_BZ 500;
BA_REL_ "GenSigTimeoutTime" BU_SG_REL_ Bremse_ESP_EPB_MK100 SG_ 810 EPS_PLA_Status 500;
BA_REL_ "GenSigTimeoutTime" BU_SG_REL_ Bremse_ESP_EPB_MK100 SG_ 810 EPS_Lenkerposition 500;
BA_REL_ "GenSigTimeoutTime" BU_SG_REL_ Bremse_ESP_EPB_MK100 SG_ 159 EPS_03_CRC 500;
BA_REL_ "GenSigTimeoutTime" BU_SG_REL_ Bremse_ESP_EPB_MK100 SG_ 159 EPS_03_BZ 500;
BA_REL_ "GenSigTimeoutTime" BU_SG_REL_ Bremse_ESP_EPB_MK100 SG_ 159 EPS_DSR_Status 500;
BA_REL_ "GenSigTimeoutTime" BU_SG_REL_ Bremse_ESP_EPB_MK100 SG_ 159 EPS_Berechneter_LW 500;
BA_REL_ "GenSigTimeoutTime" BU_SG_REL_ Bremse_ESP_EPB_MK100 SG_ 159 EPS_BLW_QBit 500;
BA_REL_ "GenSigTimeoutTime" BU_SG_REL_ Bremse_ESP_EPB_MK100 SG_ 159 EPS_VZ_BLW 500;
BA_REL_ "GenSigTimeoutTime" BU_SG_REL_ Bremse_ESP_EPB_MK100 SG_ 159 EPS_Lenkmoment 500;
BA_REL_ "GenSigTimeoutTime" BU_SG_REL_ Bremse_ESP_EPB_MK100 SG_ 159 EPS_Lenkmoment_QBit 500;
BA_REL_ "GenSigTimeoutTime" BU_SG_REL_ Bremse_ESP_EPB_MK100 SG_ 159 EPS_VZ_Lenkmoment 500;
BA_REL_ "GenSigTimeoutTime" BU_SG_REL_ Bremse_ESP_EPB_MK100 SG_ 159 EPS_Lenkungstyp 500;
BA_REL_ "GenSigTimeoutTime" BU_SG_REL_ Bremse_ESP_EPB_MK100 SG_ 134 LWI_01_CRC 500;
BA_REL_ "GenSigTimeoutTime" BU_SG_REL_ Bremse_ESP_EPB_MK100 SG_ 134 LWI_01_BZ 500;
BA_REL_ "GenSigTimeoutTime" BU_SG_REL_ Bremse_ESP_EPB_MK100 SG_ 134 LWI_Sensorstatus 500;
BA_REL_ "GenSigTimeoutTime" BU_SG_REL_ Bremse_ESP_EPB_MK100 SG_ 134 LWI_QBit_Lenkradwinkel 500;
BA_REL_ "GenSigTimeoutTime" BU_SG_REL_ Bremse_ESP_EPB_MK100 SG_ 134 LWI_Lenkradwinkel 500;
BA_REL_ "GenSigTimeoutTime" BU_SG_REL_ Bremse_ESP_EPB_MK100 SG_ 134 LWI_VZ_Lenkradwinkel 500;
BA_REL_ "GenSigTimeoutTime" BU_SG_REL_ Bremse_ESP_EPB_MK100 SG_ 134 LWI_VZ_Lenkradw_Geschw 500;
BA_REL_ "GenSigTimeoutTime" BU_SG_REL_ Bremse_ESP_EPB_MK100 SG_ 134 LWI_Lenkradw_Geschw 500;
BA_REL_ "GenSigTimeoutTime" BU_SG_REL_ Bremse_ESP_EPB_MK100 SG_ 917 LWR_Hoehenwert_VL 1000;
BA_REL_ "GenSigTimeoutTime" BU_SG_REL_ Bremse_ESP_EPB_MK100 SG_ 917 LWR_Hoehenwert_HL 1000;
BA_REL_ "GenSigTimeoutTime" BU_SG_REL_ Bremse_ESP_EPB_MK100 SG_ 1600 MO_QBit_Ansaugluft_Temp 5000;
BA_REL_ "GenSigTimeoutTime" BU_SG_REL_ Bremse_ESP_EPB_MK100 SG_ 1600 MO_QBit_Oel_Temp 5000;
BA_REL_ "GenSigTimeoutTime" BU_SG_REL_ Bremse_ESP_EPB_MK100 SG_ 1600 MO_Ansaugluft_Temp 5000;
BA_REL_ "GenSigTimeoutTime" BU_SG_REL_ Bremse_ESP_EPB_MK100 SG_ 1600 MO_Oel_Temp 5000;
BA_REL_ "GenSigTimeoutTime" BU_SG_REL_ Bremse_ESP_EPB_MK100 SG_ 1600 MO_Hoeheninfo 5000;
BA_REL_ "GenSigTimeoutTime" BU_SG_REL_ Bremse_ESP_EPB_MK100 SG_ 1600 MO_Mom_Traegheit_02 5000;
BA_REL_ "GenSigTimeoutTime" BU_SG_REL_ Bremse_ESP_EPB_MK100 SG_ 167 Motor_11_CRC 500;
BA_REL_ "GenSigTimeoutTime" BU_SG_REL_ Bremse_ESP_EPB_MK100 SG_ 167 Motor_11_BZ 500;
BA_REL_ "GenSigTimeoutTime" BU_SG_REL_ Bremse_ESP_EPB_MK100 SG_ 167 MO_Mom_Soll_Roh 500;
BA_REL_ "GenSigTimeoutTime" BU_SG_REL_ Bremse_ESP_EPB_MK100 SG_ 167 MO_Mom_Ist_Summe 500;
BA_REL_ "GenSigTimeoutTime" BU_SG_REL_ Bremse_ESP_EPB_MK100 SG_ 167 MO_Mom_Traegheit_Summe 500;
BA_REL_ "GenSigTimeoutTime" BU_SG_REL_ Bremse_ESP_EPB_MK100 SG_ 167 MO_Mom_Schub 500;
BA_REL_ "GenSigTimeoutTime" BU_SG_REL_ Bremse_ESP_EPB_MK100 SG_ 167 MO_QBit_Motormomente 500;
BA_REL_ "GenSigTimeoutTime" BU_SG_REL_ Bremse_ESP_EPB_MK100 SG_ 168 Motor_12_CRC 500;
BA_REL_ "GenSigTimeoutTime" BU_SG_REL_ Bremse_ESP_EPB_MK100 SG_ 168 Motor_12_BZ 500;
BA_REL_ "GenSigTimeoutTime" BU_SG_REL_ Bremse_ESP_EPB_MK100 SG_ 168 MO_Mom_Begr_Fahr 500;
BA_REL_ "GenSigTimeoutTime" BU_SG_REL_ Bremse_ESP_EPB_MK100 SG_ 168 MO_QBit_Drehzahl_01 500;
BA_REL_ "GenSigTimeoutTime" BU_SG_REL_ Bremse_ESP_EPB_MK100 SG_ 168 MO_Drehzahl_01 500;
BA_REL_ "GenSigTimeoutTime" BU_SG_REL_ Bremse_ESP_EPB_MK100 SG_ 958 MO_StartStopp_Status 1000;
BA_REL_ "GenSigTimeoutTime" BU_SG_REL_ Bremse_ESP_EPB_MK100 SG_ 958 MO_StartStopp_Wiederstart 1000;
BA_REL_ "GenSigTimeoutTime" BU_SG_REL_ Bremse_ESP_EPB_MK100 SG_ 958 MO_StartStopp_Motorstopp 1000;
BA_REL_ "GenSigTimeoutTime" BU_SG_REL_ Bremse_ESP_EPB_MK100 SG_ 958 MO_Kl_75 1000;
BA_REL_ "GenSigTimeoutTime" BU_SG_REL_ Bremse_ESP_EPB_MK100 SG_ 958 MO_Kl_50 1000;
BA_REL_ "GenSigTimeoutTime" BU_SG_REL_ Bremse_ESP_EPB_MK100 SG_ 958 MO_Gangposition 1000;
BA_REL_ "GenSigTimeoutTime" BU_SG_REL_ Bremse_ESP_EPB_MK100 SG_ 958 MO_StartStopp_Fahrerwunsch 1000;
BA_REL_ "GenSigTimeoutTime" BU_SG_REL_ Bremse_ESP_EPB_MK100 SG_ 958 MO_HYB_Fahrbereitschaft 1000;
BA_REL_ "GenSigTimeoutTime" BU_SG_REL_ Bremse_ESP_EPB_MK100 SG_ 958 MO_Fahrer_bremst 1000;
BA_REL_ "GenSigTimeoutTime" BU_SG_REL_ Bremse_ESP_EPB_MK100 SG_ 958 MO_QBit_Fahrer_bremst 1000;
BA_REL_ "GenSigTimeoutTime" BU_SG_REL_ Bremse_ESP_EPB_MK100 SG_ 958 MO_BLS 1000;
BA_REL_ "GenSigTimeoutTime" BU_SG_REL_ Bremse_ESP_EPB_MK100 SG_ 958 MO_Timeout_ESP 1000;
BA_REL_ "GenSigTimeoutTime" BU_SG_REL_ Bremse_ESP_EPB_MK100 SG_ 958 MO_Kuppl_schalter 1000;
BA_REL_ "GenSigTimeoutTime" BU_SG_REL_ Bremse_ESP_EPB_MK100 SG_ 958 MO_Interlock 1000;
BA_REL_ "GenSigTimeoutTime" BU_SG_REL_ Bremse_ESP_EPB_MK100 SG_ 958 MO_Motor_laeuft 1000;
BA_REL_ "GenSigTimeoutTime" BU_SG_REL_ Bremse_ESP_EPB_MK100 SG_ 958 MO_QBit_Gangposition 1000;
BA_REL_ "GenSigTimeoutTime" BU_SG_REL_ Bremse_ESP_EPB_MK100 SG_ 958 MO_Signalquelle_Gangposition 1000;
BA_REL_ "GenSigTimeoutTime" BU_SG_REL_ Bremse_ESP_EPB_MK100 SG_ 958 MO_FMAus_aktiv 1000;
BA_REL_ "GenSigTimeoutTime" BU_SG_REL_ Bremse_ESP_EPB_MK100 SG_ 958 MO_Zylinderabschaltung 1000;
BA_REL_ "GenSigTimeoutTime" BU_SG_REL_ Bremse_ESP_EPB_MK100 SG_ 1631 TSK_QBit_Fahrzeugmasse 5000;
BA_REL_ "GenSigTimeoutTime" BU_SG_REL_ Bremse_ESP_EPB_MK100 SG_ 1631 TSK_Fahrzeugmasse_02 5000;
BA_REL_ "GenSigTimeoutTime" BU_SG_REL_ Bremse_ESP_EPB_MK100 SG_ 1648 MO_Fahrzeugtyp 5000;
BA_REL_ "GenSigTimeoutTime" BU_SG_REL_ Bremse_ESP_EPB_MK100 SG_ 289 Motor_20_CRC 500;
BA_REL_ "GenSigTimeoutTime" BU_SG_REL_ Bremse_ESP_EPB_MK100 SG_ 289 Motor_20_BZ 500;
BA_REL_ "GenSigTimeoutTime" BU_SG_REL_ Bremse_ESP_EPB_MK100 SG_ 289 MO_Fahrpedalrohwert_01 500;
BA_REL_ "GenSigTimeoutTime" BU_SG_REL_ Bremse_ESP_EPB_MK100 SG_ 289 MO_QBit_Fahrpedalwerte_01 500;
BA_REL_ "GenSigTimeoutTime" BU_SG_REL_ Bremse_ESP_EPB_MK100 SG_ 289 MO_Fahrpedalgradient 500;
BA_REL_ "GenSigTimeoutTime" BU_SG_REL_ Bremse_ESP_EPB_MK100 SG_ 289 MO_Sig_Fahrpedalgradient 500;
BA_REL_ "GenSigTimeoutTime" BU_SG_REL_ Bremse_ESP_EPB_MK100 SG_ 289 MO_rel_Saugrohrdruck 500;
BA_REL_ "GenSigTimeoutTime" BU_SG_REL_ Bremse_ESP_EPB_MK100 SG_ 289 MO_rel_Saugrohrdruck_gem_err 500;
BA_REL_ "GenSigTimeoutTime" BU_SG_REL_ Bremse_ESP_EPB_MK100 SG_ 289 MO_Moment_im_Leerlauf 500;
BA_REL_ "GenSigTimeoutTime" BU_SG_REL_ Bremse_ESP_EPB_MK100 SG_ 289 MO_Schubabschaltung 500;
BA_REL_ "GenSigTimeoutTime" BU_SG_REL_ Bremse_ESP_EPB_MK100 SG_ 289 MO_Solldrehz_Leerlauf 500;
BA_REL_ "GenSigTimeoutTime" BU_SG_REL_ Bremse_ESP_EPB_MK100 SG_ 283 MO_NGS_Gangpos 1000;
BA_REL_ "GenSigTimeoutTime" BU_SG_REL_ Bremse_ESP_MK100 SG_ 779 KBI_ABS_Lampe 500;
BA_REL_ "GenSigTimeoutTime" BU_SG_REL_ Bremse_ESP_MK100 SG_ 779 KBI_ESP_Lampe 500;
BA_REL_ "GenSigTimeoutTime" BU_SG_REL_ Bremse_ESP_MK100 SG_ 779 KBI_BKL_Lampe 500;
BA_REL_ "GenSigTimeoutTime" BU_SG_REL_ Bremse_ESP_MK100 SG_ 779 KBI_SILA_gueltig 500;
BA_REL_ "GenSigTimeoutTime" BU_SG_REL_ Bremse_ESP_MK100 SG_ 779 KBI_Handbremse 500;
BA_REL_ "GenSigTimeoutTime" BU_SG_REL_ Bremse_ESP_MK100 SG_ 1719 KBI_Standzeit_02 5000;
BA_REL_ "GenSigTimeoutTime" BU_SG_REL_ Bremse_ESP_MK100 SG_ 1719 KBI_QBit_Aussen_Temp_gef 5000;
BA_REL_ "GenSigTimeoutTime" BU_SG_REL_ Bremse_ESP_MK100 SG_ 1719 KBI_Aussen_Temp_gef 5000;
BA_REL_ "GenSigTimeoutTime" BU_SG_REL_ Bremse_ESP_MK100 SG_ 1720 KBI_Reifenumfang 5000;
BA_REL_ "GenSigTimeoutTime" BU_SG_REL_ Bremse_ESP_MK100 SG_ 810 EPS_01_CRC 500;
BA_REL_ "GenSigTimeoutTime" BU_SG_REL_ Bremse_ESP_MK100 SG_ 810 EPS_01_BZ 500;
BA_REL_ "GenSigTimeoutTime" BU_SG_REL_ Bremse_ESP_MK100 SG_ 810 EPS_PLA_Status 500;
BA_REL_ "GenSigTimeoutTime" BU_SG_REL_ Bremse_ESP_MK100 SG_ 810 EPS_Lenkerposition 500;
BA_REL_ "GenSigTimeoutTime" BU_SG_REL_ Bremse_ESP_MK100 SG_ 159 EPS_03_CRC 500;
BA_REL_ "GenSigTimeoutTime" BU_SG_REL_ Bremse_ESP_MK100 SG_ 159 EPS_03_BZ 500;
BA_REL_ "GenSigTimeoutTime" BU_SG_REL_ Bremse_ESP_MK100 SG_ 159 EPS_DSR_Status 500;
BA_REL_ "GenSigTimeoutTime" BU_SG_REL_ Bremse_ESP_MK100 SG_ 159 EPS_Berechneter_LW 500;
BA_REL_ "GenSigTimeoutTime" BU_SG_REL_ Bremse_ESP_MK100 SG_ 159 EPS_BLW_QBit 500;
BA_REL_ "GenSigTimeoutTime" BU_SG_REL_ Bremse_ESP_MK100 SG_ 159 EPS_VZ_BLW 500;
BA_REL_ "GenSigTimeoutTime" BU_SG_REL_ Bremse_ESP_MK100 SG_ 159 EPS_Lenkmoment 500;
BA_REL_ "GenSigTimeoutTime" BU_SG_REL_ Bremse_ESP_MK100 SG_ 159 EPS_Lenkmoment_QBit 500;
BA_REL_ "GenSigTimeoutTime" BU_SG_REL_ Bremse_ESP_MK100 SG_ 159 EPS_VZ_Lenkmoment 500;
BA_REL_ "GenSigTimeoutTime" BU_SG_REL_ Bremse_ESP_MK100 SG_ 159 EPS_Lenkungstyp 500;
BA_REL_ "GenSigTimeoutTime" BU_SG_REL_ Bremse_ESP_MK100 SG_ 134 LWI_01_CRC 500;
BA_REL_ "GenSigTimeoutTime" BU_SG_REL_ Bremse_ESP_MK100 SG_ 134 LWI_01_BZ 500;
BA_REL_ "GenSigTimeoutTime" BU_SG_REL_ Bremse_ESP_MK100 SG_ 134 LWI_Sensorstatus 500;
BA_REL_ "GenSigTimeoutTime" BU_SG_REL_ Bremse_ESP_MK100 SG_ 134 LWI_QBit_Lenkradwinkel 500;
BA_REL_ "GenSigTimeoutTime" BU_SG_REL_ Bremse_ESP_MK100 SG_ 134 LWI_Lenkradwinkel 500;
BA_REL_ "GenSigTimeoutTime" BU_SG_REL_ Bremse_ESP_MK100 SG_ 134 LWI_VZ_Lenkradwinkel 500;
BA_REL_ "GenSigTimeoutTime" BU_SG_REL_ Bremse_ESP_MK100 SG_ 134 LWI_VZ_Lenkradw_Geschw 500;
BA_REL_ "GenSigTimeoutTime" BU_SG_REL_ Bremse_ESP_MK100 SG_ 134 LWI_Lenkradw_Geschw 500;
BA_REL_ "GenSigTimeoutTime" BU_SG_REL_ Bremse_ESP_MK100 SG_ 917 LWR_Hoehenwert_VL 1000;
BA_REL_ "GenSigTimeoutTime" BU_SG_REL_ Bremse_ESP_MK100 SG_ 917 LWR_Hoehenwert_HL 1000;
BA_REL_ "GenSigTimeoutTime" BU_SG_REL_ Bremse_ESP_MK100 SG_ 1600 MO_QBit_Ansaugluft_Temp 5000;
BA_REL_ "GenSigTimeoutTime" BU_SG_REL_ Bremse_ESP_MK100 SG_ 1600 MO_Ansaugluft_Temp 5000;
BA_REL_ "GenSigTimeoutTime" BU_SG_REL_ Bremse_ESP_MK100 SG_ 1600 MO_Hoeheninfo 5000;
BA_REL_ "GenSigTimeoutTime" BU_SG_REL_ Bremse_ESP_MK100 SG_ 1600 MO_Mom_Traegheit_02 5000;
BA_REL_ "GenSigTimeoutTime" BU_SG_REL_ Bremse_ESP_MK100 SG_ 167 Motor_11_CRC 500;
BA_REL_ "GenSigTimeoutTime" BU_SG_REL_ Bremse_ESP_MK100 SG_ 167 Motor_11_BZ 500;
BA_REL_ "GenSigTimeoutTime" BU_SG_REL_ Bremse_ESP_MK100 SG_ 167 MO_Mom_Soll_Roh 500;
BA_REL_ "GenSigTimeoutTime" BU_SG_REL_ Bremse_ESP_MK100 SG_ 167 MO_Mom_Ist_Summe 500;
BA_REL_ "GenSigTimeoutTime" BU_SG_REL_ Bremse_ESP_MK100 SG_ 167 MO_Mom_Traegheit_Summe 500;
BA_REL_ "GenSigTimeoutTime" BU_SG_REL_ Bremse_ESP_MK100 SG_ 167 MO_Mom_Schub 500;
BA_REL_ "GenSigTimeoutTime" BU_SG_REL_ Bremse_ESP_MK100 SG_ 167 MO_QBit_Motormomente 500;
BA_REL_ "GenSigTimeoutTime" BU_SG_REL_ Bremse_ESP_MK100 SG_ 168 Motor_12_CRC 500;
BA_REL_ "GenSigTimeoutTime" BU_SG_REL_ Bremse_ESP_MK100 SG_ 168 Motor_12_BZ 500;
BA_REL_ "GenSigTimeoutTime" BU_SG_REL_ Bremse_ESP_MK100 SG_ 168 MO_Mom_Begr_Fahr 500;
BA_REL_ "GenSigTimeoutTime" BU_SG_REL_ Bremse_ESP_MK100 SG_ 168 MO_QBit_Drehzahl_01 500;
BA_REL_ "GenSigTimeoutTime" BU_SG_REL_ Bremse_ESP_MK100 SG_ 168 MO_Drehzahl_01 500;
BA_REL_ "GenSigTimeoutTime" BU_SG_REL_ Bremse_ESP_MK100 SG_ 958 MO_StartStopp_Status 1000;
BA_REL_ "GenSigTimeoutTime" BU_SG_REL_ Bremse_ESP_MK100 SG_ 958 MO_StartStopp_Wiederstart 1000;
BA_REL_ "GenSigTimeoutTime" BU_SG_REL_ Bremse_ESP_MK100 SG_ 958 MO_StartStopp_Motorstopp 1000;
BA_REL_ "GenSigTimeoutTime" BU_SG_REL_ Bremse_ESP_MK100 SG_ 958 MO_StartStopp_Fahrerwunsch 1000;
BA_REL_ "GenSigTimeoutTime" BU_SG_REL_ Bremse_ESP_MK100 SG_ 958 MO_Fahrer_bremst 1000;
BA_REL_ "GenSigTimeoutTime" BU_SG_REL_ Bremse_ESP_MK100 SG_ 958 MO_QBit_Fahrer_bremst 1000;
BA_REL_ "GenSigTimeoutTime" BU_SG_REL_ Bremse_ESP_MK100 SG_ 958 MO_BLS 1000;
BA_REL_ "GenSigTimeoutTime" BU_SG_REL_ Bremse_ESP_MK100 SG_ 958 MO_Timeout_ESP 1000;
BA_REL_ "GenSigTimeoutTime" BU_SG_REL_ Bremse_ESP_MK100 SG_ 958 MO_Kuppl_schalter 1000;
BA_REL_ "GenSigTimeoutTime" BU_SG_REL_ Bremse_ESP_MK100 SG_ 958 MO_Motor_laeuft 1000;
BA_REL_ "GenSigTimeoutTime" BU_SG_REL_ Bremse_ESP_MK100 SG_ 958 MO_Zylinderabschaltung 1000;
BA_REL_ "GenSigTimeoutTime" BU_SG_REL_ Bremse_ESP_MK100 SG_ 1631 TSK_QBit_Fahrzeugmasse 5000;
BA_REL_ "GenSigTimeoutTime" BU_SG_REL_ Bremse_ESP_MK100 SG_ 1631 TSK_Fahrzeugmasse_02 5000;
BA_REL_ "GenSigTimeoutTime" BU_SG_REL_ Bremse_ESP_MK100 SG_ 289 Motor_20_CRC 500;
BA_REL_ "GenSigTimeoutTime" BU_SG_REL_ Bremse_ESP_MK100 SG_ 289 Motor_20_BZ 500;
BA_REL_ "GenSigTimeoutTime" BU_SG_REL_ Bremse_ESP_MK100 SG_ 289 MO_Fahrpedalrohwert_01 500;
BA_REL_ "GenSigTimeoutTime" BU_SG_REL_ Bremse_ESP_MK100 SG_ 289 MO_QBit_Fahrpedalwerte_01 500;
BA_REL_ "GenSigTimeoutTime" BU_SG_REL_ Bremse_ESP_MK100 SG_ 289 MO_Fahrpedalgradient 500;
BA_REL_ "GenSigTimeoutTime" BU_SG_REL_ Bremse_ESP_MK100 SG_ 289 MO_Sig_Fahrpedalgradient 500;
BA_REL_ "GenSigTimeoutTime" BU_SG_REL_ Bremse_ESP_MK100 SG_ 289 MO_rel_Saugrohrdruck 500;
BA_REL_ "GenSigTimeoutTime" BU_SG_REL_ Bremse_ESP_MK100 SG_ 289 MO_rel_Saugrohrdruck_gem_err 500;
BA_REL_ "GenSigTimeoutTime" BU_SG_REL_ Bremse_ESP_MK100 SG_ 289 MO_Moment_im_Leerlauf 500;
BA_REL_ "GenSigTimeoutTime" BU_SG_REL_ Bremse_ESP_MK100 SG_ 289 MO_Schubabschaltung 500;
BA_REL_ "GenSigTimeoutTime" BU_SG_REL_ Bremse_ESP_MK100 SG_ 289 MO_Solldrehz_Leerlauf 500;
BA_REL_ "GenSigTimeoutTime" BU_SG_REL_ Daempfer SG_ 134 LWI_Sensorstatus 500;
BA_REL_ "GenSigTimeoutTime" BU_SG_REL_ Daempfer SG_ 134 LWI_QBit_Lenkradwinkel 500;
BA_REL_ "GenSigTimeoutTime" BU_SG_REL_ Daempfer SG_ 134 LWI_Lenkradwinkel 500;
BA_REL_ "GenSigTimeoutTime" BU_SG_REL_ Daempfer SG_ 134 LWI_VZ_Lenkradwinkel 500;
BA_REL_ "GenSigTimeoutTime" BU_SG_REL_ Daempfer SG_ 958 MO_BLS 1000;
BA_REL_ "GenSigTimeoutTime" BU_SG_REL_ Daempfer SG_ 289 MO_Fahrpedalrohwert_01 500;
BA_REL_ "GenSigTimeoutTime" BU_SG_REL_ Daempfer SG_ 289 MO_QBit_Fahrpedalwerte_01 500;
BA_REL_ "GenSigTimeoutTime" BU_SG_REL_ Gateway_MQB SG_ 810 EPS_Charisma_FahrPr 500;
BA_REL_ "GenSigTimeoutTime" BU_SG_REL_ Gateway_MQB SG_ 810 EPS_Charisma_Status 500;
BA_REL_ "GenSigTimeoutTime" BU_SG_REL_ Gateway_MQB SG_ 810 EPS_Anf_KL 500;
BA_REL_ "GenSigTimeoutTime" BU_SG_REL_ Gateway_MQB SG_ 285 EPS_Notlauf 500;
BA_REL_ "GenSigTimeoutTime" BU_SG_REL_ Gateway_MQB SG_ 285 EPS_Lastinfo 500;
BA_REL_ "GenSigTimeoutTime" BU_SG_REL_ Gateway_MQB SG_ 285 EPS_Unterstuetzungsleistung 500;
BA_REL_ "GenSigTimeoutTime" BU_SG_REL_ Gateway_MQB SG_ 285 EPS_StartStopp_Info 500;
BA_REL_ "GenSigTimeoutTime" BU_SG_REL_ Gateway_MQB SG_ 159 EPS_Berechneter_LW 500;
BA_REL_ "GenSigTimeoutTime" BU_SG_REL_ Gateway_MQB SG_ 159 EPS_BLW_QBit 500;
BA_REL_ "GenSigTimeoutTime" BU_SG_REL_ Gateway_MQB SG_ 159 EPS_VZ_BLW 500;
BA_REL_ "GenSigTimeoutTime" BU_SG_REL_ Gateway_MQB SG_ 159 EPS_Lenkmoment 500;
BA_REL_ "GenSigTimeoutTime" BU_SG_REL_ Gateway_MQB SG_ 159 EPS_Lenkmoment_QBit 500;
BA_REL_ "GenSigTimeoutTime" BU_SG_REL_ Gateway_MQB SG_ 159 EPS_VZ_Lenkmoment 500;
BA_REL_ "GenSigTimeoutTime" BU_SG_REL_ Gateway_MQB SG_ 134 LWI_Sensorstatus 500;
BA_REL_ "GenSigTimeoutTime" BU_SG_REL_ Gateway_MQB SG_ 134 LWI_QBit_Sub_Daten 500;
BA_REL_ "GenSigTimeoutTime" BU_SG_REL_ Lenkhilfe_EPS SG_ 779 KBI_SILA_gueltig 500;
BA_REL_ "GenSigTimeoutTime" BU_SG_REL_ Lenkhilfe_EPS SG_ 779 KBI_Lenkung_Lampe 500;
BA_REL_ "GenSigTimeoutTime" BU_SG_REL_ Lenkhilfe_EPS SG_ 779 KBI_im_Stellgliedtest 500;
BA_REL_ "GenSigTimeoutTime" BU_SG_REL_ Lenkhilfe_EPS SG_ 779 KBI_Handbremse 500;
BA_REL_ "GenSigTimeoutTime" BU_SG_REL_ Lenkhilfe_EPS SG_ 779 KBI_angez_Geschw 500;
BA_REL_ "GenSigTimeoutTime" BU_SG_REL_ Lenkhilfe_EPS SG_ 167 Motor_11_CRC 500;
BA_REL_ "GenSigTimeoutTime" BU_SG_REL_ Lenkhilfe_EPS SG_ 167 Motor_11_BZ 500;
BA_REL_ "GenSigTimeoutTime" BU_SG_REL_ Lenkhilfe_EPS SG_ 167 MO_Mom_Soll_Roh 500;
BA_REL_ "GenSigTimeoutTime" BU_SG_REL_ Lenkhilfe_EPS SG_ 167 MO_Mom_Ist_Summe 500;
BA_REL_ "GenSigTimeoutTime" BU_SG_REL_ Lenkhilfe_EPS SG_ 167 MO_Mom_Traegheit_Summe 500;
BA_REL_ "GenSigTimeoutTime" BU_SG_REL_ Lenkhilfe_EPS SG_ 167 MO_Mom_Schub 500;
BA_REL_ "GenSigTimeoutTime" BU_SG_REL_ Lenkhilfe_EPS SG_ 167 MO_QBit_Motormomente 500;
BA_REL_ "GenSigTimeoutTime" BU_SG_REL_ Lenkhilfe_EPS SG_ 168 Motor_12_CRC 500;
BA_REL_ "GenSigTimeoutTime" BU_SG_REL_ Lenkhilfe_EPS SG_ 168 Motor_12_BZ 500;
BA_REL_ "GenSigTimeoutTime" BU_SG_REL_ Lenkhilfe_EPS SG_ 168 MO_QBit_Drehzahl_01 500;
BA_REL_ "GenSigTimeoutTime" BU_SG_REL_ Lenkhilfe_EPS SG_ 168 MO_Drehzahl_01 500;
BA_REL_ "GenSigTimeoutTime" BU_SG_REL_ Lenkhilfe_EPS SG_ 958 MO_StartStopp_Status 1000;
BA_REL_ "GenSigTimeoutTime" BU_SG_REL_ Lenkhilfe_EPS SG_ 958 MO_StartStopp_Wiederstart 1000;
BA_REL_ "GenSigTimeoutTime" BU_SG_REL_ Lenkhilfe_EPS SG_ 958 MO_StartStopp_Motorstopp 1000;
BA_REL_ "GenSigTimeoutTime" BU_SG_REL_ Lenkhilfe_EPS SG_ 958 MO_Kl_75 1000;
BA_REL_ "GenSigTimeoutTime" BU_SG_REL_ Lenkhilfe_EPS SG_ 958 MO_Kl_50 1000;
BA_REL_ "GenSigTimeoutTime" BU_SG_REL_ Lenkhilfe_EPS SG_ 958 MO_StartStopp_Fahrerwunsch 1000;
BA_REL_ "GenSigTimeoutTime" BU_SG_REL_ Lenkhilfe_EPS SG_ 958 MO_HYB_Fahrbereitschaft 1000;
BA_REL_ "GenSigTimeoutTime" BU_SG_REL_ Lenkhilfe_EPS SG_ 958 MO_BLS 1000;
BA_REL_ "GenSigTimeoutTime" BU_SG_REL_ Lenkhilfe_EPS SG_ 958 MO_Freig_Anlass 1000;
BA_REL_ "GenSigTimeoutTime" BU_SG_REL_ Lenkhilfe_EPS SG_ 958 MO_Kickdown 1000;
BA_REL_ "GenSigTimeoutTime" BU_SG_REL_ Lenkhilfe_EPS SG_ 958 MO_QBit_KL_75 1000;
BA_REL_ "GenSigTimeoutTime" BU_SG_REL_ Lenkhilfe_EPS SG_ 289 MO_Fahrpedalrohwert_01 500;
BA_REL_ "GenSigTimeoutTime" BU_SG_REL_ Lenkhilfe_EPS SG_ 289 MO_QBit_Fahrpedalwerte_01 500;
BA_REL_ "GenSigTimeoutTime" BU_SG_REL_ PDC SG_ 1719 KBI_QBit_Aussen_Temp_gef 5000;
BA_REL_ "GenSigTimeoutTime" BU_SG_REL_ PDC SG_ 1719 KBI_Aussen_Temp_gef 5000;
BA_REL_ "GenSigTimeoutTime" BU_SG_REL_ PDC SG_ 1720 KBI_Reifenumfang 5000;
BA_REL_ "GenSigTimeoutTime" BU_SG_REL_ PDC SG_ 810 EPS_01_CRC 500;
BA_REL_ "GenSigTimeoutTime" BU_SG_REL_ PDC SG_ 810 EPS_01_BZ 500;
BA_REL_ "GenSigTimeoutTime" BU_SG_REL_ PDC SG_ 159 EPS_03_BZ 500;
BA_REL_ "GenSigTimeoutTime" BU_SG_REL_ PDC SG_ 159 EPS_Berechneter_LW 500;
BA_REL_ "GenSigTimeoutTime" BU_SG_REL_ PDC SG_ 159 EPS_BLW_QBit 500;
BA_REL_ "GenSigTimeoutTime" BU_SG_REL_ PDC SG_ 159 EPS_VZ_BLW 500;
BA_REL_ "GenSigTimeoutTime" BU_SG_REL_ PDC SG_ 159 EPS_Lenkmoment 500;
BA_REL_ "GenSigTimeoutTime" BU_SG_REL_ PDC SG_ 159 EPS_Lenkmoment_QBit 500;
BA_REL_ "GenSigTimeoutTime" BU_SG_REL_ PDC SG_ 159 EPS_VZ_Lenkmoment 500;
BA_REL_ "GenSigTimeoutTime" BU_SG_REL_ PDC SG_ 159 EPS_Lenkungstyp 500;
BA_REL_ "GenSigTimeoutTime" BU_SG_REL_ PDC SG_ 134 LWI_01_CRC 500;
BA_REL_ "GenSigTimeoutTime" BU_SG_REL_ PDC SG_ 134 LWI_01_BZ 500;
BA_REL_ "GenSigTimeoutTime" BU_SG_REL_ PDC SG_ 134 LWI_QBit_Lenkradwinkel 500;
BA_REL_ "GenSigTimeoutTime" BU_SG_REL_ PDC SG_ 134 LWI_Lenkradwinkel 500;
BA_REL_ "GenSigTimeoutTime" BU_SG_REL_ PDC SG_ 134 LWI_VZ_Lenkradwinkel 500;
BA_REL_ "GenSigTimeoutTime" BU_SG_REL_ PDC SG_ 168 MO_QBit_Drehzahl_01 500;
BA_REL_ "GenSigTimeoutTime" BU_SG_REL_ PDC SG_ 958 MO_StartStopp_Status 1000;
BA_REL_ "GenSigTimeoutTime" BU_SG_REL_ PDC SG_ 958 MO_StartStopp_Wiederstart 1000;
BA_REL_ "GenSigTimeoutTime" BU_SG_REL_ PDC SG_ 958 MO_Kl_75 1000;
BA_REL_ "GenSigTimeoutTime" BU_SG_REL_ PDC SG_ 958 MO_Kickdown 1000;
BA_REL_ "GenSigTimeoutTime" BU_SG_REL_ PDC SG_ 1631 TSK_Steigung_02 5000;
BA_REL_ "GenSigTimeoutTime" BU_SG_REL_ PDC SG_ 289 MO_Fahrpedalrohwert_01 500;
BA_REL_ "GenSigTimeoutTime" BU_SG_REL_ PDC SG_ 289 MO_Fahrpedalgradient 500;
BA_REL_ "GenSigTimeoutTime" BU_SG_REL_ PDC SG_ 289 MO_Sig_Fahrpedalgradient 500;
BA_REL_ "GenSigTimeoutTime" BU_SG_REL_ PDC_PLA SG_ 779 KBI_PLA_in_Anzeige 500;
BA_REL_ "GenSigTimeoutTime" BU_SG_REL_ PDC_PLA SG_ 1719 KBI_QBit_Aussen_Temp_gef 5000;
BA_REL_ "GenSigTimeoutTime" BU_SG_REL_ PDC_PLA SG_ 1719 KBI_Aussen_Temp_gef 5000;
BA_REL_ "GenSigTimeoutTime" BU_SG_REL_ PDC_PLA SG_ 1720 KBI_Reifenumfang 5000;
BA_REL_ "GenSigTimeoutTime" BU_SG_REL_ PDC_PLA SG_ 810 EPS_01_CRC 500;
BA_REL_ "GenSigTimeoutTime" BU_SG_REL_ PDC_PLA SG_ 810 EPS_01_BZ 500;
BA_REL_ "GenSigTimeoutTime" BU_SG_REL_ PDC_PLA SG_ 810 EPS_PLA_Abbruch 500;
BA_REL_ "GenSigTimeoutTime" BU_SG_REL_ PDC_PLA SG_ 810 EPS_PLA_Fehler 500;
BA_REL_ "GenSigTimeoutTime" BU_SG_REL_ PDC_PLA SG_ 810 EPS_PLA_Status 500;
BA_REL_ "GenSigTimeoutTime" BU_SG_REL_ PDC_PLA SG_ 285 EPS_Lastinfo 500;
BA_REL_ "GenSigTimeoutTime" BU_SG_REL_ PDC_PLA SG_ 285 EPS_Unterstuetzungsleistung 500;
BA_REL_ "GenSigTimeoutTime" BU_SG_REL_ PDC_PLA SG_ 159 EPS_03_CRC 500;
BA_REL_ "GenSigTimeoutTime" BU_SG_REL_ PDC_PLA SG_ 159 EPS_03_BZ 500;
BA_REL_ "GenSigTimeoutTime" BU_SG_REL_ PDC_PLA SG_ 159 EPS_Berechneter_LW 500;
BA_REL_ "GenSigTimeoutTime" BU_SG_REL_ PDC_PLA SG_ 159 EPS_BLW_QBit 500;
BA_REL_ "GenSigTimeoutTime" BU_SG_REL_ PDC_PLA SG_ 159 EPS_VZ_BLW 500;
BA_REL_ "GenSigTimeoutTime" BU_SG_REL_ PDC_PLA SG_ 159 EPS_Lenkmoment 500;
BA_REL_ "GenSigTimeoutTime" BU_SG_REL_ PDC_PLA SG_ 159 EPS_Lenkmoment_QBit 500;
BA_REL_ "GenSigTimeoutTime" BU_SG_REL_ PDC_PLA SG_ 159 EPS_VZ_Lenkmoment 500;
BA_REL_ "GenSigTimeoutTime" BU_SG_REL_ PDC_PLA SG_ 159 EPS_Lenkungstyp 500;
BA_REL_ "GenSigTimeoutTime" BU_SG_REL_ PDC_PLA SG_ 134 LWI_01_CRC 500;
BA_REL_ "GenSigTimeoutTime" BU_SG_REL_ PDC_PLA SG_ 134 LWI_01_BZ 500;
BA_REL_ "GenSigTimeoutTime" BU_SG_REL_ PDC_PLA SG_ 134 LWI_QBit_Lenkradwinkel 500;
BA_REL_ "GenSigTimeoutTime" BU_SG_REL_ PDC_PLA SG_ 134 LWI_Lenkradwinkel 500;
BA_REL_ "GenSigTimeoutTime" BU_SG_REL_ PDC_PLA SG_ 134 LWI_VZ_Lenkradwinkel 500;
BA_REL_ "GenSigTimeoutTime" BU_SG_REL_ PDC_PLA SG_ 168 MO_QBit_Drehzahl_01 500;
BA_REL_ "GenSigTimeoutTime" BU_SG_REL_ PDC_PLA SG_ 168 MO_Drehzahl_01 500;
BA_REL_ "GenSigTimeoutTime" BU_SG_REL_ PDC_PLA SG_ 958 MO_StartStopp_Status 1000;
BA_REL_ "GenSigTimeoutTime" BU_SG_REL_ PDC_PLA SG_ 958 MO_StartStopp_Wiederstart 1000;
BA_REL_ "GenSigTimeoutTime" BU_SG_REL_ PDC_PLA SG_ 958 MO_StartStopp_Motorstopp 1000;
BA_REL_ "GenSigTimeoutTime" BU_SG_REL_ PDC_PLA SG_ 958 MO_Kl_75 1000;
BA_REL_ "GenSigTimeoutTime" BU_SG_REL_ PDC_PLA SG_ 958 MO_StartStopp_Fahrerwunsch 1000;
BA_REL_ "GenSigTimeoutTime" BU_SG_REL_ PDC_PLA SG_ 958 MO_HYB_Fahrbereitschaft 1000;
BA_REL_ "GenSigTimeoutTime" BU_SG_REL_ PDC_PLA SG_ 958 MO_Fahrer_bremst 1000;
BA_REL_ "GenSigTimeoutTime" BU_SG_REL_ PDC_PLA SG_ 958 MO_QBit_Fahrer_bremst 1000;
BA_REL_ "GenSigTimeoutTime" BU_SG_REL_ PDC_PLA SG_ 958 MO_BLS 1000;
BA_REL_ "GenSigTimeoutTime" BU_SG_REL_ PDC_PLA SG_ 958 MO_Kuppl_schalter 1000;
BA_REL_ "GenSigTimeoutTime" BU_SG_REL_ PDC_PLA SG_ 958 MO_Kickdown 1000;
BA_REL_ "GenSigTimeoutTime" BU_SG_REL_ PDC_PLA SG_ 1631 TSK_Steigung_02 5000;
BA_REL_ "GenSigTimeoutTime" BU_SG_REL_ PDC_PLA SG_ 289 MO_Fahrpedalrohwert_01 500;
BA_REL_ "GenSigTimeoutTime" BU_SG_REL_ PDC_PLA SG_ 289 MO_Fahrpedalgradient 500;
BA_REL_ "GenSigTimeoutTime" BU_SG_REL_ PDC_PLA SG_ 289 MO_Sig_Fahrpedalgradient 500;
VAL_ 779 KBI_ABS_Lampe 0 "ABS Lampe aus" 1 "ABS Lampe ein" ;
VAL_ 779 KBI_ESP_Lampe 0 "ESP Lampe aus" 1 "ESP Lampe ein" ;
VAL_ 779 KBI_BKL_Lampe 0 "BKL aus" 1 "BKL ein" ;
VAL_ 779 KBI_Airbag_Lampe 0 "Airbag Lampe aus" 1 "Airbag Lampe ein" ;
VAL_ 779 KBI_SILA_gueltig 0 "ungueltig" 1 "gueltig" ;
VAL_ 779 KBI_Vorglueh_System_Lampe 0 "Lampe aus" 1 "Lampe ein" ;
VAL_ 779 KBI_NV_in_Anzeige 0 "NV_nicht_in_Anzeige" 1 "NV_in_Anzeige" ;
VAL_ 779 KBI_Anzeigestatus_ACC 0 "keine_ACC_Anzeige" 1 "ACC_Anzeige_aktiv" ;
VAL_ 779 KBI_Anzeigestatus_GRA 0 "nicht_vorhanden" 1 "Anzeigemoeglichkeit_vorhanden" 2 "reserviert" 3 "Fehler" ;
VAL_ 779 KBI_Oeldruck_Schalter 0 "offen____p_kleiner_pnenn" 1 "geschlossen____p_groessergleich_pnenn" ;
VAL_ 779 KBI_Tankwarnung 0 "Lampe aus" 1 "Lampe ein" ;
VAL_ 779 KBI_MFA_v_Einheit_01 0 "kmh" 1 "mph" ;
VAL_ 779 KBI_im_Stellgliedtest 0 "kein Stellgliedtest" 1 "Kombi im Stellgliedtest" ;
VAL_ 779 KBI_Anzeigefehler_LDW 0 "nicht vorhanden bzw. unterstützt" 1 "Anzeige iO" 2 "Anzeigefehler" 3 "nicht definiert" ;
VAL_ 779 KBI_Oeldruckwarnung 0 "inaktiv" 1 "aktiv" ;
VAL_ 779 KBI_Handbremse 0 "nicht_angezogen" 1 "angezogen" ;
VAL_ 779 KBI_PLA_in_Anzeige 0 "PLA_nicht_in_Anzeige" 1 "PLA_in_Anzeige" ;
VAL_ 779 KBI_Anzeigefehler_NV 0 "kein_Anzeigefehler" 1 "Anzeigefehler" ;
VAL_ 779 KBI_Anzeigestatus_LIM 0 "nicht_vorhanden" 1 "Anzeigemoeglichkeit_vorhanden" 2 "reserviert" 3 "Fehler" ;
VAL_ 779 KBI_ARA_in_Anzeige 0 "ARA nicht in Anzeige" 1 "ARA in Anzeige" ;
VAL_ 779 KBI_Einheit_Tacho 0 "km/h" 1 "mph" ;
VAL_ 779 KBI_Konsistenz_ACC 0 "ACC Botschaft konsistent" 1 "ACC Botschaft inkonsistent" ;
VAL_ 779 KBI_Fehler_Anzeige_ACC 0 " iO" 1 "Anzeigefehler ACC" ;
VAL_ 779 KBI_Anzeigefehler_SWA 0 "nicht vorhanden bzw. unterstützt" 1 "Anzeige iO" 2 "Anzeigefehler" 3 "nicht definiert" ;
VAL_ 1719 KBI_Kilometerstand 1048574 "Init" 1048575 "Fehler" ;
VAL_ 1719 KBI_Standzeit_02 131069 "nicht_verfuegbar" 131070 "Init" 131071 "Fehler" ;
VAL_ 1719 KBI_Reserve_Warnung_Sek 0 "Keine_Warnung" 1 "Sekundaere_Reservewarnung" ;
VAL_ 1719 KBI_RDK_Kalibrier_Anf 0 "keine_Kalibrieranforderung" 1 "Kalibrieranforderung" ;
VAL_ 1719 KBI_Inhalt_Tank 126 "Init" 127 "Fehler" ;
VAL_ 1719 KBI_FStatus_Tank 0 "Tankfüllstand i.O." 1 "Tankfüllstand n.i.O" ;
VAL_ 1719 KBI_aktive_Laengsfunktion 0 "Init" 1 "Speedlimiter" 2 "GRA_oder_ACC" 3 "PACCh" 4 "HDC" 5 "frei" 6 "frei" 7 "frei" ;
VAL_ 1719 KBI_Oelwechsel_durchgefuehrt 0 "Oelwechsel_nicht_durchgefuehrt" 1 "Oelwechsel_durchgefuehrt" ;
VAL_ 1719 KBI_QBit_Aussen_Temp_gef 0 "gueltiger_Wert" 1 "Ersatz_Init_oder_Fehlerwert" ;
VAL_ 1719 KBI_Aussen_Temp_gef 253 "nicht verbaut" 254 "Init" 255 "Fehler" ;
VAL_ 1720 KBI_Variante_USA 0 "keine USA-Variante" 1 "USA-Variante" ;
VAL_ 1720 KBI_Variante 0 "Zeiger Kombiinstrument" 1 "Volldisplay Kombiinstrument" ;
VAL_ 1720 KBI_BCmE_aktiv 0 "Anzeige_nicht_aktiv" 1 "Anzeige_aktiv" ;
VAL_ 1720 KBI_Sparhinweis_quittiert 0 "nicht_quittiert" 1 "quittiert" ;
VAL_ 1720 KBI_Tankfuellstand_Prozent 126 "Init" 127 "Fehler" ;
VAL_ 1720 KBI_Nachtanken_erkannt 0 "Geberbetrieb" 1 "Nachtankmodus" ;
VAL_ 1720 KBI_Tankinhalt_hochaufl 16382 "Init" 16383 "Fehler" ;
VAL_ 1720 KBI_Max_Tankinhalt 254 "Init" 255 "Fehler" ;
VAL_ 810 EPS_SpannungsAnf 0 "keine_Anforderung" 1 "Anforderung_Stufe1" 2 "Anforderung_Stufe2" 3 "Anforderung_Stufe3" ;
VAL_ 810 EPS_Akustiksignal 0 "Akustiksignal_nicht_aktiv" 1 "Akustiksignal_aktiv" ;
VAL_ 810 EPS_Fehlerlampe 0 "Lampe_aus" 1 "Lampe_ein" ;
VAL_ 810 EPS_Warnungen 0 "kein_Text" 1 "Text_1" 2 "Text_2" 3 "Text_3" 4 "Text_4" 5 "Text_5" ;
VAL_ 810 EPS_PLA_Status 0 "EPS_PLA_Deaktiv" 1 "EPS_PLA_Init" 2 "EPS_PLA_Fehler_mit_Eintrag" 3 "reserviert" 4 "reserviert" 5 "reserviert" 6 "EPS_PLA_Lenkwinkel_aktiv" 7 "EPS_PLA_Abgewiesen" 8 "EPS_PLA_Funktionsbereit" 9 "reserviert" 10 "EPS_PLA_Abbruch" 11 "reserviert" 12 "reserviert" 13 "reserviert" 14 "reserviert" 15 "reserviert" ;
VAL_ 810 EPS_Charisma_FahrPr 0 "keine_Funktion" 1 "Programm_1" 2 "Programm_2" 3 "Programm_3" 4 "Programm_4" 5 "Programm_5" 6 "Programm_6" 7 "Programm_7" 8 "Programm_8" 9 "Programm_9" 10 "Programm_10" 11 "Programm_11" 12 "Programm_12" 13 "Programm_13" 14 "Programm_14" 15 "Programm_15" ;
VAL_ 810 EPS_Charisma_Status 0 "Init" 1 "verfuegbar" 2 "nicht_verfuegbar" 3 "asynchron_durch_Fahrerwunsch" ;
VAL_ 810 EPS_Lenkerposition 0 "unbekannt" 1 "Linkslenker" 2 "Rechtslenker" ;
VAL_ 810 EPS_Anf_KL 0 "keine_Anforderung" 1 "Anforderung_Kuehlung" ;
VAL_ 810 EPS_ARA_Status 0 "EPS_ARA_Deaktiv" 1 "EPS_ARA_Init" 2 "EPS_ARA_Fehler_mit_Eintrag" 3 "reserviert" 4 "reserviert" 5 "reserviert" 6 "EPS_ARA_Lenkwinkel_aktiv" 7 "EPS_ARA_Abgewiesen" 8 "EPS_ARA_Funktionsbereit" 9 "reserviert" 10 "EPS_ARA_Abbruch" 11 "reserviert" 12 "reserviert" 13 "reserviert" 14 "reserviert" 15 "reserviert" ;
VAL_ 285 EPS_Notlauf 0 "kein_Notlauf" 1 "Notlauf_Unterspannung" 2 "Notlauf_Ueberspannung" 3 "reserviert" 4 "Notlauf_Uebertemperatur" 5 "Notlauf_Unterspannung_und_Uebertemperatur" 6 "Notlauf_Ueberspannung_und_Uebertemperatur" 7 "reserviert" 8 "reserviert" 9 "reserviert" 10 "reserviert" 11 "reserviert" 12 "reserviert" 13 "reserviert" 14 "reserviert" 15 "reserviert" ;
VAL_ 285 EPS_Lastinfo 254 "Init" 255 "Fehler" ;
VAL_ 285 EPS_Unterstuetzungsleistung 255 "Fehler" ;
VAL_ 285 EPS_Drehzahlreserve 126 "Init" 127 "Fehler" ;
VAL_ 285 EPS_VZ_Drehzahlreserve 0 "positiv" 1 "negativ" ;
VAL_ 285 EPS_Leistungsanforderung 0 "keine_Anforderung" 1 "Anforderung_hoehere_Spannung_oder_Leistung" ;
VAL_ 285 EPS_StartStopp_Info 0 "Motorlauf_nicht_notwendig_(Stoppfreigabe)" 1 "Motoranlauf_nicht_zwingend_notwendig_(Stoppverbot,keine_Startanforderung)" 2 "Motoranlauf_zwingend_notwendig_(Startanforderung)" 3 "Systemfehler" ;
VAL_ 285 EPS_Motorstartverzoegerung 0 "Motoranlauf_Freigabe" 1 "Motoranlauf_verzoegern" 3 "Systemfehler" ;
VAL_ 159 EPS_DSR_Status 0 "DSR_deaktiviert" 1 "DSR_Anforderung_nicht_ausfuehrbar" 2 "Kommunikation_ESP_gestoert" 3 "EPS_bzgl_DSR_funktionsbereit" 4 "DSR_Anforderung_abgewiesen" 5 "externer_Momenteneingriff_aktiv" 6 "externer_Lenkwinkeleingriff_aktiv" 7 "externer_Momenten_und_Lenkwinkeleingriff_aktiv" ;
VAL_ 159 EPS_Berechneter_LW 4094 "Init" 4095 "Fehler" ;
VAL_ 159 EPS_BLW_QBit 0 "gueltiger_Wert" 1 "Ersatz_Init_oder_Fehlerwert" ;
VAL_ 159 EPS_VZ_BLW 0 "positiv" 1 "negativ" ;
VAL_ 159 EPS_HCA_Status 0 "HCA_in_der_EPS_deaktiviert" 1 "HCA_Anforderung_nicht_ausfuehrbar_HCA_Fehlerstatus_Initialisierung_Ausschaltphase" 2 "Kommunikation_zum_HCA_SG_gestoert" 3 "EPS_bzgl_HCA_fuktionsbereit" 4 "HCA_Anforderung_abgewiesen_aufgrund_Fehler_in_HCA" 5 "HCA_Momenteneingriff_1_aktiv" 6 "reserviert" 7 "HCA_Momenteneingriff_2_aktiv" 8 "HCA_abgewiesen_aufgrund_Momentenpriorisierung" ;
VAL_ 159 EPS_Lenkmoment 1023 "Fehler" ;
VAL_ 159 EPS_Lenkmoment_QBit 0 "gueltiger_Wert" 1 "Ersatz_Init_oder_Fehlerwert" ;
VAL_ 159 EPS_VZ_Lenkmoment 0 "positiv" 1 "negativ" ;
VAL_ 159 EPS_Lenkungstyp 0 "RCEPS_Serie" 1 "RCEPS_Dynamiklenkung" 2 "MQB_DP" 3 "MQB_APA" 4 "MQB_Direktlenkung" 15 "unbekannt" ;
VAL_ 134 LWI_Sensorstatus 0 "iO" 1 "nicht kalibriert" ;
VAL_ 134 LWI_QBit_Sub_Daten 0 "LWS-Subinfo 'real' (Lenkradwinkelinformation ADS-tauglich) " 1 "LWS-Subinfo 'simuliert' (Lenkradwinkelinformation nicht ADS-tauglich )" ;
VAL_ 134 LWI_MFL_Abschaltung 0 "inaktiv" 1 "aktiv" ;
VAL_ 134 LWI_QBit_Lenkradwinkel 0 "gültiger Wert" 1 "ausserhalb der Spezifikation" ;
VAL_ 134 LWI_Lenkradwinkel 8190 "Init" 8191 "Fehler" ;
VAL_ 134 LWI_VZ_Lenkradwinkel 0 "positiv_links_von_der_Nullstellung" 1 "negativ" ;
VAL_ 134 LWI_VZ_Lenkradw_Geschw 0 "positiv_links_von_der_Nullstellung" 1 "negativ" ;
VAL_ 134 LWI_Lenkradw_Geschw 510 "Init" 511 "Fehler" ;
VAL_ 917 AFS_Abbiegelicht_li_Anf 0 "Abbiegelicht_aus" 1 "Abbiegelicht_ein" ;
VAL_ 917 AFS_Abbiegelicht_re_Anf 0 "Abbiegelicht_aus" 1 "Abbiegelicht_ein" ;
VAL_ 917 AFS_Abbiegelicht_Dimm_Anf 0 "Dimmung_angefordert" 1 "keine_Dimmung" ;
VAL_ 917 AFS_Verfuegbarkeit_GLW 0 "GLW_nicht_verfuegbar" 1 "GLW_verfuegbar" ;
VAL_ 917 AFS_Status_adaptive_LV 0 "adaptive_Lichtverteilung_aus" 1 "adaptive_Lichtverteilung_an" ;
VAL_ 917 AFS_Fernlicht_li_defekt 0 "Fernlicht_in_Ordnung" 1 "Fernlicht_defekt" ;
VAL_ 917 AFS_Fernlicht_re_defekt 0 "Fernlicht_in_Ordnung" 1 "Fernlicht_defekt" ;
VAL_ 917 AFS_Fernlicht_Status 0 "Fernlicht_aus" 1 "Fernlicht_ein" ;
VAL_ 917 AFS_Lampe 0 "Aus" 1 "Ein" ;
VAL_ 917 LWR_Lampe 0 "LWR Fehlerlampe aus" 1 "LWR Fehlerlampe ein" ;
VAL_ 917 AFS_Fehlertext 0 "kein Text" 1 "AFS ohne Funktion" ;
VAL_ 917 AFS_LED_Blinkmode 0 "kein Blinkmode angefordert" 1 "Blinkmode angefordert" ;
VAL_ 917 LWR_Touristenmodus_aktiv 0 "Touristenmodus inaktiv" 1 "Touristenmodus aktiv" ;
VAL_ 917 AFS_Charisma_FahrPr 0 "keine_Funktion" 1 "Programm_1" 2 "Programm_2" 3 "Programm_3" 4 "Programm_4" 5 "Programm_5" 6 "Programm_6" 7 "Programm_7" 8 "Programm_8" 9 "Programm_9" 10 "Programm_10" 11 "Programm_11" 12 "Programm_12" 13 "Programm_13" 14 "Programm_14" 15 "Programm_15" ;
VAL_ 917 AFS_Charisma_Status 0 "Init" 1 "verfuegbar" 2 "nicht_verfuegbar" 3 "asynchron_durch_Fahrerwunsch" ;
VAL_ 917 AFS_Allwetterlicht 0 "Allwetterlicht_nicht_aktiv" 1 "Allwetterlicht_aktiv" ;
VAL_ 917 LWR_Touristenmodus_verbaut 0 "Touristenmodus_nicht_verbaut" 1 "Touristenmodus_verbaut" ;
VAL_ 917 AFS_adaptive_LV_verbaut 0 "adaptive_Lichtverteilung_nicht_verbaut" 1 "adaptive_Lichtverteilung_verbaut" ;
VAL_ 917 LWR_Reisemodus_Texte 0 "keine_Anzeige" 1 "Umschaltung_auf_Linksverkehr_aktiv" 2 "Umschaltung_auf_Rechtsverkehr_aktiv" ;
VAL_ 917 GLW_Sensor_blockiert 0 "Kamera_Sensor_nicht_blockiert" 1 "Kamera_Sensor_blockiert" ;
VAL_ 917 LWR_Pos_Schrittmotor 254 "Init" 255 "Fehler" ;
VAL_ 917 LWR_Hoehenwert_VL 254 "nicht_initialisiert" 255 "Fehler" ;
VAL_ 917 LWR_Hoehenwert_HL 254 "nicht_initialisiert" 255 "Fehler" ;
VAL_ 917 AFS_Ersatzlicht_Links 0 "keine Ersatzlichtfunktion links" 1 "Ersatzlichtfunktion links" ;
VAL_ 917 AFS_Ersatzlicht_Rechts 0 "keine Ersatzlichtfunktion rechts" 1 "Ersatzlichtfunktion rechts" ;
VAL_ 917 LWR_AFS_Grundeinstellung 0 "Grundeinstellung nicht erfolgt" 1 "Grundeinstellung erfolgt" ;
VAL_ 917 LWR_AFS_Parametrisierung 0 "Parametrisierung nicht erfolgt" 1 "Parametrisierung erfolgt" ;
VAL_ 917 LWR_Initialisierungslauf 0 "Initialisierungslauf nicht erfolgt" 1 "Initialisierungslauf erfolgt" ;
VAL_ 917 LWR_Sicherheitsposition 0 "Sicherheitsposition aus" 1 "Sicherheitsposition ein" ;
VAL_ 917 LWR_Modus 0 "LWR statisch" 1 "LWR dynamisch" ;
VAL_ 1600 MO_QBit_Ansaugluft_Temp 0 "gueltiger_Wert" 1 "Ersatz_Init_oder_Fehlerwert" ;
VAL_ 1600 MO_QBit_Oel_Temp 0 "gueltiger_Wert" 1 "Ersatz_Init_oder_Fehlerwert" ;
VAL_ 1600 MO_QBit_Kuehlmittel_Temp 0 "gueltiger_Wert" 1 "Ersatz_Init_oder_Fehlerwert" ;
VAL_ 1600 MO_KL15_Abschaltempfehlung 0 "Keine Empfehlung" 1 "Abschaltempfehlung" ;
VAL_ 1600 MO_HYB_Fehler_HV_Netz 0 "i_O" 1 "kein_generatorischer_Betrieb_moeglich" ;
VAL_ 1600 MO_aktives_Getriebeheizen 0 "kein_Ventil_ansteuern" 1 "Ventil_muss_angesteuert_werden" ;
VAL_ 1600 MO_Absperrventil_oeffnen 0 "nicht_verfuegbar" 1 "Ansteuerung_Ventil_zulaessig" 2 "Ventil_oeffnen_oder_geoeffnet" 3 "Ventil_schliessen_oder_geschlossen" ;
VAL_ 1600 MO_Ansaugluft_Temp 254 "Init" 255 "Fehler" ;
VAL_ 1600 MO_Oel_Temp 253 "nicht_verbaut" 254 "Init" 255 "Fehler" ;
VAL_ 1600 MO_Kuehlmittel_Temp 254 "Init" 255 "Fehler" ;
VAL_ 1600 MO_Hoeheninfo 255 "Fehler" ;
VAL_ 1600 MO_Kennfeldk 0 "keine Kennfeldkühlung vorhanden" 1 "Kennfeldkühlung vorhanden" ;
VAL_ 1600 MO_Versionsinfo_02 0 "zum_Projektbeginn_aufgeraeumter_CAN" 1 "Motor_03_mit_10ms" 16 "MQB_mit_neuer_Momentenschnittstelle" ;
VAL_ 1600 MO_QBit_Hoeheninfo 0 "gueltiger_Wert" 1 "Ersatz_Init_oder_Fehlerwert" ;
VAL_ 1600 MO_Getriebe_kuehlen 0 "nicht_kuehlen" 1 "kuehlen" ;
VAL_ 1600 MO_Heizungspumpenansteuerung 13 "Fehler" 14 "Init" 15 "nicht_verbaut" ;
VAL_ 1600 MO_SpannungsAnf 0 "keine_Anforderung" 1 "Anforderung" ;
VAL_ 167 MO_Mom_Soll_Roh 1022 "Init" ;
VAL_ 167 MO_Mom_Ist_Summe 1022 "Init" ;
VAL_ 167 MO_Mom_Traegheit_Summe 1022 "Init" ;
VAL_ 167 MO_Mom_Soll_gefiltert 1022 "Init" ;
VAL_ 167 MO_Mom_Schub 510 "Init" ;
VAL_ 167 MO_Status_Normalbetrieb_01 0 "kein_Normalbetrieb" 1 "Normalbetrieb_erreicht" ;
VAL_ 167 MO_erste_Ungenauschwelle 0 "genau" 1 "Momente ungenauer >8%" ;
VAL_ 167 MO_QBit_Motormomente 0 "gueltiger_Wert" 1 "Ersatz_Init_oder_Fehlerwert" ;
VAL_ 168 MO_Mom_neg_verfuegbar 510 "Init" 511 "Fehler" ;
VAL_ 168 MO_Mom_Begr_Fahr 510 "Init" 511 "Fehler" ;
VAL_ 168 MO_Mom_Begr_Schalt 1022 "Init" ;
VAL_ 168 MO_QBit_Drehzahl_01 0 "gueltiger_Wert" 1 "Ersatz_Init_oder_Fehlerwert" ;
VAL_ 958 MO_StartStopp_Status 0 "System_in_diesem_KL15_Zyklus_nicht_verfuegbar" 1 "System_aktiv_keine_Freigabe_durch_StartStop_Koordinator" 2 "System_aktiv_alle_Freigaben_liegen_vor" 3 "System_aktiv_mindestens_eine_Freigabe_fehlt" ;
VAL_ 958 MO_StartStopp_Wiederstart 0 "Wiederstart_inaktiv" 1 "Wiederstart_aktiv" ;
VAL_ 958 MO_StartStopp_Motorstopp 0 "Motor_Stop_inaktiv" 1 "Motor_Stop_aktiv" ;
VAL_ 958 MO_Freig_Reku 0 "Rekuperations-Modus aus" 1 "Empfehlung Spannungsanhebung" 2 "Empfehlung Spannungsabsenkung" 3 "Rekuperationsmodus aktiv, Spannungsvariation nicht notwendig" ;
VAL_ 958 MO_Kl_75 0 "Aus" 1 "Ein" ;
VAL_ 958 MO_Kl_50 0 "aus" 1 "KL50_ein_Startausfuehrung_Fahrer" ;
VAL_ 958 MO_Gangposition 0 "Gang_N" 1 "Gang_1" 2 "Gang_2" 3 "Gang_3" 4 "Gang_4" 5 "Gang_5" 6 "Gang_6" 7 "Gang_7" 8 "Gang_8" 9 "Automat_P" 10 "Automat_Vorwaerts_S" 11 "Automat_Vorwaerts_D/E" 12 "Zwischenstellung" 13 "Gang_R" 14 "Istgang_nicht_definiert" 15 "Fehler" ;
VAL_ 958 MO_StartStopp_Fahrerwunsch 0 "Init" 1 "Stoppverbot_durch_Fahrer" 2 "Stoppfreigabe_durch_Fahrer" 3 "Stoppanforderung_durch_Fahrer" ;
VAL_ 958 MO_HYB_Fahrbereitschaft 0 "keine_Fahrbereitschaft" 1 "Fahrbereitschaft" ;
VAL_ 958 MO_Ext_E_Fahrt_aktiv 0 "Rueckmeldung_E_Taster_aus" 1 "Rueckmeldung_E_Taster_ein" ;
VAL_ 958 MO_Fahrer_bremst 0 "kein_Bremsen" 1 "Bremse_betaetigt" ;
VAL_ 958 MO_QBit_Fahrer_bremst 0 "gueltiger_Wert" 1 "Ersatz_Init_oder_Fehlerwert" ;
VAL_ 958 MO_BLS 0 "kein_Bremsen" 1 "Bremse_betaetigt" ;
VAL_ 958 MO_Konsistenz_Bremsped 0 "Bremspedalinformation_plausibel" 1 "Bremspedalinformation_unplausibel" ;
VAL_ 958 MO_Timeout_ESP 0 "Empfang_iO" 1 "Timeout" ;
VAL_ 958 MO_Klima_Eingr 0 "kein Eingriff" 1 "Klimakompressor ausschalten" 2 "Klimakompressor Leistungsreduzierung" 3 "Klimakompressor aufgrund der Heissleuchtenvorwarnung ausschalten" ;
VAL_ 958 MO_Aussp_Anlass 0 "Anlasser_darf_angesteuert_werden" 1 "Anlasser_ausspuren__Ansteuerung_nicht_moeglich" ;
VAL_ 958 MO_Freig_Anlass 0 "Start_nicht_zulaessig" 1 "Startfreigabe" ;
VAL_ 958 MO_Kuppl_schalter 0 "Schalter_sagt_ausgekuppelt" 1 "Schalter_sagt_eingekuppelt" ;
VAL_ 958 MO_Interlock 0 "Interlockschalter_nicht_betaetigt" 1 "Interlockschalter_betaetigt" ;
VAL_ 958 MO_Motor_laeuft 0 "Motor_laeuft_nicht" 1 "Motor_laeuft_autark_und_stabil_und_darf_mechanisch_belastet_werden" ;
VAL_ 958 MO_Kickdown 0 "kein_Kickdown" 1 "Kickdown" ;
VAL_ 958 MO_QBit_KL_75 0 "gueltiger_Wert" 1 "Ersatz_Init_oder_Fehlerwert" ;
VAL_ 958 MO_EKlKomLeiRed 0 "keine_Leistungsbegr" 1 "Leistungsbegr_75" 2 "Leistungsbegr_50" 3 "Leistungsbegr_25" ;
VAL_ 958 MO_Handshake_STH 0 "keine EKP-Ansteuerung durch STH-Anforderung" 1 "EKP-Ansteuerung durch STH-Anforderung" ;
VAL_ 958 MO_BKV_Unterdruckwarnung 0 "Unterdruckhaushalt_iO" 1 "Unterdruckhaushalt_niO" ;
VAL_ 958 MO_Freigabe_Segeln 0 "Segelbetrieb_nicht_freigegeben" 1 "Segelbetrieb_freigegeben" ;
VAL_ 958 MO_PTC_Status 0 "nicht_unterstuetzt" 1 "Stufe_0" 2 "Stufe_1" 3 "Stufe_2" 4 "Stufe_3" 7 "PTC_am_BCM" ;
VAL_ 958 MO_QBit_Gangposition 0 "gueltiger_Wert" 1 "Ersatz_Init_oder_Fehlerwert" ;
VAL_ 958 MO_Signalquelle_Gangposition 0 "Sensorsignal" 1 "Modellsignal" ;
VAL_ 958 MO_Remotestart_Betrieb 0 "MSG_nicht_bereit_fuer_RS_Betrieb" 1 "MSG_bereit_fuer_oder_im_RS_Betrieb" ;
VAL_ 958 MO_Remotestart_moeglich 0 "Remotestart_nicht_moeglich" 1 "Remotestart_moeglich" ;
VAL_ 958 MO_FMAus_aktiv 0 "inaktiv" 1 "Segeln_mit_Motor_aus_aktiv" ;
VAL_ 958 MO_FMAus_Startvariante 0 "kein_Motorstart" 1 "Motorstart_elektrischer_Starter" 2 "GetriebeAnschleppstart" 3 "GetriebeNotAnschleppstart" ;
VAL_ 958 MO_BMS_NV_Anf_stuetzen 0 "nicht_notwendig" 1 "notwendig" ;
VAL_ 958 MO_Zylinderabschaltung 0 "Vollmotorbetrieb_VMB" 1 "Uebergang_HMB_in_VMB" 2 "Uebergang_VMB_in_HMB" 3 "Halbmotorbetrieb_HMB" ;
VAL_ 958 MO_HYB_VM_aktiv 0 "VM_nicht_aktiv" 1 "VM_aktiv" ;
VAL_ 958 MO_StartVorauss_erfuellt 0 "Signal_nicht_bedient" 1 "StartVorauss_nicht_ueberpruefbar" 2 "StartVorauss_nicht_erfuellt" 3 "StartVorauss_erfuellt" ;
VAL_ 1631 TSK_QBit_Steigung 0 "gueltiger_Wert" 1 "Ersatz_Init_oder_Fehlerwert" ;
VAL_ 1631 TSK_QBit_Fahrzeugmasse 0 "gueltiger_Wert" 1 "Ersatz_Init_oder_Fehlerwert" ;
VAL_ 1631 MO_SpannungsAnf_02 0 "keine_Anforderung" 1 "Anforderung_Stufe_1" 2 "Anforderung_Stufe_2" 3 "Anforderung_Stufe_3" ;
VAL_ 1631 MO_DPF_reg 0 "DPF_regeneriert_nicht" 1 "DPF_regeneriert" ;
VAL_ 1631 MO_Heizstrom_EKAT 127 "Fehler" ;
VAL_ 1631 MO_Heizstrom_SCR 63 "Fehler" ;
VAL_ 1631 MO_Testmode_AG 0 "kein_Pruefstandsbetrieb" 1 "Pruefstandsbetrieb" ;
VAL_ 1631 TSK_Getriebeinfo 0 "Handschalter" 1 "AL_AQ_Getriebe" 2 "DL_DQ_Getriebe" 3 "CVT_Getriebe" ;
VAL_ 1631 MO_Energieinhalt_BMS 4094 "Init" 4095 "Fehler" ;
VAL_ 1631 TSK_Fahrzeugmasse_02 255 "Fehler" ;
VAL_ 1631 TSK_Steigung_02 0 "Init_oder_nicht_verbaut" 255 "Fehler" ;
VAL_ 1648 MO_ANC_Kennfeld_Anf 0 "Kennfeld_1" 1 "Uebergang_Kennfeld_2_nach_1" 2 "Uebergang_Kennfeld_1_nach_2" 3 "Kennfeld_2" ;
VAL_ 1648 MO_Bremslicht_Reku 0 "Aus" 1 "Ein" ;
VAL_ 1648 MO_StartStopp_PopUp 0 "Statuswechsel_ohne_Taster (Init)" 1 "StSt_per_Taster_deaktiviert" 2 "StSt_per_Taster_aktiviert" 3 "nicht verwendet" ;
VAL_ 1648 MO1_Sperr_Info_WFS 0 "nicht_gesperrt" 1 "gesperrt" ;
VAL_ 1648 MO1_Freigabe_Info_WFS 0 "ungueltig" 1 "gueltig" ;
VAL_ 1648 MO_EPCL 0 "EPCL_aus_kein_Text" 1 "EPCL_gelb_Stoerung" 2 "EPCL_gelb_Leistungsbeschraenkung" 3 "EPCL_rot_Fzg_sicher_abstellen" ;
VAL_ 1648 MO_Zylabsch_Texte_02 0 "ein_ZAS_generell_keine_ZAS_Anzeigen" 1 "ZAS_im_VMB" 2 "ZAS_im_ASB_1_Zyl_aktiv" 3 "ZAS_im_ASB_2_Zyl_aktiv" 4 "ZAS_im_ASB_3_Zyl_aktiv" 5 "ZAS_im_ASB_4_Zyl_aktiv" 6 "ZAS_im_ASB_5_Zyl_aktiv" 7 "ZAS_im_ASB_6_Zyl_aktiv" 8 "ZAS_im_ASB_8_Zyl_aktiv" 9 "ZAS_im_ASB_12_Zyl_aktiv" 13 "Uebergangsbetrieb" 14 "keine_ZAS_Anzeige_ggf_Stopp_Schub_Betrieb" 15 "ZAS_Stoerungs_Anzeige" ;
VAL_ 1648 MO_Fahrzeugtyp 0 "Verbrenner_Fahrzeug" 1 "Hybrid" 2 "E_Fahrzeug" 3 "E_Fahrzeug_mit_Range_Extender" 4 "tbd" 5 "tbd" 6 "tbd" 7 "tbd" ;
VAL_ 1648 MO_Abstellzeit 254 "reserviert" 255 "reserviert" ;
VAL_ 1648 MO_Abstellzeit_Status 0 "Abstellzeit_nicht_berechnet" 1 "Abstellzeit_berechnet" 2 "Abstellzeit_Minimalwert" 3 "Abstellzeit_ungueltig" ;
VAL_ 1648 MO1_Freigabe_Verfallsinfo_WFS 0 "verfaellt_nicht" 1 "verfaellt" ;
VAL_ 1648 MO_Hybrid_StartStopp_LED 0 "LED_aus_und_Blinken_aus" 1 "LED_ein_und_Blinken_aus" 2 "LED_ein_und_Blinken_ein_50_percent" 3 "reserviert" ;
VAL_ 1648 MO_Fehler_Zylabsch 0 "kein_Fehler" 1 "Notlauf_Vollmotorbetrieb" 2 "Notlauf_mindestens_einem_abgesch_Zylinder" ;
VAL_ 1648 MO_Anzahl_Abgesch_Zyl 0 "Vollmotorbetrieb" 1 "1_Zylinder_abgeschaltet" 2 "2_Zylinder_abgeschaltet" 3 "3_Zylinder_abgeschaltet" 4 "4_Zylinder_abgeschaltet" 5 "5_Zylinder_abgeschaltet" 6 "6_Zylinder_abgeschaltet" 7 "8_Zylinder_abgeschaltet" ;
VAL_ 1648 MO_Zylabsch_Texte 0 "keine_Texte" 1 "Zylinderabschaltung_deaktivieren" 2 "Zylinderabschaltung_aktivieren" 3 "Zylinderabschaltung_unruhig" ;
VAL_ 1648 MO_Ethanol_BS_Texte 0 "kein_Text" 1 "E85_Warm_Up" 2 "FlexFuel_Warnung_Stufe_3" 3 "Warmfahrempfehlung_MQB__FlexFuel_Warnung_Stufe_1" 4 "FlexFuel_Warnung_Stufe_2" 5 "FlexFuel_Warnung_Stufe_4" 6 "E25_Warm_Up" ;
VAL_ 1648 MO_Drehzahl_Warnung 0 "keinen_Warnhinweis_anzeigen" 1 "Warnhinweis_anzeigen" ;
VAL_ 1648 MO_obere_Drehzahlgrenze 0 "Init" ;
VAL_ 289 MO_Fahrpedalrohwert_01 255 "Fehler" ;
VAL_ 289 MO_QBit_Fahrpedalwerte_01 0 "gueltiger_Wert" 1 "Ersatz_Init_oder_Fehlerwert" ;
VAL_ 289 MO_Fahrpedalgradient 255 "Fehler" ;
VAL_ 289 MO_Sig_Fahrpedalgradient 0 "Fahrpedalgradient positiv" 1 "Fahrpedalgradient negativ" ;
VAL_ 289 MO_rel_Saugrohrdruck 0 "Init_Ueberdruck" 63 "Fehler" ;
VAL_ 289 MO_rel_Saugrohrdruck_gem_err 0 "errechnet" 1 "gemessen" ;
VAL_ 289 MO_Moment_im_Leerlauf 0 "kein_Leergas" 1 "Leergas" ;
VAL_ 289 MO_Schubabschaltung 0 "keine_Schubabschaltung" 1 "Schubabschaltung_aktiv" ;
VAL_ 289 MO_StartStopp_StoppVorbereitung 0 "Motorstopp_nicht_in_Vorbereitung" 1 "Motorstopp_in_Vorbereitung" ;
VAL_ 289 MO_Entkopplung_Sollschlupf 125 "Notoeffnen_Anfahrelement" 126 "Init" ;
VAL_ 289 MO_temporaere_Fahrerabwesenheit 0 "nicht_erkannt" 1 "erkannt" ;
VAL_ 289 TSK_a_Soll_gradientenbegrenzt 127 "Init_oder_nicht_aktiv" ;
VAL_ 283 MO_Fahrbereitschaft 0 "Fahrzykl_inaktiv__kein_Antrieb" 1 "Fahrzykl_aktiv__kein_Antrieb" 2 "Fahrzykl_aktiv__Antrieb_moeglich" ;
VAL_ 283 MO_Freilauf_Info 0 "Freilauf_freigegeben" 1 "Uebergang_in_Freilauf_unzulaessig" 2 "Freilauf_nicht_freigegeben_Abbruch" 3 "Freilauf_Anforderung" ;
VAL_ 283 MO_EnergyAssist_Aktivierbar 0 "AEA_nicht_aktivierbar" 1 "AEA_aktivierbar" ;
VAL_ 283 MO_Krit_Heckobjekt 0 "Init_kein_relevantes_Objekt" 1 "Entfernung_grosser_Abstand" 2 "Annaeherung_grosser_Abstand" 3 "Entfernung_geringer_Abstand" 4 "Annaeherung_geringer_Abstand" 7 "Fehler" ;
VAL_ 283 MO_NGS_Gangpos 0 "nicht_bedient" 1 "1_3_oder_5" 2 "2_4_6_oder_R" 3 "R" 4 "Neutralposition" 5 "Zwischenposition" 6 "Sensor_temp_nicht_verfuegbar" 7 "Fehler" ;
VAL_ 283 MO_Freilauf_Status 0 "Freilauf_inaktiv_aber_moeglich" 1 "Freilauf_aktiv" 2 "Freilauf_nicht_moegl_1Verhinderer" 3 "Freilauf_nicht_moegl_gr_1Verhinderer" 7 "Fehler" ;
VAL_ 283 MO_EBoost_verf_praed 0 "Init_oder_nicht_verfuegbar" 1 "EBoost_kurzzeit_verfuegbar" 2 "EBoost_langzeit_verfuegbar" ;
VAL_ 283 MO_Heckspoiler_Anf 0 "nicht_angefordert" 1 "angefordert" ;
VAL_ 283 MO_eLaunch_verf 0 "Init" 1 "nicht_verfuegbar" 2 "verfuegbar" ;
